VERSION "1.11.2"

NS_ :

BS_:

BU_: TCU BRK ESP MCU RDD GP TMS GW KPD1 RDE FNR ECU KPD2 ATSGO ACU IMU1 IMU2 IMU3 IMU4 IMU5 AGW PMI HDOQS EGOQS OBC EEC CBSW EJRH EJLH EPDLT EPDL2 EPDLR EPDLA TRBDZ ECU1 CLST LC510 EGDL JS SMB KPAC ACCU Audio TGU RDRR RDLH RDRH AVM CHMSL CTC SMK EVC MCU2 PHM MC3D AMBLMP RCTGU RDU PT3D XCU can1 can2
VAL_TABLE_ BOOL 3 "NOT_AVAILABLE" 2 "ERROR" 1 "TRUE" 0 "FALSE" ;
VAL_TABLE_ PWRDNCMD 3 "NOT_AVAILABLE" 2 "EMERGENCY_POWER_DOWN" 1 "NORMAL_POWER_DOWN" 0 "NOT_REQUEST" ;
VAL_TABLE_ OFFON 3 "NOT_AVAILABLE" 2 "ERROR" 1 "ON" 0 "OFF" ;
VAL_TABLE_ NONEOFFON 3 "NOT_AVAILABLE" 2 "ON" 1 "OFF" 0 "NONE" ;
VAL_TABLE_ MACHINESTATUS 3 "NOT_AVAILABLE" 2 "KEY_OFF_CHARGING" 1 "KEY_ON" 0 "KEY_OFF" ;
VAL_TABLE_ CHARGINGSTATUS 5 "EVSE_SIGNOT_AVAILABLEL_WARNING" 4 "AC_VOLTAGE_BELOW_NORMAL" 3 "AC_VOLTAGE_ABOVE_NORMAL" 2 "CHARGING_GUN_WARNING" 1 "CHARGING_PORT_WARNING" 0 "CHARGING" ;
VAL_TABLE_ WRNLAMP 3 "SLOW_BLINKING" 2 "BLINKING" 1 "ON" 0 "OFF" ;
VAL_TABLE_ WRNLAMPTXT 15 "SLOW_BLINKING_TEXT4" 14 "BLINKING_TEXT4" 13 "ON_TEXT4" 12 "NOT_DEFINED3" 11 "SLOW_BLINKING_TEXT2" 10 "BLINKING_TEXT2" 9 "ON_TEXT2" 8 "NOT_DEFINED2" 7 "SLOW_BLINKING_TEXT3" 6 "BLINKING_TEXT3" 5 "ON_TEXT3" 4 "NOT_DEFINED1" 3 "SLOW_BLINKING_TEXT1" 2 "BLINKING_TEXT1" 1 "ON_TEXT1" 0 "OFF" ;
VAL_TABLE_ ANTDETECT 2 "SHORTED" 1 "REMOVAL" 0 "NORMAL" ;
VAL_TABLE_ TRVMODECR 3 "NOT_AVAILABLE" 2 "AUTO_SPEED" 1 "HIGH_SPEED" 0 "LOW_SPEED" ;
VAL_TABLE_ WRKMODE 3 "RESERVED" 2 "TWO_WAY" 1 "BREAKER" 0 "NOT_DEFINED" ;
VAL_TABLE_ GPSST 3 "3D" 2 "2D" 1 "NO_FIX" 0 "UNKNOWN" ;
VAL_TABLE_ SMKFOBREG 3 "FAIL2" 2 "FAIL1" 1 "SUCCESS" 0 "NORMAL" ;
VAL_TABLE_ SMKFOBDET 1 "DETECT_REQUEST" 0 "DEFAULT" ;
VAL_TABLE_ SMKFOBIDREQ 1 "REQUEST" 0 "DEFAULT" ;
VAL_TABLE_ CMDONOFF 3 "NOT_AVAILABLE" 2 "OFF" 1 "ON" 0 "NO_ACTION" ;
VAL_TABLE_ EGSTARTCMD 3 "KEY_ON" 2 "ENGINE_OFF" 1 "ENGINE_ON" 0 "NONE" ;
VAL_TABLE_ COLDSTART 8 "TEST_OF_GRID_HEATER_VOLTAGE" 7 "INITIALIZATION_PHASE" 6 "POST_HEATING_PHASE" 5 "CRANK_WITH_EXTRA_HEATING_PHASE" 4 "CRANK_PHASE" 3 "STAND_BY_PHASE_WITHOUT_HEATING" 2 "STAND_BY_PHASE_WITH_HEATING" 1 "PRE_HEATING_PHASE" 0 "OFF_PHASE_HEAT_OFF_AND_LAMP_OFF" ;
VAL_TABLE_ FUELBLOCK 1 "FUEL_BLOCKED" 0 "FUEL_RELEASED" ;
VAL_TABLE_ LAMPST 3 "NOT_AVAILABLE" 2 "BLINKING" 1 "ON" 0 "OFF" ;
VAL_TABLE_ WRNHIGH 3 "NOT_AVAILABLE" 2 "RESERVED" 1 "ABOVE_OPERATION_RANGE" 0 "NORMAL" ;
VAL_TABLE_ LAMPBITST 4 "BLINKING" 1 "ON" 0 "OFF" ;
VAL_TABLE_ WRNLOW 3 "NOT_AVAILABLE" 2 "RESERVED" 1 "BELOW_OPERATION_RANGE" 0 "NORMAL" ;
VAL_TABLE_ WRN 3 "NOT_AVAILABLE" 2 "RESERVED" 1 "WARNING" 0 "NORMAL" ;
VAL_TABLE_ EDCOPRST 2 "DIAGNOSTIC_TEST" 1 "AFTERRUN_DRIVE" 0 "NORMAL_OPERATION" ;
VAL_TABLE_ PTOST 31 "NOT_AVAILABLE" 19 "PTO_SET_SPEED_MEMORY_2" 18 "PTO_SET_SPEED_MEMORY_1" 17 "PREPROGRAMMED_SET_SPEED_8" 16 "PREPROGRAMMED_SET_SPEED_7" 15 "PREPROGRAMMED_SET_SPEED_6" 14 "PREPROGRAMMED_SET_SPEED_5" 13 "PREPROGRAMMED_SET_SPEED_4" 12 "PREPROGRAMMED_SET_SPEED_3" 11 "PREPROGRAMMED_SET_SPEED_2" 10 "PREPROGRAMMED_SET_SPEED_1" 9 "ACCELERATOR_OVERRIDE" 8 "ACCELERATE" 7 "RESUME" 6 "DECELERATE_COAST" 5 "SET" 4 "REMOTE_STANDBY" 3 "STANDBY" 2 "REMOTE_HOLD" 1 "HOLD" 0 "OFF_DISABLED" ;
VAL_TABLE_ DPFACTREGENST 3 "NOT_AVAILABLE" 2 "REGENERATION_NEEDED" 1 "ACTIVE" 0 "NOT_ACTIVE" ;
VAL_TABLE_ DPFACTREGENIHBSW 3 "NOT_AVAILABLE" 1 "INHIBITED" 0 "NOT_INHIBITED" ;
VAL_TABLE_ ATDEFPPT 15 "NOT_AVAILABLE" 14 "ERROR" 13 "NOT_ABLE_TO_DETERMINE" 3 "DEF_IS_PROPER_MIXTURE" 2 "FLUID_IS_DIESEL" 1 "UREA_CONCENTRATION_TOO_LOW" 0 "UREA_CONCENTRATION_TOO_HIGH" ;
VAL_TABLE_ ATSELCATALREDOPRINDACT 7 "NOT_AVAILABLE" 4 "BLINKING" 1 "ON" 0 "OFF" ;
VAL_TABLE_ ATGASSSHTCONT 3 "HEATER_OFF" 2 "PREHEAT_1" 1 "PREHEAT_2" 0 "AUTOMATIC" ;
VAL_TABLE_ EGOVRCONTMD 3 "SPEED_TORQUE_LIMIT_CONTROL" 2 "TORQUE_CONTROL" 1 "SPEED_CONTROL" 0 "OVERRIDE_DISABLED" ;
VAL_TABLE_ PRI 3 "LOW" 2 "MEDIUM" 1 "HIGH" 0 "HIGHEST" ;
VAL_TABLE_ TRACTIONCONT 4 "AUTO" 3 "HIGH" 2 "MEDIUM" 1 "LOW" 0 "OFF" ;
VAL_TABLE_ POWMD 3 "NOT_AVAILABLE" 2 "PWR" 1 "STD" 0 "ECO" ;
VAL_TABLE_ MAXSPD 5 "SPEED_5" 4 "SPEED_4" 3 "SPEED_3" 2 "SPEED_2" 1 "SPEED_1" 0 "NEUTRAL" ;
VAL_TABLE_ RPMREQMD 3 "NONE" 1 "LIMPHOME" 0 "AUTOIDLE" ;
VAL_TABLE_ NFR 3 "TCU_REQUIRES_N_POSITION" 2 "R" 1 "F" 0 "N" ;
VAL_TABLE_ GRST 7 "LIMP_HOME" 6 "GEAR_6" 5 "GEAR_5" 4 "GEAR_4" 3 "GEAR_3" 2 "GEAR_2" 1 "GEAR_1" 0 "NEUTRAL" ;
VAL_TABLE_ OPMD 6 "TCU_IDLE" 5 "TCU_KEY_OFF" 4 "TCU_SHUTDOWN" 3 "TRANSMISSION_SHUTDOWN" 2 "LIMP_HOME" 1 "SUBSTITUTE_CLUTCH_CONTROL" 0 "NORMAL" ;
VAL_TABLE_ MCHKEYONST 3 "NOT_DEFINED" 2 "KEY_OFF_CHARGING" 1 "KEY_ON" 0 "KEY_OFF" ;
VAL_TABLE_ CHRGST 5 "EVSE_SIGNOT_AVAILABLEL_WARNING" 4 "AC_VOLTAGE_BELOW_NORMAL" 3 "AC_VOLTAGE_ABOVE_NORMAL" 2 "CHARGING_GUN_WARNING" 1 "CHARGING_PORT_WARNING" 0 "CHARGING" ;
VAL_TABLE_ TRVMDCRW 3 "NOT_AVAILABLE" 2 "AUTO_SPEED" 1 "HIGH_SPEED" 0 "LOW_SPEED" ;
VAL_TABLE_ TWOWAYOPT 2 "OPTION_PEDAL" 1 "JOYSTICK_THUMB_WHEEL" 0 "NOT_DEFINED" ;
VAL_TABLE_ ISOBHL 2 "BHL" 1 "ISO" 0 "OFF" ;
VAL_TABLE_ TRVMDWHL 3 "NOT_DEFINED" 2 "3" 1 "2" 0 "1" ;
VAL_TABLE_ HHMNTLGC 3 "4000M_EXCEED" 2 "4000M_OR_LESS" 1 "3000M_OR_LESS" 0 "OFF" ;
VAL_TABLE_ BRAKERACT 3 "NOT_AVAILABLE" 2 "FORCED_STOP" 1 "RUNNING" 0 "STOP" ;
VAL_TABLE_ TRVMDWLD 3 "NOT_DEFINED" 2 "AUTO_SPEED_2" 1 "AUTO_SPEED_1" 0 "MANUAL" ;
VAL_TABLE_ HSTMDWLD 3 "NOT_DEFINED" 2 "SLIP" 1 "AUTO" 0 "MAX" ;
VAL_TABLE_ OPRPOWMD 11 "P_SMART_HCE" 10 "AP_HCE" 9 "HP_HCE" 8 "P_HCE" 7 "E_HCE" 6 "L_HCE" 5 "I_HCE" 4 "P_PLUS_HDI" 3 "A_HDI" 2 "E_HDI" 1 "S_HDI" 0 "P_HDI" ;
VAL_TABLE_ OPRMD 1 "DIGGING" 0 "NORMAL" ;
VAL_TABLE_ COLDSTART_MCU 7 "NORMAL_BLINKING" 6 "SLOW_BLINKING" 5 "FAULT_WHILE_PRE_HEATING" 4 "PARKING_BRAKE_FOR_PRE_HEATING" 3 "NO_FOOT_ON_PDL_FOR_PRE_HEAT" 2 "GEAR_NEUTRAL_FOR_PRE_HEATING" 1 "TRSM_PRE_HEATING" 0 "OFF" ;
VAL_TABLE_ WHLDRVMD 3 "ALIGNCOMPLETE" 2 "REARALIGNREQ" 1 "FRONTALIGNREQ" 0 "OFF" ;
VAL_TABLE_ VHCSTSYMB 3 "YELLOW" 2 "GREEN" 1 "GREY" 0 "OFF" ;
VAL_TABLE_ DAC 5 "SUSPEND_AUTO" 4 "INTERLOCK" 3 "AUTO" 2 "MANUAL" 1 "STAND_BY" 0 "NOT_READY" ;
VAL_TABLE_ CHMSL 6 "OBJECT_SENSING_FAST_FLASHING" 5 "SWING_LEFT" 4 "SWING_RIGHT" 3 "WORKING_STATUS_FLASHING" 2 "STANDBY_WORKING_CONTINUOUS" 1 "BRAKE_ON" 0 "OFF" ;
VAL_TABLE_ MCHCOND 3 "STANDSTILL_CONDITION" 2 "ERROR" 1 "WORKING_CONDITION" 0 "IDLE_CONDITION" ;
VAL_TABLE_ PILOTCUTOFFST 3 "NOT_AVAILABLE" 2 "AUTO_LOCK" 1 "MANUAL_LOCK" 0 "UNLOCK" ;
VAL_TABLE_ BODYST 3 "NOT_DEFINED" 2 "FLOAT" 1 "HOLD" 0 "OFF" ;
VAL_TABLE_ ECOSYMBOL 3 "WHITE" 2 "RED" 1 "YELLOW" 0 "GREEN" ;
VAL_TABLE_ PROGRESS 3 "NOT_AVAILABLE" 2 "COMPLETE" 1 "IN_PROGRESS" 0 "NONE" ;
VAL_TABLE_ PROGRESS2 1 "COMPLETE" 0 "IN_PROGRESS" ;
VAL_TABLE_ MANAUTO 3 "NOT_AVAILABLE" 2 "ERROR" 1 "AUTO" 0 "MANUAL" ;
VAL_TABLE_ ADMINSET 4 "ENTERTAINMENT_RESTRICT" 2 "ATTACHMENT" 1 "IGNITION_LOCK" 0 "NONE" ;
VAL_TABLE_ UPTIME 3 "NOT_AVAILABLE" 2 "5MIN" 1 "1MIN" 0 "ALWAYS" ;
VAL_TABLE_ HYDELEC 2 "ELECTRONIC" 1 "ELECTRIC" 0 "HYDRAULIC" ;
VAL_TABLE_ JOYPDL 2 "OPTION_PEDAL" 1 "JOYSTICK" 0 "NOT_AVAILABLE" ;
VAL_TABLE_ THMBWHL 2 "FAST" 1 "NORMAL" 0 "SLOW" ;
VAL_TABLE_ MULTIFUNC 7 "NOT_DEFINED" 6 "FRONT_LIMITATION" 5 "AUTO_BREAKER" 4 "AUDIO_MUTE" 3 "RAM_LOCK__STATUS_CHANGE" 2 "CAMERA_VIEW_MODE_CHANGE" 1 "SMART_BOOM_CUT" 0 "WIPER_ON" ;
VAL_TABLE_ EMSCTRL 128 "NOT_AVAILABLE" 5 "NR4" 4 "STAGEV" 3 "TIER4F" 2 "TIER4I" 1 "TIER3" 0 "TIER2" ;
VAL_TABLE_ MCHGEN 224 "D" 133 "G" 132 "SD" 131 "S" 130 "K" 129 "H" 128 "DL" 108 "AGK" 96 "JD" 5 "W" 4 "B" 3 "C" 2 "V" 1 "U" 0 "DX" ;
VAL_TABLE_ MCHTYPE 14 "ADT" 13 "ROAD_BUILDER" 12 "COMPACT_TRACK_LOADER" 11 "DRILL_RIG" 10 "MATERIAL_HANDLER_WHEEL" 9 "MATERIAL_HANDLER" 8 "DOZER" 7 "LOADER" 6 "WHEEL" 5 "MOUNTAIN" 4 "ZERO_TAIL" 3 "REDUCED_TAIL" 2 "LOGLOADER" 1 "LONG_CRAWLER" 0 "CRAWLER" ;
VAL_TABLE_ EGMAKER 10 "WEICHAI" 9 "KUBOTA" 8 "DAEDONG" 7 "YANMAR" 5 "ISUZU" 4 "PERKINS" 3 "CUMMINS" 2 "SCANIA" 1 "DEVELON" 0 "NONE" ;
VAL_TABLE_ ECUMAKER 15 "ECU_MAKER_2" 14 "KUBOTA" 13 "BOSCH_DX05_DX08" 12 "PERKINS_2506J_UNIFIED" 11 "WEIFU" 10 "BOSCH_EDC7" 9 "WOODWARD" 8 "PERKINS_1204J" 7 "HITACHI" 6 "BOSCH_G2" 5 "ISUZU" 4 "PERKINS_2506J" 3 "CUMMINS" 2 "SCANIA" 1 "BOSCH_DL06_DL08" 0 "NONE" ;
VAL_TABLE_ PMPTYPE 4 "LS" 3 "VBO" 2 "OPEN_CENTER" 1 "POSICON" 0 "NEGACON" ;
VAL_TABLE_ MECHELEC 1 "ELECTRIC" 0 "MECHANIC" ;
VAL_TABLE_ MCVCTRLTYPE 2 "FEH" 1 "VBO" 0 "MECHANIC" ;
VAL_TABLE_ TCUTYPE 3 "HDT_LEVEL1" 2 "CVT" 1 "HST" 0 "HDT" ;
VAL_TABLE_ REGION 4 "US" 3 "EMERGING" 2 "ADVANCED" 1 "CHINA" 0 "KOREA" ;
VAL_TABLE_ BTN 3 "NOT_AVAILABLE" 2 "PROPOTIONOT_AVAILABLEL" 1 "TOGGLE" 0 "PUSH" ;
VAL_TABLE_ GYR 2 "RED" 1 "YELLOW" 0 "GREEN" ;
VAL_TABLE_ WGHST 5 "CONFIRM_TRUCK_TIP_OFF" 4 "ESTIMATE_TRUCK_TIP_OFF" 3 "COMPLETE" 2 "CONFIRM" 1 "ESTIMATE" 0 "READY" ;
VAL_TABLE_ WGHCNTST 3 "NOT_DEFINED" 2 "RETURN" 1 "CANCEL" 0 "OFF" ;
VAL_TABLE_ STAGE 15 "ERROR" 14 "SUCCESS" 13 "LAST_STAGE_CONFIRM" 12 "STAGE_11" 11 "STAGE_10" 10 "STAGE_9" 9 "STAGE_8" 8 "STAGE_7" 7 "STAGE_6" 6 "STAGE_5" 5 "STAGE_4" 4 "STAGE_3" 3 "STAGE_2" 2 "STAGE_1" 1 "STAGE_0" 0 "RESERVED" ;
VAL_TABLE_ STEP 15 "STEP14" 14 "STEP13" 13 "STEP12" 12 "STEP11" 11 "STEP10" 10 "STEP9" 9 "STEP8" 8 "STEP7" 7 "STEP6" 6 "STEP5" 5 "STEP4" 4 "STEP3" 3 "STEP2" 2 "STEP1" 1 "STEP0" 0 "READY" ;
VAL_TABLE_ GRADEOFFSETSW 15 "NOT_AVAILABLE" 14 "ERROR" 2 "DECREMENT_BUTTON_PRESSED" 1 "INCREMENT_BUTTON_PRESSED" 0 "NO_BUTTON_PRESSED" ;
VAL_TABLE_ BLADEAUTOMD 15 "NOT_AVAILABLE" 14 "ERROR" 4 "AUTO_NOT_ALLOWED" 3 "SERVICE_MODE" 2 "SUSPEND_AUTO" 0 "AUTO_ALLOWED" ;
VAL_TABLE_ TMSSTINFO01 1 "SECURITY" 0 "SECURITY_CLEAR" ;
VAL_TABLE_ VWMD 15 "NOT_AVAILABLE" 5 "BOOM" 4 "3D" 3 "TOPPLUSREAR" 2 "RIGHT" 1 "REAR" 0 "TOP" ;
VAL_TABLE_ PRIMD 1 "PRIORITY_MODE" 0 "NORMAL_MODE" ;
VAL_TABLE_ FACTORYTYPE 3 "FACTORY_4" 2 "FACTORY_3" 1 "FACTORY_2" 0 "FACTORY_1" ;
VAL_TABLE_ VHCTYPE1 1 "CRAWLER" 0 "WHEEL" ;
VAL_TABLE_ VHCTYPE2 3 "NOT_DEFINED" 2 "LL" 1 "LCR" 0 "LC" ;
VAL_TABLE_ ULTSRECOGNITIONDISTANCESET 1 "UPPER_BODY" 0 "ALL" ;
VAL_TABLE_ BOOMCAMOPT 1 "BOOM_CAMERA_ENABLED" 0 "BOOM_CAMERA_DISABLED" ;
VAL_TABLE_ ONOFFST 1 "OFF" 0 "ON" ;
VAL_TABLE_ OPT 1 "OPTION_EABLED" 0 "OPTION_DISABLED" ;
VAL_TABLE_ DISENABLE 1 "ENABLE" 0 "DISABLE" ;
VAL_TABLE_ TOLERANCECORCMD 3 "TOLERANCE_CORRECTION_FAIL" 2 "TOLERANCE_CORRECTION_COMPLETED" 1 "TOLERANCE_CORRECTING" 0 "BEFORE_TOLERANCE_CORRECTION" ;
VAL_TABLE_ TOLERANCECORMENUENTRYCMD 1 "ENTER_TOLERANCE_CORRECTION" 0 "NO_TOLERANCE_CORRECTION_MENU" ;
VAL_TABLE_ CAMPRMTCORCOMPLETEST 1 "CORRECTION_COMPLETED" 0 "NOT_CORRECTED" ;
VAL_TABLE_ PWRMDST 3 "POWER_MODE" 2 "POWER_PLUS_MODE" 1 "ECONOMY_MODE" 0 "STANDARD_MODE" ;
VAL_TABLE_ WRKMDST 3 "TRVMODECR" 2 "BREAKER" 1 "LIFT" 0 "DIG" ;
VAL_TABLE_ LOCKST 1 "LOCK" 0 "UNLOCK_" ;
VAL_TABLE_ TRACTIONMDST 4 "AUTO" 3 "C_1" 2 "B_2" 1 "A_3" 0 "MAX" ;
VAL_TABLE_ KEYPADPRI 1 "VIRTUAL_KEPAD" 0 "KEYPAD" ;
VAL_TABLE_ EVMDCMD 3 "NOT_AVAILABLE1" 2 "NOT_AVAILABLE" 1 "EV_MODE" 0 "NORMAL_MODE" ;
VAL_TABLE_ ATTTYPE 1 "TWO_WAY" 0 "BREAKER" ;
VAL_TABLE_ ALARMST 5 "ALARM__5" 4 "ALARM__4" 3 "ALARM__3" 2 "ALARM__2" 1 "ALARM__1" 0 "ALARM_OFF" ;
VAL_TABLE_ MGSOUNDGUDSTEP 9 "ALARM__9" 8 "ALARM__8" 7 "ALARM__7" 6 "ALARM__6" 5 "ALARM__5" 4 "ALARM__4" 3 "ALARM__3" 2 "ALARM__2" 1 "ALARM__1" 0 "ALARM_OFF" ;
VAL_TABLE_ OPTSETJOYPATTERNCHANGE 6 "CTL_H" 5 "CTL_ISO" 4 "SCM" 3 "KOBE" 2 "MHI" 1 "BHL_FOR_CTL_BACKHOE" 0 "ISO_FOR_CTL_EXC" ;
VAL_TABLE_ AUDIOAUXSEL 3 "NOT_AVAILABLE" 2 "ERROR" 1 "ON" 0 "OFF" ;
VAL_TABLE_ REQCALLINDEX 10 "10TH_INDEX" 9 "9TH_INDEX" 8 "8TH_INDEX" 7 "7TH_INDEX" 6 "6TH_INDEX" 5 "5TH_INDEX" 4 "4TH_INDEX" 3 "3RD_INDEX" 2 "2ND_INDEX" 1 "1ST_INDEX" 0 "NONE" ;
VAL_TABLE_ DT02GPTYPE 1 "S_T_8INCH_GP" 0 "S_T_7INCH_GP" ;
VAL_TABLE_ GSPNIDENTIFIER 1 "GSPN" 0 "SPN" ;
VAL_TABLE_ PDLCALB 2 "MAX_PUSHED_CAL_CMD" 1 "MAX_RELEASE_CAL_CMD" 0 "CALIBRATION_READY_CMD" ;
VAL_TABLE_ JOYSTICK 3 "NOT_DEFINED" 2 "FAST" 1 "NORMAL" 0 "SMOOTH" ;
VAL_TABLE_ NOINREQ 1 "COMPLETE" 0 "START" ;
VAL_TABLE_ DOORLCKST 3 "NOT_AVAILABLE" 2 "UNLOCK" 1 "LOCK" 0 "NONE" ;
VAL_TABLE_ NONEONOFF 3 "FAILED" 2 "OFF" 1 "ON" 0 "NONE" ;
VAL_TABLE_ FOBRGSTFDBK 3 "NOT_AVAILABLE" 2 "DETECTION_COMPLETED" 1 "NOT_DETECTION" 0 "NONE" ;
VAL_TABLE_ BLINKING 3 "ON_SLOW_BLINKING" 2 "ON_NORMAL_BLINKING" 1 "ON_NO_BLINKING" 0 "OFF" ;
VAL_TABLE_ KEYSTCHANGE 3 "CRANK_RUN" 2 "KEY_ON" 1 "ACC" 0 "KEY_OFF" ;
VAL_TABLE_ DETECT 1 "DETECT" 0 "NO_DETECT" ;
VAL_TABLE_ OPENCLOSE 1 "CLOSE" 0 "OPEN" ;
VAL_TABLE_ RMRUNNINGST 1 "REMOTE_RUNNING_STATUS" 0 "NORMAL_STATUS" ;
VAL_TABLE_ ACTIVATION 1 "ACTIVATION" 0 "NO_ACTIVATION" ;
VAL_TABLE_ ACTIVE 3 "NOT_AVAILABLE" 2 "RESERVED" 1 "ACTIVE" 0 "INACTIVE" ;
VAL_TABLE_ DRTINDICATION 3 "NOT_AVAILABLE" 2 "ERROR" 1 "REVERSE" 0 "FORWARD" ;
VAL_TABLE_ IFCONFIGUREDASPRPTA 0 "ALWAYS" ;
VAL_TABLE_ STRMDREQ 1 "OPERATING" 0 "NOT_OPERATING" ;
VAL_TABLE_ AUXSTRDEVICELCKOUT 3 "NOT_AVAILABLE" 2 "RESERVED" 1 "AUX_STEERING_PROHIBITED" 0 "AUX_STEERING_ALLOWED" ;
VAL_TABLE_ AUTOGUDRECVSELANDLCKOUT 3 "RESERVED" 2 "GPS_2_STEERING_SELECTED" 1 "GPS_STEERING_SELECTED" 0 "NO_GPS_RECEV_SEL_GPS_STR_PROH" ;
VAL_TABLE_ TRVLSPDSET 3 "PRESET_4" 2 "PRESET_3" 1 "PRESET_2" 0 "PRESET_1" ;
VAL_TABLE_ SPD 10 "SPEED_5" 9 "SPEED_4.5" 8 "SPEED_4" 7 "SPEED_3.5" 6 "SPEED_3" 5 "SPEED_2.5" 4 "SPEED_2" 3 "SPEED_1.5" 2 "SPEED_1" 1 "SPEED_0.5" 0 "SPEED_0" ;
VAL_TABLE_ CURPWRMD 3 "NOT_AVAILABLE" 2 "PWR" 1 "STD" 0 "ECO" ;
VAL_TABLE_ MNAUTOMDST 3 "RESERVED" 2 "AUTO" 1 "NOT_AVAILABLE" 0 "MANUAL" ;
VAL_TABLE_ MDST 3 "RESERVED" 2 "ENAEBLE" 1 "NOT_AVAILABLE" 0 "DISABLE" ;
VAL_TABLE_ OUTTAKEINTAKEMDST 3 "RESERVED" 2 "INTAKE_MODE" 1 "NOT_AVAILABLE" 0 "OUTTAKE_MODE" ;
VAL_TABLE_ VHCSTSYBACOFFIND 3 "BLINK_SLOW_BLINK" 2 "BLINK_NORMAL_BLINK" 1 "ON_NO_BLINKING" 0 "OFF" ;
VAL_TABLE_ OUTREQ 3 "NOT_AVAILABLE" 2 "ERROR" 1 "ON" 0 "OFF" ;
VAL_TABLE_ OUTFDBKCUR 255 "NOT_AVAILABLE" 254 "ERROR" ;
VAL_TABLE_ ERRORFLAG 255 "ERROR" 0 "NONE" ;
VAL_TABLE_ NOROPENSHORT 2 "SHORT" 1 "OPEN" 0 "NORMAL" ;
VAL_TABLE_ RESOLUTIONMD 3 "DONT_CARE" 2 "RESERVED" 1 "HIGH_RESOLUTION" 0 "STANDARD_RESOLUTION" ;
VAL_TABLE_ VVST 15 "NOT_AVAILABLE" 3 "FLOAT" 2 "RETRACT" 1 "EXTEND" 0 "BLOCK" ;
VAL_TABLE_ FAILSAFEMD 3 "DONT_CARE" 2 "RESERVED" 1 "EXTEND" 0 "BLOCK" ;
VAL_TABLE_ AVMLANGUAGEPACK 24 "VIETNAMESE" 23 "GREEK" 22 "THAI" 21 "HINDI" 20 "FARSI_PERSIAN" 19 "ARABIC_SAUDI_ARABIA" 18 "RUSSIAN" 17 "POLISH" 16 "INDONESIAN" 15 "TURKISH" 14 "JAPANESE" 13 "DANISH" 12 "NORWEGIAN_BOKMAL" 11 "SWEDISH" 10 "FINNISH" 9 "SPANISH_INTERNATIONAL" 8 "PORTUGUESE_PORTUGAL" 7 "ITALIAN_ITALY" 6 "DUTCH_NETHERLANDS" 5 "GERMAN_GERMANY" 4 "FRENCH_FRANCE" 3 "CHINESE_PRC" 2 "ENGLISH" 1 "KOREAN_DEFAULT" 0 "NOTUSED" ;
VAL_TABLE_ AVMVW 15 "NOT_AVAILABLE" 5 "BOOM_OPTION" 4 "3D" 3 "REAR_PLUS_CORNER" 2 "TOP_PLUS_RIGHT" 1 "REAR_WIDE" 0 "TOPVIEW" ;
VAL_TABLE_ AVMOUTTYPE 7 "INVALID" 6 "ERROR" 2 "AVM_OUTPUT_TYPE_LVDS" 1 "AVM_OUTPUT_TYPE_NTSC" 0 "NOT_USED" ;
VAL_TABLE_ AVMDISPLAYMSG 255 "INVALID" 254 "ERROR" 63 "WARNING_CHECK_BACK_RIGHT_LEFT" 62 "WARNING_CHECK_FRONT_RIGHT_LEFT" 2 "INCAMERACALIBARION_MODE" 1 "NO_MESSAGE" 0 "NOT_USED" ;
VAL_TABLE_ AVMTONSIZE 15 "INVALID" 14 "ERROR" 5 "30T_CRAWLER" 4 "21T_WHEEL" 3 "14T_WHEEL" 2 "5T_WHEEL" 1 "5T_CRAWLER" 0 "NOT_USED" ;
VAL_TABLE_ AVMULTRABZ 15 "INVALID" 14 "ERROR" 7 "LEFT_RIGHT_REAR_ACTIVATION" 6 "RIGHT_REAR_ACTIVATION" 5 "LEFT_RIGHT_ACTIVATION" 4 "LEFT_REAR_ACTIVATION" 3 "REAR_ACTIVATION" 2 "RIGHR_ACTIVATION" 1 "LEFT_ACTIVATION" 0 "ULTRASONIC_ALL_OFF" ;
VAL_TABLE_ AVMST 31 "INVALID" 30 "ERROR" 3 "AVM_FAIL" 2 "AVM_NORMAL_IGN_ON" 1 "AVM_NOT_READY_IGN_OFF" 0 "NOT_USED" ;
VAL_TABLE_ AVMWARNGUD 7 "INVALID" 6 "ERROR" 2 "AVM_WARNING_GUIDE_LINE_ON" 1 "AVM_WARNING_GUIDE_LINE_OFF" 0 "NOT_USED" ;
VAL_TABLE_ ULTSSIG 15 "INVALID" 14 "ERROR" 5 "NOISE_ERROR" 4 "FAULT" 3 "LEVEL_3" 2 "LEVEL_2" 1 "LEVEL_1" 0 "OFF" ;
VAL_TABLE_ WORKING 1 "WORKING" 0 "NOT_WORKING" ;
VAL_TABLE_ HTPADST 1 "ON_BOARD_CHARGER" 0 "OFF" ;
VAL_TABLE_ CHGST 7 "NOT_AVAILABLE" 6 "CHARGER_ERROR" 5 "RESERVED" 4 "PAUSE" 3 "COMPLETE" 2 "FAILURE" 1 "CHARGING" 0 "STANDBY" ;
VAL_TABLE_ BMSCHGSOURCETYPE 3 "NOT_AVAILABLE" 2 "QUICK_CHARGER" 1 "ON_BOARD_CHARGER" 0 "NONE" ;
VAL_TABLE_ SCRTYCMD 3 "NOT_AVAILABLE" 2 "ENGINE_LOCK" 1 "RPM_LIMIT" 0 "NORMAL" ;
VAL_TABLE_ GPSANTST 3 "NOT_AVAILABLE" 2 "SHORTEN" 1 "REMOVED" 0 "NORMAL" ;
VAL_TABLE_ KEYTYPE 4 "REMOTE" 3 "KEYLESS" 2 "DIGITAL_KEY" 1 "FOB" 0 "NONE" ;
VAL_TABLE_ TYPE 7 "NOT_AVAILABLE" 3 "5G" 2 "4G" 1 "3G" 0 "2G" ;
VAL_TABLE_ OFFWARN 2 "WARNING_LEVEL2" 1 "WARNING_LEVEL1" 0 "OFF" ;
VAL_TABLE_ FOBCERT 3 "LOCK" 2 "FAIL" 1 "SUCCESS" 0 "NONE" ;
VAL_TABLE_ FOBDTTREQ 3 "REQUEST" 2 "NOT_AVAILABLE1" 1 "NOT_AVAILABLE" 0 "DEFAULT" ;
VAL_TABLE_ FOBIDREQ 3 "NOT_REQUEST2" 2 "NOT_REQUEST1" 1 "REQ_TO_SEND_REGISTERED_FOB_ID" 0 "NOT_REQUEST" ;
VAL_TABLE_ DOORLCKSTCHANGE 3 "NOT_AVAILABLE" 2 "OPEN" 1 "CLOSE" 0 "NONE" ;
VAL_TABLE_ NONEONOFFFAIL 3 "FAIL" 2 "HVAC_OFF" 1 "HVAC_ON" 0 "NONE" ;
VAL_TABLE_ ONOFFFAIL 3 "FAIL" 2 "OFF" 1 "ON" 0 "NONE" ;
VAL_TABLE_ RLSFAIL 3 "FAIL" 2 "RELEASE_OFF" 1 "RELEASE" 0 "NONE" ;
VAL_TABLE_ HORN5S 3 "FAIL" 2 "NO_ACTION1" 1 "HORN_ON" 0 "NO_ACTION" ;
VAL_TABLE_ EGSTARTHOLDINGTM 7 "NONE" 6 "NOT_AVAILABLE" 5 "30MIN" 4 "25MIN" 3 "20MIN" 2 "15MIN" 1 "10MIN" 0 "5MIN_DEFAULT" ;
VAL_TABLE_ RMRUNST 1 "REMOTE_START" 0 "NORMAL_STATUS" ;
VAL_TABLE_ ACKNACK 2 "NACK" 1 "ACK" 0 "NOT_ACTIVE" ;
VAL_TABLE_ RESULTOFCRANK 7 "UNKNOWN_FAIL" 6 "NO_CUTOFF" 5 "NO_NEUTRAL" 4 "NO_PARK" 3 "OPEN_CABDOOR" 2 "OPEN_MTDOOR" 1 "SUCCESS" 0 "NONE_TRY" ;
VAL_TABLE_ POSNEGA 1 "NEGATIVE" 0 "POSITIVE" ;
VAL_TABLE_ INVLT 15 "NOT_AVAILABLE" 14 "ERROR" ;
VAL_TABLE_ BZZCTRLCMD 3 "BUZZER_ON_STATE3" 2 "BUZZER_ON_STATE2" 1 "BUZZER_ON_STATE1" 0 "BUZZER_OFF" ;
VAL_TABLE_ VHCSTTRACTIONLV 3 "NOT_DEFINED" 2 "C_1" 1 "B_2" 0 "A_3" ;
VAL_TABLE_ QCKCOOLST 2 "NOT_POSSIBLE_TO_PROCEED" 1 "PROCEEDING" 0 "BEFORE_PROCEEDING" ;
VAL_TABLE_ WGHCONFIRMWARNMSG 6 "POOR_LIFT" 5 "ARM_TOO_FAR" 4 "ARM_TOO_NEAR" 3 "BOOM_TOO_LOW" 2 "BOOM_TOO_HIGH" 1 "SWING_SPEED_TOO_FAST" 0 "OFF" ;
VAL_TABLE_ WHLTYPESTRMD 3 "4WHEEL_MODE_CRAB" 2 "4WHEEL_MODE_ROUND" 1 "2WHEEL_MODE" 0 "OFF" ;
VAL_TABLE_ CURMAXSPDMINOR 1 "STEP_1" 0 "STEP_0" ;
VAL_TABLE_ FNRNTRL 3 "BOTH_NOT_NEUTRAL" 2 "JOYSTICK_NOT_NEUTRAL" 1 "COMBI_SWITCH_NOT_NEUTRAL" 0 "OFF" ;
VAL_TABLE_ WRKTRV 3 "NOT_DEFINED" 2 "GREEN" 1 "GREY" 0 "OFF" ;
VAL_TABLE_ OFFONGY 3 "CONDITION_YELLOW" 2 "CONDITION_GREEN" 1 "ON" 0 "OFF" ;
VAL_TABLE_ TRLHHFLOWMD 2 "XHP_XE_RED" 1 "XPS_ORANGE" 0 "STANDARD_BLUE" ;
VAL_TABLE_ STATE7 7 "STATE_7" 6 "STATE_6" 5 "STATE_5" 4 "STATE_4" 3 "STATE_3" 2 "STATE_2" 1 "STATE_1" 0 "OFF" ;
VAL_TABLE_ STATE3 3 "STATE_3" 2 "STATE_2" 1 "STATE_1" 0 "OFF" ;
VAL_TABLE_ HPAPMD 3 "NOT_AVAILABLE" 2 "AP" 1 "HP" 0 "OFF" ;
VAL_TABLE_ RMCRAKINGST 5 "FAIL_BY_ANOTHER_REASON" 4 "FAIL_BY_PILOT_CUT_OFF_SWITCH" 3 "FAIL_BY_NEUTRAL_SWITCH" 2 "FAIL_BY_PARKING_SWITCH" 1 "SUCCESS" 0 "NONE" ;
VAL_TABLE_ TRVL 3 "NOT_AVAILABLE" 2 "RESERVED" 1 "TRAVELING" 0 "NOT_TRAVELING" ;
VAL_TABLE_ WARNPOPMGMCSSERR 6 "TILT_ROTATOR_ERROR" 5 "XCU_COMMUNICATION_ERROR" 4 "MACHINE_ERROR" 3 "SENSOR_ERROR_PILOT_CUTOFF" 2 "SENSOR_ERROR_TILT" 1 "SS_ERROR_BODY_BOOM_ARM_BCK_SWG" 0 "NONE" ;
VAL_TABLE_ WARNPOPLIMITANGEXCESS 1 "TILTING_IS_NOT_POSSIBLE" 0 "NONE" ;
VAL_TABLE_ NONECHECK 1 "CHECK" 0 "NONE" ;
VAL_TABLE_ OPTSETMCHNAMEINIT 1 "SET" 0 "INITIAL_STAGE" ;
VAL_TABLE_ MCHGENR 133 "G" 132 "SD" 131 "S" 130 "K" 129 "H" 128 "DL" ;
VAL_TABLE_ MAXGRLMT 4 "CVT" 3 "5TH_GEAR_LOCK_UP" 2 "4TH_GEAR" 1 "3RD_GEAR_LIMIT_5TH_TRANSMISSION" 0 "3RD_GEAR_LIMIT_4TH_TRANSMISSION" ;
VAL_TABLE_ REQCD 10 "REPROGRAMMED_VHC_TYPE_ID" 4 "LOG_LOADER" 3 "BLOCK_HANDLER" 0 "COMPARE_VHC_TYPE_ID" ;
VAL_TABLE_ RESULTCD 20 "TCI_ID_MESSAGE_REQUIRED" 11 "REQUEST_ID_NOT_AVAILABLE" 10 "REQUEST_ID_REPROGRAMMED" 1 "VHC_TYPE_ID_DIFFERENT" 0 "VHC_TYPE_ID_IDENTICAL" ;
VAL_TABLE_ ECOGUDCTRL 32 "RECOM_USE_OF_THE_ICCO_FEATURE" 16 "RECOM_LOWERING_THE_ENGINE_MODE" 8 "RECOM_USE_OF_LOCK_UP" 4 "PREVENTION_OF_IDLE_STATE" 2 "RECOM_USE_1_4_AUTO" 1 "RECOM_USE_OF_THE_LIS_FEATURE" ;
VAL_TABLE_ AUTOST 4 "ACTIVATION" 3 "DEACTIVATION" 2 "ARM_REQUESTED" 1 "DISARMED" 0 "INITIALIZED" ;
VAL_TABLE_ INTERLCKST 2 "MACHINE_SAFETY" 1 "TIMEOUT" 0 "NO_LOCKOUT" ;
VAL_TABLE_ FUNCFAULT 4 "MACHINE_FAULT" 2 "RESERVED" 1 "COMMUNICATION_TIMEOUT" 0 "NO_FAULT" ;
VAL_TABLE_ LOCK 3 "NOT_AVAILABLE" 2 "ENGINE_LOCK" 1 "RPM_LIMIT" 0 "NORMAL" ;
VAL_TABLE_ NORRMV 2 "SHORTED" 1 "REMOVAL" 0 "NORMAL" ;
VAL_TABLE_ OUTTAKEINTAKEMDSEL 3 "RESERVED" 2 "NOT_AVAILABLE" 1 "INTAKE_MODE" 0 "OUTTAKE_MODE" ;
VAL_TABLE_ OFFER 255 "ERROR" 0 "OFF" ;
VAL_TABLE_ OFFONACTIVE 3 "RESERVED" 2 "ACTIVE" 1 "ON" 0 "OFF" ;
VAL_TABLE_ READY 1 "READY" 0 "NOT_READY" ;
VAL_TABLE_ ARMREACHIND 3 "RESERVED" 2 "FAR" 1 "MID" 0 "NEAR" ;
VAL_TABLE_ REACH 1 "REACH" 0 "NOT_REACH" ;
VAL_TABLE_ DISARMNOR 3 "NOT_DEFINED" 2 "SERVICE" 1 "NORMAL" 0 "DISARMED" ;
VAL_TABLE_ INTERLOCKREQ 2 "MACHINE_SAFETY" 1 "TIME_OUT" 0 "NO_LOCKOUT_PRESENT_AUTO_ALLOWED" ;
VAL_TABLE_ ACCEPT 1 "ACCEPTED" 0 "NOT_ACCEPTED" ;
VAL_TABLE_ SELMDHEARTBEAT 4 "ACTIVATED" 3 "DEACTIVATION" 2 "ARM_REQUESTED" 1 "DISARMED" 0 "INITIALIZED" ;
VAL_TABLE_ AMBLMPCOLORMD 1 "POWER_MODE_COLOR" 0 "USER_SETTING_COLOR" ;
VAL_TABLE_ PWRMDSEL 3 "ECO" 2 "STANDARD" 1 "POWER" 0 "POWERPLUS" ;
VAL_TABLE_ WRKMDSEL 3 "2WAY" 2 "1WAY" 1 "LIFT" 0 "DIG" ;
VAL_TABLE_ DIALSTEP 12 "STEP_13" 11 "STEP_12" 10 "STEP_11" 9 "STEP_10" 8 "STEP_9" 7 "STEP_8" 6 "STEP_7" 5 "STEP_6" 4 "STEP_5" 3 "STEP_4" 2 "STEP_3" 1 "STEP_2" 0 "STEP_1" ;
VAL_TABLE_ OBJINZONE 7 "NOT_AVAILABLE" 3 "LEVEL_A" 2 "LEVEL_B" 1 "LEVEL_C" 0 "NO_OBJECT_IN_ZONE" ;
VAL_TABLE_ CONNECTED 3 "NOT_AVAILABLE" 2 "CLOUD_CONNECTED" 1 "NETWORK_CONNECTED" 0 "NONE" ;
VAL_TABLE_ PROVISIONED 2 "THING_PROVISIONED" 1 "NETWORK_PROVISIONED" 0 "NONE" ;
VAL_TABLE_ ACTIVENW 3 "ERROR" 2 "WIFI" 1 "CELL" 0 "NONE" ;
VAL_TABLE_ CELLTYPE 7 "NOT_AVAILABLE" 3 "5G" 2 "4G" 1 "3G" 0 "2G" ;
VAL_TABLE_ CELLANTTYPE 3 "NOT_AVAILABLE" 2 "EXTERNAL" 1 "INTERNAL" 0 "NONE" ;
VAL_TABLE_ GSMTYPE 16 "5G_SA" 15 "5G_NSA" 14 "LTE" 13 "UMB" 12 "3XRTT" 11 "1XEVDV" 10 "1XEVDO_REVB" 9 "1XEVDO_REVA" 8 "1XEVDO" 7 "1XRTT" 6 "HSDPA_HSUPA" 5 "HSUPA" 4 "HSDPA" 3 "UMTS" 1 "EDGE" 0 "GPRS" ;
VAL_TABLE_ ANTST 3 "NOT_AVAILABLE" 2 "ERROR2" 1 "ERROR1" 0 "NORMAL" ;
VAL_TABLE_ NONEACTIVE 2 "INACTIVE" 1 "ACTIVE" 0 "NONE" ;
VAL_TABLE_ VHCST 5 "ERROR" 4 "ENGINE_ON" 3 "ACC_ON" 2 "KEY_ON" 1 "KEY_OFF" 0 "BATTERY_DISCONNECT" ;
VAL_TABLE_ STARTUPRSN 6 "REBOOT_REQUEST" 5 "ACCELEROMETER" 4 "CELL" 3 "LOW_BATTERY" 2 "EMERGENCY" 1 "KEY" 0 "RTC" ;
VAL_TABLE_ TMNST 11 "EXIT" 10 "RESTART" 9 "TESTING" 8 "POWER_OFF" 7 "MODULE_EXIT" 6 "SHUT_DOWN" 5 "DEAD_TBAT" 4 "DEEP_SLEEP" 3 "SLEEP_TERMINAL_BATTERY" 2 "SLEEP_MACHINE_BATTERY" 1 "RUNNING" 0 "INIT" ;
VAL_TABLE_ VHCVLT 1 "12V" 0 "24V" ;
VAL_TABLE_ TASKST 3 "GENERAL_FAILURE" 2 "PACKET_LOSS_FAIL" 1 "OFFLINE" 0 "OK" ;
VAL_TABLE_ ERCODE 2 "UNABLE_TO_PARSE_MESSAGE" 1 "SENSOR_VALUE_OUT_OF_RANGE" 0 "NONE" ;
VAL_TABLE_ CMDOPCODE 177 "REQUEST_FILE_V3" 176 "TRANSFER_NETWORK_CONFIGURATION" 165 "SET_DEFAULT_VEHICLE_TYPE_V2" 164 "SMARTKEY_COMMAND" 163 "J1939_REQUEST_V2" 161 "SECURITY_VERIFICATION_COMMAND" 160 "REQUEST_CURRENT_ADT_LOG" 47 "SET_TIMEZONE_V2" 43 "REQUEST_FILE_VERSION_2" 42 "ABORTCOMMAND" 41 "TESTPORTCOMMANDV4" 40 "SBDRANGERESPONSE" 39 "BULK_CONFIGURATION_DOWNLOAD" 38 "BULK_FIRMWARE_DOWNLOAD" 37 "TEST_PORT_COMMAND_QUICK_RES" 36 "TEST_PORT_COMMAND" 35 "SET_DEFAULT_VEHICLE_TYPE" 33 "TURN_OFF_REMOTE_TRACKING" 32 "TURN_OFF_REMOTE_GAUGE" 31 "SET_TIMEZONE" 30 "TURN_ON_REMOTE_TRACKING" 29 "REQUEST_REPORT" 28 "DELETE_TIMEFENCE" 27 "DELETE_GEOFENCE" 26 "SECURITY_CONFIGURATION" 25 "ADD_TIMEFENCE" 24 "ADD_GEOFENCE" 23 "REQUEST_FILE" 22 "REMOTE_GAUGE_ON" 21 "SECURITY_ACTION" 20 "J1939_REQUEST" 19 "KWP_REQUEST" 18 "REBOOT" 17 "OPEN_CAN_TUNNEL" 16 "TRANSFER_FILE" ;
VAL_TABLE_ ACKRESULT 38 "NUM_REQUEST_TYPES" 37 "ABORT_BULK_DOWNLOAD" 36 "FAILED_BULK_DOWNLOAD" 35 "BULK_DOWNLOAD_IN_PROCESS" 34 "FAILED_CURL_RECV_FAILURE" 33 "MULTIPART_DOWNLOAD_ABORTED" 32 "MULTIPART_DOWN_STARTUP_FAILURE" 31 "MULTIPART_DOWNLOAD_FAIL" 30 "MULTIPART_DOWNLOAD_OK" 29 "MULTIPART_DOWNLOAD_START" 28 "FAILED_DOWNLOAD_RECOVERY" 27 "FAILED_RESULTS_FILE_MISSING" 26 "FAILED_TO_UNZIP" 25 "FAILED_DOWNLOAD_TIMEOUT" 24 "FAILED_DOWNLOAD_SIZE_MISMATCH" 23 "FAILED_CURL_TIMEOUT" 22 "INSUFFICIENT_DISK_SPACE" 21 "FAILED_FILE_NOT_FOUND" 20 "FAILED_TO_SEND_PACKET" 19 "FAILED_AUTHENTICATION" 18 "FAILED_NOT_SUPPORTED" 17 "FAILED_MISSING_DEFINITION" 16 "FAILED_SERVICE_NOT_AVAILABLE" 15 "FAILED_ALREADY_STOPPED" 14 "FAILED_ALREADY_ACTIVE" 13 "FAILED_BAD_PARAMETER" 12 "FAILED_TO_WRITE_FILE" 11 "FAILED_TO_DELETE_FILE" 10 "FAILED_TO_OPEN_FILE" 9 "MCP_REQUESTED_EXITED" 8 "PROCESS_INTERRUPTED_BY_A_REBOOT" 7 "FAILED_TO_UPLOAD_FILE" 6 "FAILED_TO_DOWNLOAD_FILE" 5 "TERMINATED_BY_USER" 4 "ALREADY_OPEN" 3 "ENGINE_OFF" 2 "UNKNOWN_COMMAND" 1 "UNKNOWN_FAILURE" 0 "SUCCESS" ;
VAL_TABLE_ SYS_OFFON 1 "ON" 0 "OFF" ;
VAL_TABLE_ ANTST2 3 "ERROR3" 2 "ERROR2" 1 "ERROR1" 0 "NORMAL" ;
VAL_TABLE_ RMCTRLREQ 3 "NOT DEFINED" 2 "SERVICE " 1 "NORMAL" 0 "DISARMED " ;
VAL_TABLE_ RMITLREQ 3 "NOT DEFINED" 2 "MACHINE SAFETY" 1 "TIME OUT" 0 "NO_LOCKOUT_PRESENT_AUTO_ALLOWED" ;
VAL_TABLE_ PWRPLUS 3 "ECO" 2 "STANDARD" 1 "POWER" 0 "POWER+" ;
VAL_TABLE_ MCHMAKER 1 "HCE" 0 "HDI" ;
VAL_TABLE_ GNSSST 4 "GNSS_COMMUNICATION_ERROR" 3 "ERROR_EXCEEDED" 2 "RELEASE_ON_GA" 1 "NOT_FIXED" 0 "NORMAL" ;
VAL_TABLE_ SWGST 3 "NOT_AVAILABLE" 2 "ERROR" 1 "SWING" 0 "STOP" ;
VAL_TABLE_ MNSELFLV 2 "SELF_LEVELING" 1 "MANUAL" 0 "OFF" ;
VAL_TABLE_ STATE2 2 "STATE2" 1 "STATE1" 0 "OFF" ;
VAL_TABLE_ STARTERFAIL 2 "STARTER2_FAIL" 1 "STARTER1_FAIL" 0 "OFF" ;
VAL_TABLE_ REFRESH 1 "REFRESH" 0 "OFF" ;
VAL_TABLE_ LMPCOLORMD 1 "POWER_MODE_COLOR" 0 "USER_SETTING_COLOR" ;
VAL_TABLE_ RMST 2 "NOT_DEFINED" 1 "REMOTE_MODE" 0 "MANUAL_MODE" ;
VAL_TABLE_ RMMETHODST 3 "ERROR" 2 "REMOTE_CONTROL_CONSOLE" 1 "REMOTE_CONTROL_APP" 0 "REMOTE_CONTROL_STATION" ;
VAL_TABLE_ OBJSEQ 9 "OBJECT10" 8 "OBJECT9" 7 "OBJECT8" 6 "OBJECT7" 5 "OBJECT6" 4 "OBJECT5" 3 "OBJECT4" 2 "OBJECT3" 1 "OBJECT2" 0 "OBJECT1" ;
VAL_TABLE_ OTAIM 8 "OTA_FAILURE" 7 "INSTALL_FAILURE_RETRIAL" 6 "INSTALL_COMPLETE" 5 "MACHINE_REBOOTING" 4 "CONTROLLER_REBOOTING" 3 "INSTALL" 2 "DOWNLOAD_FAILURE" 1 "DOWNLOAD_COMPLETE" 0 "DOWNLOAD" ;
VAL_TABLE_ ECUMAKER2 2 "BOSCH_DX22" 1 "WEICHAI_6M33" 0 "ECU_MAKER_1" ;
VAL_TABLE_ DRVENGAGED 3 "NOT AVAILABLE" 2 "ERROR" 1 "DRIVE_LINE_ENGAGED" 0 "DRIVE_LINE_DISENGAGED" ;
VAL_TABLE_ TRQCVT 1 "TRQ_CVT_LOCKUP_ENGAGED" 0 "TRQ_CVT_LOCKUP_DISENGAGED" ;
VAL_TABLE_ PROCESS 1 "PROCESS" 0 "NOT_IN_PROCESS" ;
VAL_TABLE_ CONFIGMODE 2 "ON_PERIODIC" 1 "ON_ANOMALY" 0 "OFF" ;
VAL_TABLE_ OILSTATUS 3 "NOT_AVAILABLE" 2 "ABNORMAL" 1 "WARNING" 0 "NORMAL" ;
VAL_TABLE_ RGST 2 "WARNING" 0 "NORMAL" ;
VAL_TABLE_ VALID 3 "False" 2 "CELL" 1 "GPS" 0 "RTC" ;
VAL_TABLE_ SATTYPE 1 "IRIDIUM" 0 "NONE" ;
VAL_TABLE_ NORERR 1 "ERROR" 0 "NORMAL" ;
VAL_TABLE_ EVNT 4 "STATUS_CHANGE" 3 "GET_REPORT" 2 "ENGINE_OFF" 1 "HALF_HOUR" 0 "ENGINE_ON" ;
VAL_TABLE_ JOYPTN 6 "CTL H" 5 "CTL ISO" 4 "SCM" 3 "KOBE" 2 "MHI" 1 "BHL" 0 "ISO" ;
VAL_TABLE_ STICKSTRTYPE 1 "THUMBWHEEL_STEERING" 0 "JOYSTICK_LEVER" ;
VAL_TABLE_ FNR 2 "R" 1 "N" 0 "F" ;
VAL_TABLE_ LOGEVNT 4 "REQUESTED" 3 "LOG_GENERATED" 2 "LOG_IN_PROGRESS" 1 "LOG_STARTED" 0 "LOG_DELETED" ;
VAL_TABLE_ CONFIGEVNT 2 "DELETED" 1 "MODIFIED" 0 "REQUESTED" ;
VAL_TABLE_ JOYOPTPDL 3 "JOYSTICK_OPTION_PEDAL" 2 "OPTION_PEDAL" 1 "JOYSTICK" 0 "NOT_AVAILABLE" ;
VAL_TABLE_ TRVLSWG 2 "SWING" 1 "TRAVEL" 0 "TRAVEL_SWING" ;
VAL_TABLE_ OPTRTTTYPE 4 "ROTOTILT" 3 "STEELWRIST" 1 "ENCON" 0 "NOT_AVAILABLE" ;
VAL_TABLE_ NORRVS 1 "REVERSE" 0 "NORMAL" ;
VAL_TABLE_ WIPER 2 "BASIC_WIPER_LOW_WIPER" 1 "BASIC_WIPER" 0 "PARALLEL_WIPER" ;
VAL_TABLE_ MGMC 4 "3D_MACHINE_GUIDANCE_SMART_CTRL" 3 "2D_MACHINE_GUIDANCE_SMART_CTRL" 2 "3D_MACHINE_GUIDANCE" 1 "2D_MACHINE_GUIDANCE" 0 "NONE" ;
VAL_TABLE_ FANTYPE 2 "DIRECT_FAN" 1 "FAN_CLUTCH" 0 "HYDRAULIC_FAN" ;
VAL_TABLE_ JOYFUNCBTN 43 "JOYSTICK_DRIVING_ON_OFF" 41 "SMART_BREAKER_ON_OFF" 16 "RESET_TRUCK" 15 "SAVE_TRUCK" 14 "LOAD_BUCKET" 13 "CANCEL_BUCKET" 12 "RE_MEASURE" 11 "WEIGHT_MEASUREMENT_ON_OFF" 5 "AUDIO_MUTE" 4 "WIPER" 3 "TEMP_RESET_OF_INTEL_FLOAT_BOOM" 2 "BREAKER_OR_POWER_UP" 1 "ONE_TOUCH_DECELERATION" 0 "NOT_USED" ;
VAL_TABLE_ AUTOBRKSS 131 "VERY_LOW" 130 "LOW" 129 "SLIGHTLY_LOW" 128 "MEDIUM" 127 "SLIGHTLY_HIGH" 126 "HIGH" 125 "VERY_HIGH" ;
VAL_TABLE_ RTTSPDRATIO 10 "STRONGLY_PREFER_SWING" 9 "PREFER_SWING" 8 "SLIGHTLY_PREFER_SWING" 7 "EQUAL" 6 "SLIGHLTY_PREFER_BOOM" 5 "PREFER_BOOM" 4 "STRONGLY_PREFER_BOOM" ;
VAL_TABLE_ JOYFUNCTHW 13 "DOZER" 11 "ROTATE" 10 "SHARE" 2 "TR_ROTATE" 1 "TR_TILT" 0 "NOT_USED" ;
VAL_TABLE_ ALTEVNT 3 "FIRST_ENGINE_ON" 2 "FIRST_KEY_ON" 1 "GET_REPORT" 0 "STATUS_CHANGE" ;
VAL_TABLE_ EGOILGRD 0 "SAE10W40" ;
VAL_TABLE_ HYDOILGRD 2 "VG68" 1 "VG46" 0 "VG32" ;
VAL_TABLE_ EGDERATING 3 "NOT_AVAILABLE" 2 "ERROR" 1 "DERATING_CONTROL_ON" 0 "DERATING_CONTROL_OFF" ;
VAL_TABLE_ TRACTIONCTRL 2 "SLIP_MODE" 1 "CONTROL_MODE" 0 "MAX" ;
VAL_TABLE_ TRACTIONLVSEL 2 "C" 1 "B" 0 "A" ;
VAL_TABLE_ RANGE 2 "RANGE3" 1 "RANGE2" 0 "RANGE1" ;
VAL_TABLE_ REQEGMD 2 "POWER" 1 "NORMAL" 0 "ECO" ;
VAL_TABLE_ JOYTYPESEL 1 "LOCKER_TYPE" 0 "ELECTRIC_TYPE" ;
VAL_TABLE_ MAXSPDLMT 1 "LIMIT" 0 "UNLIMIT" ;
VAL_TABLE_ AUTOSHIFT 1 "AUTO_HIGH_SPEED" 0 "AUTO_LOW_SPEED" ;
VAL_TABLE_ CHARGINGST 3 "FOD_STATUS" 2 "CHARGING_COMPLETE" 1 "CHARGING" 0 "OFF" ;
VAL_TABLE_ STATESYB 2 "STATE2_GREEN" 1 "STATE1_WHITE" 0 "OFF" ;
VAL_TABLE_ TMSHIFTMD 3 "AUTO_HEAVY" 2 "AUTO_NORMAL" 1 "AUTO_LIGHT" 0 "MANUAL" ;
VAL_TABLE_ TIPOFFASTST 6 "INTERUPT" 5 "COMPLETE" 4 "IN_PROGRESS" 3 "READY" 2 "WAIT" 1 "DISABLE" 0 "OFF" ;
VAL_TABLE_ TIPOFFMNST 3 "IN_PROGRESS" 2 "READY" 1 "DISABLE" 0 "OFF" ;
VAL_TABLE_ VHCCHGST 3 "CANNOT_CHARGE" 2 "CHARGING" 1 "READY_FOR_CHARGING" 0 "OFF" ;
VAL_TABLE_ CHGTYPE 2 "FAST_CHARGING" 1 "SLOW_CHARGING" 0 "OFF" ;
VAL_TABLE_ NORON 1 "ON" 0 "NORMAL_STATUS" ;
VAL_TABLE_ OBJID 10 "OBJECT_0" 9 "OBJECT_1" 8 "OBJECT_2" 7 "OBJECT_3" 6 "OBJECT_4" 5 "OBJECT_5" 4 "OBJECT_6" 3 "OBJECT_7" 2 "OBJECT_8" 1 "OBJECT_9" 0 "OBJECT_10" ;
VAL_TABLE_ OD 4 "LEVEL_D" 3 "LEVEL_C" 2 "LEVEL_B" 1 "LEVEL_A" 0 "NO_OD_IN_ZONE_1" ;
VAL_TABLE_ OVERTURNWARN 2 "OVERTURN_WARNING_2" 1 "OVERTURN_WARNING_1" 0 "OFF" ;
VAL_TABLE_ MC3DREADY 2 "MC_3D_CALIBRATION" 1 "READY" 0 "NOT_READY" ;
VAL_TABLE_ MC3DST 2 "AUTO_SUSPEND" 1 "AUTO" 0 "MANUAL" ;
VAL_TABLE_ OFFREADYON 2 "ON" 1 "READY" 0 "OFF" ;
VAL_TABLE_ PHMOPT 2 "PREMIUM" 1 "BASIC" 0 "NONE" ;

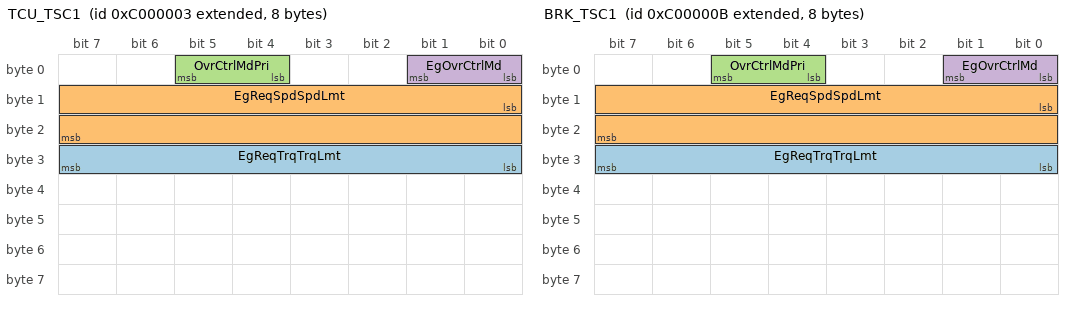
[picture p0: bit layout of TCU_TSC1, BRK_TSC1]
BO_ 2348810243 TCU_TSC1: 8 TCU
 SG_ EgReqTrqTrqLmt : 24|8@1- (1,-125) [-125|125] "percent" Vector__XXX
 SG_ EgReqSpdSpdLmt : 8|16@1+ (0.125,0) [0|8031.875] "Rpm" Vector__XXX
 SG_ OvrCtrlMdPri : 4|2@1+ (1,0) [0|3] "" Vector__XXX
 SG_ EgOvrCtrlMd : 0|2@1+ (1,0) [0|3] "" Vector__XXX

BO_ 2348810251 BRK_TSC1: 8 BRK
 SG_ EgReqTrqTrqLmt : 24|8@1- (1,-125) [-125|125] "percent" Vector__XXX
 SG_ EgReqSpdSpdLmt : 8|16@1+ (0.125,0) [0|8031.875] "Rpm" Vector__XXX
 SG_ OvrCtrlMdPri : 4|2@1+ (1,0) [0|3] "" Vector__XXX
 SG_ EgOvrCtrlMd : 0|2@1+ (1,0) [0|3] "" Vector__XXX

BO_ 2348810259 ESP_TSC1: 250 ESP
 SG_ EgReqTrqTrqLmt : 24|8@1- (1,-125) [-125|125] "percent" Vector__XXX
 SG_ EgReqSpdSpdLmt : 8|16@1+ (0.125,0) [0|8031.875] "Rpm" Vector__XXX
 SG_ OvrCtrlMdPri : 4|2@1+ (1,0) [0|3] "" Vector__XXX
 SG_ EgOvrCtrlMd : 0|2@1+ (1,0) [0|3] "" Vector__XXX

BO_ 2348810273 MCU_TSC1: 250 MCU
 SG_ EgReqTrqTrqLmt : 24|8@1- (1,-125) [-125|125] "percent" Vector__XXX
 SG_ EgReqSpdSpdLmt : 8|16@1+ (0.125,0) [0|8031.875] "Rpm" Vector__XXX
 SG_ OvrCtrlMdPri : 4|2@1+ (1,0) [0|3] "" Vector__XXX
 SG_ EgOvrCtrlMd : 0|2@1+ (1,0) [0|3] "" Vector__XXX

BO_ 2348814083 TCU_TSC1RDE: 250 TCU

BO_ 2348814091 BRK_TSC1RDE: 250 BRK

BO_ 2348814096 RDD_TSC1RDE: 250 RDD

BO_ 2348814099 ESP_TSC1RDE: 250 ESP

BO_ 2348814113 MCU_TSC1RDE: 250 MCU

BO_ 2350579745 MCU_HVESSC1: 8 MCU

BO_ 2351300641 MCU_MG1IC: 8 MCU

BO_ 2564816912 RDD_CM1: 8 RDD
 SG_ AtRgnFrcSw : 42|2@1+ (1,0) [0|3] "" Vector__XXX
 SG_ AtRgnInhbSw : 40|2@1+ (1,0) [0|3] "" Vector__XXX

BO_ 2564816929 MCU_CM1: 250 MCU
 SG_ AtRgnFrcSw : 42|2@1+ (1,0) [0|3] "" Vector__XXX
 SG_ AtRgnInhbSw : 40|2@1+ (1,0) [0|3] "" Vector__XXX

BO_ 2565800744 GP_GPSMTCU: 8 GP

BO_ 2364478241 MCU_MMIPR: 8 MCU

BO_ 2565805864 GP_GPSMCLT: 8 GP

BO_ 2565808424 GP_GPSMVCU: 1785 GP

BO_ 2565808458 TMS_REQMCU: 1785 TMS

BO_ 2565810241 GW_REQGP: 9 GW

BO_ 2565810250 TMS_REQGP: 1785 TMS

BO_ 2565810256 KPD1_REQGP: 1785 KPD1

BO_ 2565816616 GP_GPSMGW: 1785 GP

BO_ 2565818920 GP_GPSMTMS: 1785 GP

BO_ 2565820456 GP_GPSMKPD: 1785 GP

BO_ 2565821480 GP_GPSMAVM: 1785 GP

BO_ 2565821505 GW_REQEXMON: 10 GW

BO_ 2364496417 MCU_MMISC: 8 MCU

BO_ 2565865487 RDE_ERC1: 8 RDE

BO_ 2565865488 RDD_ERC1: 8 RDD

BO_ 2565865733 FNR_EBC1: 8 FNR
 SG_ EgAuxShdnSw : 28|2@1+ (1,0) [0|3] "" Vector__XXX

BO_ 2565865739 BRK_EBC1: 250 BRK
 SG_ EgAuxShdnSw : 28|2@1+ (1,0) [0|3] "" Vector__XXX

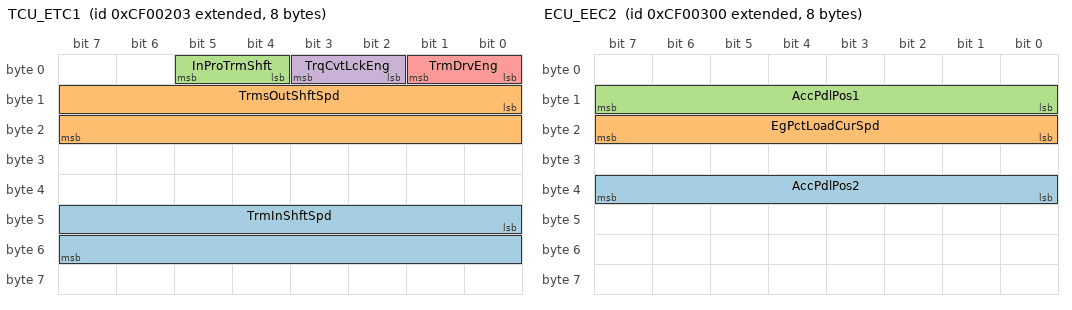
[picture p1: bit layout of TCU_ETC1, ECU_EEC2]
BO_ 2364539395 TCU_ETC1: 8 TCU
 SG_ TrmInShftSpd : 40|16@1+ (0.125,0) [0|8031.875] "Rpm" Vector__XXX
 SG_ TrmsOutShftSpd : 8|16@1+ (0.125,0) [0|8031.875] "Rpm" Vector__XXX
 SG_ InProTrmShft : 4|2@1+ (1,0) [0|3] "" Vector__XXX
 SG_ TrqCvtLckEng : 2|2@1+ (1,0) [0|3] "" Vector__XXX
 SG_ TrmDrvEng : 0|2@1+ (1,0) [0|3] "" Vector__XXX

BO_ 2364539648 ECU_EEC2: 8 ECU
 SG_ AccPdlPos2 : 32|8@1+ (0.4,0) [0|100] "percent" Vector__XXX
 SG_ EgPctLoadCurSpd : 16|8@1+ (1,0) [0|250] "percent" Vector__XXX
 SG_ AccPdlPos1 : 8|8@1+ (0.4,0) [0|100] "percent" Vector__XXX

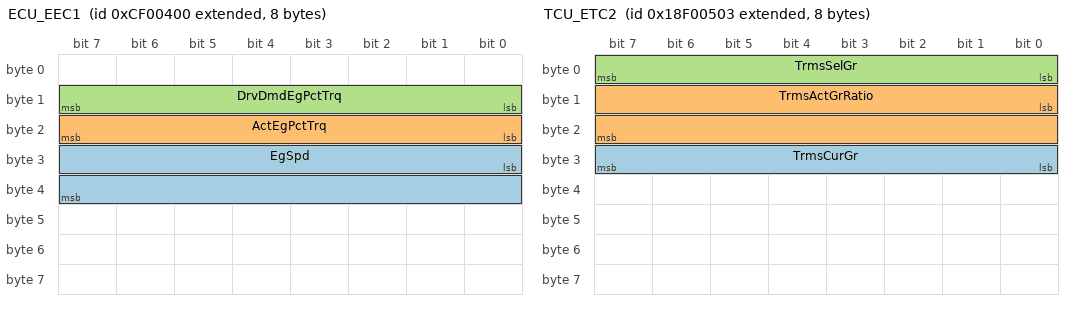
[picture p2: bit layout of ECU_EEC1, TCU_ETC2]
BO_ 2364539904 ECU_EEC1: 8 ECU
 SG_ EgSpd : 24|16@1+ (0.125,0) [0|8031.875] "Rpm" Vector__XXX
 SG_ ActEgPctTrq : 16|8@1- (1,-125) [-125|125] "percent" Vector__XXX
 SG_ DrvDmdEgPctTrq : 8|8@1- (1,-125) [-125|125] "percent" Vector__XXX

BO_ 2565866755 TCU_ETC2: 8 TCU
 SG_ TrmsCurGr : 24|8@1- (1,-125) [-125|125] "" Vector__XXX
 SG_ TrmsActGrRatio : 8|16@1+ (0.001,0) [0|64.255] "" Vector__XXX
 SG_ TrmsSelGr : 0|8@1- (1,-125) [-125|125] "" Vector__XXX

BO_ 2565867011 TCU_EAC1: 8 TCU
 SG_ DifLckStCtrEng : 16|2@1+ (1,0) [0|3] "" Vector__XXX

BO_ 2364542241 MCU_LOI: 250 MCU
 SG_ BladeAutoMdCmd : 8|4@1+ (1,0) [0|15] "" Vector__XXX
 SG_ DsrGrdOfsSw : 4|4@1+ (1,0) [0|15] "" Vector__XXX
 SG_ BladeCtrlMdSw : 0|4@1+ (1,0) [0|15] "" Vector__XXX

BO_ 2565869137 KPD2_AT1IG1: 250 KPD2
 SG_ AtIntGasSsHtCtrl : 45|2@1+ (1,0) [0|3] "states" Vector__XXX
 SG_ InRngAtIntGasSsTmp : 34|2@1+ (1,0) [0|3] "states" Vector__XXX

BO_ 2565869394 ATSGO_AT1OG1: 250 ATSGO
 SG_ AtOutGasSsHtCtrl : 45|2@1+ (1,0) [0|3] "states" Vector__XXX
 SG_ InRngAtOutGasSsTmp : 34|2@1+ (1,0) [0|3] "states" Vector__XXX

BO_ 2565875998 ACU_SSI2: 8 ACU

BO_ 2565876161 IMU1_SSI2: 8 IMU1

BO_ 2565876162 IMU2_SSI2: 8 IMU2

BO_ 2565876163 IMU3_SSI2: 8 IMU3

BO_ 2565876164 IMU4_SSI2: 8 IMU4

BO_ 2565876165 IMU5_SSI2: 8 IMU5

BO_ 2364575987 AGW_HVESSD1: 8 AGW

BO_ 2364576243 AGW_HVESSD2: 8 AGW

BO_ 2364576755 AGW_HVESSD4: 8 AGW

BO_ 2364577011 AGW_HVESSD5: 8 AGW

BO_ 2364577267 AGW_HVESSD6: 8 AGW

BO_ 2364637584 PMI_MG1IMF1: 8 PMI

BO_ 2364641057 MCU_IPGA: 250 MCU
 SG_ TmSinceLastIpsPgDtt : 48|8@1+ (1,0) [0|250] "" Vector__XXX
 SG_ IpsPgn : 24|24@1+ (1,0) [0|16777215] "" Vector__XXX
 SG_ IpsPgDA : 16|8@1+ (1,0) [0|255] "" Vector__XXX
 SG_ IpsPgSA : 8|8@1+ (1,0) [0|255] "" Vector__XXX
 SG_ IpsPgEventDttCounter : 0|8@1+ (1,0) [0|250] "" Vector__XXX

BO_ 2364641267 AGW_IPGA: 250 AGW
 SG_ TmSinceLastIpsPgDtt : 48|8@1+ (1,0) [0|250] "" Vector__XXX
 SG_ IpsPgn : 24|24@1+ (1,0) [0|16777215] "" Vector__XXX
 SG_ IpsPgDA : 16|8@1+ (1,0) [0|255] "" Vector__XXX
 SG_ IpsPgSA : 8|8@1+ (1,0) [0|255] "" Vector__XXX
 SG_ IpsPgEventDttCounter : 0|8@1+ (1,0) [0|250] "" Vector__XXX

BO_ 2365288848 PMI_MG1IMT: 8 PMI

BO_ 2365289104 PMI_MG1IT: 8 PMI

BO_ 2365289360 PMI_MG1IR2: 8 PMI

BO_ 2365289616 PMI_MG1IS1: 8 PMI

BO_ 2566675955 AGW_HVESSCFG: 8 AGW

BO_ 2633785075 AGW_HVESSHIST: 8 AGW

BO_ 2566709248 ECU_DPFC2: 8 ECU

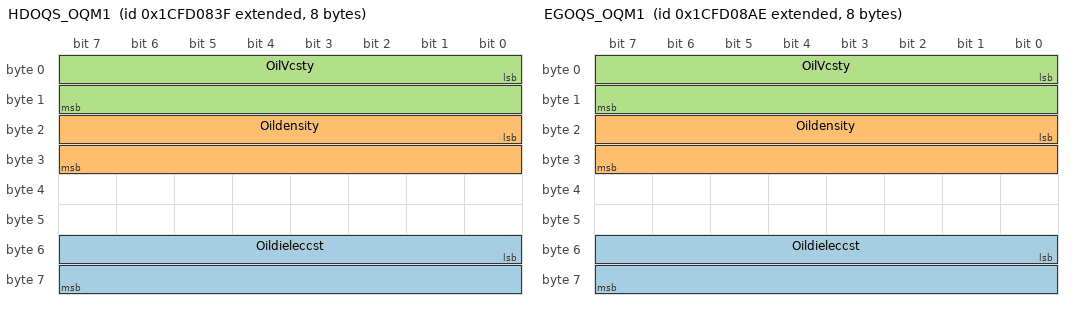
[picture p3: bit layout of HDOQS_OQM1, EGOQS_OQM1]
BO_ 2633828415 HDOQS_OQM1: 8 HDOQS
 SG_ Oildieleccst : 48|16@1+ (0.00012207,0) [0|7.84360785] "" Vector__XXX
 SG_ Oildensity : 16|16@1+ (3.052E-05,0) [0|1.9610626] "gpcm3" Vector__XXX
 SG_ OilVcsty : 0|16@1+ (0.015625,0) [0|1003.984375] "cP" Vector__XXX

BO_ 2633828526 EGOQS_OQM1: 8 EGOQS
 SG_ Oildieleccst : 48|16@1+ (0.00012207,0) [0|7.84360785] "" Vector__XXX
 SG_ Oildensity : 16|16@1+ (3.052E-05,0) [0|1.9610626] "gpcm3" Vector__XXX
 SG_ OilVcsty : 0|16@1+ (0.015625,0) [0|1003.984375] "cP" Vector__XXX

BO_ 2566719744 ECU_HRLFC: 8 ECU

BO_ 2365394514 ATSGO_AT1OGC2: 250 ATSGO

BO_ 2365394770 ATSGO_AT1OGC1: 250 ATSGO

BO_ 2365395025 KPD2_AT1IGC2: 250 KPD2

BO_ 2365395281 KPD2_AT1IGC1: 250 KPD2

BO_ 2566722989 OBC_BCH1: 8 OBC

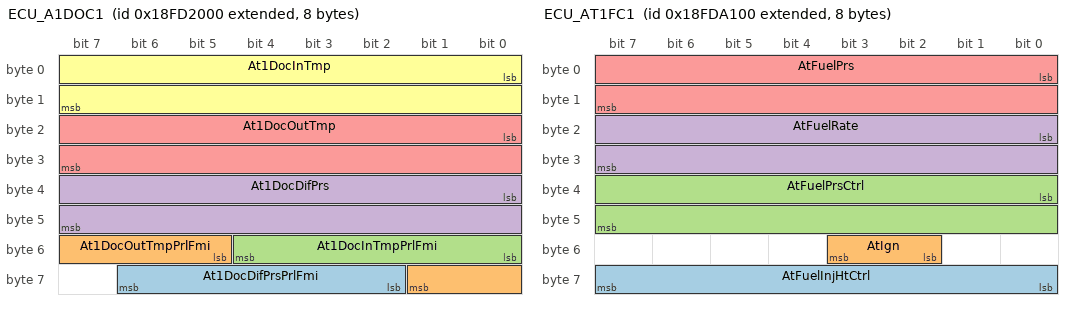
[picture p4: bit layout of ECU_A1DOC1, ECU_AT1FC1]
BO_ 2566725632 ECU_A1DOC1: 8 ECU
 SG_ At1DocDifPrsPrlFmi : 58|5@1+ (1,0) [0|31] "" Vector__XXX
 SG_ At1DocOutTmpPrlFmi : 53|5@1+ (1,0) [0|31] "" Vector__XXX
 SG_ At1DocInTmpPrlFmi : 48|5@1+ (1,0) [0|31] "" Vector__XXX
 SG_ At1DocDifPrs : 32|16@1+ (0.1,0) [0|6425.5] "kPa" Vector__XXX
 SG_ At1DocOutTmp : 16|16@1+ (0.03125,-273) [-273|1734.96875] "celsius" Vector__XXX
 SG_ At1DocInTmp : 0|16@1+ (0.03125,-273) [-273|1734.96875] "celsius" Vector__XXX

BO_ 2566748928 ECU_AT1S: 8 ECU
 SG_ DpfSootLoadPct : 0|8@1+ (1,0) [0|250] "percent" Vector__XXX

BO_ 2566749184 ECU_DPFC1: 8 ECU
 SG_ At1DpfCondNotMetforActvRgn : 60|2@1+ (1,0) [0|3] "" Vector__XXX
 SG_ DpfActvRgnIhbDuetoLowExhPrs : 58|2@1+ (1,0) [0|3] "" Vector__XXX
 SG_ HydrocarbonDoserPurgingEnb : 56|2@1+ (1,0) [0|3] "" Vector__XXX
 SG_ DpfActvRgnForcedSt : 53|3@1+ (1,0) [0|7] "" Vector__XXX
 SG_ ExhSysHhTmpLmpCmd : 50|3@1+ (1,0) [0|7] "" Vector__XXX
 SG_ DpfAutoActvRgnInitiationConfig : 48|2@1+ (1,0) [0|3] "" Vector__XXX
 SG_ DpfActvRgnIhbVhcSpdBelowAllowedS : 46|2@1+ (1,0) [0|3] "" Vector__XXX
 SG_ DpfActvRgnIhbEgNotWarmedUp : 44|2@1+ (1,0) [0|3] "" Vector__XXX
 SG_ DpfActvRgnIhbPmnSysLockout : 42|2@1+ (1,0) [0|3] "" Vector__XXX
 SG_ DpfActvRgnIhbTprSysLockout : 40|2@1+ (1,0) [0|3] "" Vector__XXX
 SG_ DpfActvRgnIhbSysTmout : 38|2@1+ (1,0) [0|3] "" Vector__XXX
 SG_ DpfActvRgnIhbSysFaultActv : 36|2@1+ (1,0) [0|3] "" Vector__XXX
 SG_ DpfActvRgnIhbLowExhTmp : 34|2@1+ (1,0) [0|3] "" Vector__XXX
 SG_ DpfActvRgnIhbPrkBrkNotSet : 32|2@1+ (1,0) [0|3] "" Vector__XXX
 SG_ DpfActvRgnIhbVhcSpdAboveAllowedS : 30|2@1+ (1,0) [0|3] "" Vector__XXX
 SG_ DpfActvRgnIhbOutofNtrl : 28|2@1+ (1,0) [0|3] "" Vector__XXX
 SG_ DpfActvRgnIhbAccPdlOffIdle : 26|2@1+ (1,0) [0|3] "" Vector__XXX
 SG_ DpfActvRgnIhbPtoActv : 24|2@1+ (1,0) [0|3] "" Vector__XXX
 SG_ DpfActvRgnIhbServiceBrkActv : 22|2@1+ (1,0) [0|3] "" Vector__XXX
 SG_ DpfActvRgnIhbClutchDisengaged : 20|2@1+ (1,0) [0|3] "" Vector__XXX
 SG_ DpfActvRgnIhbInhibitSwitch : 18|2@1+ (1,0) [0|3] "" Vector__XXX
 SG_ DpfActvRgnIhbSt : 16|2@1+ (1,0) [0|3] "" Vector__XXX
 SG_ AtDpfSt : 12|3@1+ (1,0) [0|7] "" Vector__XXX
 SG_ AtDpfActvRgnSt : 10|2@1+ (1,0) [0|3] "" Vector__XXX
 SG_ AtDpfPassiveRgnSt : 8|2@1+ (1,0) [0|3] "" Vector__XXX
 SG_ DpfActvRgnAvailabilitySt : 3|2@1+ (1,0) [0|3] "" Vector__XXX
 SG_ DpfLampCmd : 0|3@1+ (1,0) [0|7] "" Vector__XXX

BO_ 2566755587 TCU_TRF2: 8 TCU
 SG_ TrqCvtOilOutTmp : 8|16@1- (0.03125,-273) [-273|1735] "deg" Vector__XXX
 SG_ TrmOilFiltRstrSw : 0|2@1+ (1,0) [0|3] "" Vector__XXX

BO_ 2566757120 ECU_A1DEFI1: 8 ECU
 SG_ AtDefPpt : 40|4@1+ (1,0) [0|15] "states" Vector__XXX
 SG_ AtDefCct : 8|8@1+ (0.25,0) [0|62.5] "percent" Vector__XXX

BO_ 2566758656 ECU_AT1FC1: 8 ECU
 SG_ AtFuelInjHtCtrl : 56|8@1+ (0.4,0) [0|100] "percent" Vector__XXX
 SG_ AtIgn : 50|2@1+ (1,0) [0|3] "states" Vector__XXX
 SG_ AtFuelPrsCtrl : 32|16@1+ (0.0025,0) [0|160.6375] "percent" Vector__XXX
 SG_ AtFuelRate : 16|16@1+ (0.05,0) [0|3212.75] "Lph" Vector__XXX
 SG_ AtFuelPrs : 0|16@1+ (0.1,0) [0|6425.5] "kPa" Vector__XXX

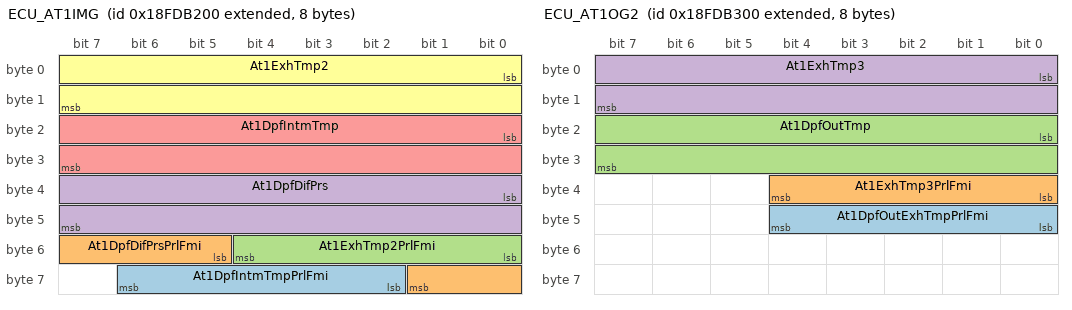
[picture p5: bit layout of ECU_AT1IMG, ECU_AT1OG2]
BO_ 2566763008 ECU_AT1IMG: 8 ECU
 SG_ At1DpfIntmTmpPrlFmi : 58|5@1+ (1,0) [0|31] "" Vector__XXX
 SG_ At1DpfDifPrsPrlFmi : 53|5@1+ (1,0) [0|31] "" Vector__XXX
 SG_ At1ExhTmp2PrlFmi : 48|5@1+ (1,0) [0|31] "" Vector__XXX
 SG_ At1DpfDifPrs : 32|16@1+ (0.1,0) [0|6425.5] "kPa" Vector__XXX
 SG_ At1DpfIntmTmp : 16|16@1+ (0.03125,-273) [-273|1734.96875] "celsius" Vector__XXX
 SG_ At1ExhTmp2 : 0|16@1+ (0.03125,-273) [-273|1734.96875] "celsius" Vector__XXX

BO_ 2566763264 ECU_AT1OG2: 8 ECU
 SG_ At1DpfOutExhTmpPrlFmi : 40|5@1+ (1,0) [0|31] "" Vector__XXX
 SG_ At1ExhTmp3PrlFmi : 32|5@1+ (1,0) [0|31] "" Vector__XXX
 SG_ At1DpfOutTmp : 16|16@1+ (0.03125,-273) [-273|1734.96875] "celsius" Vector__XXX
 SG_ At1ExhTmp3 : 0|16@1+ (0.03125,-273) [-273|1734.96875] "celsius" Vector__XXX

BO_ 2566763325 EEC_AT1OG2: 250 EEC
 SG_ At1DpfOutExhTmpPrlFmi : 40|5@1+ (1,0) [0|31] "" Vector__XXX
 SG_ At1ExhTmp3PrlFmi : 32|5@1+ (1,0) [0|31] "" Vector__XXX
 SG_ At1DpfOutTmp : 16|16@1+ (0.03125,-273) [-273|1734.96875] "celsius" Vector__XXX
 SG_ At1ExhTmp3 : 0|16@1+ (0.03125,-273) [-273|1734.96875] "celsius" Vector__XXX

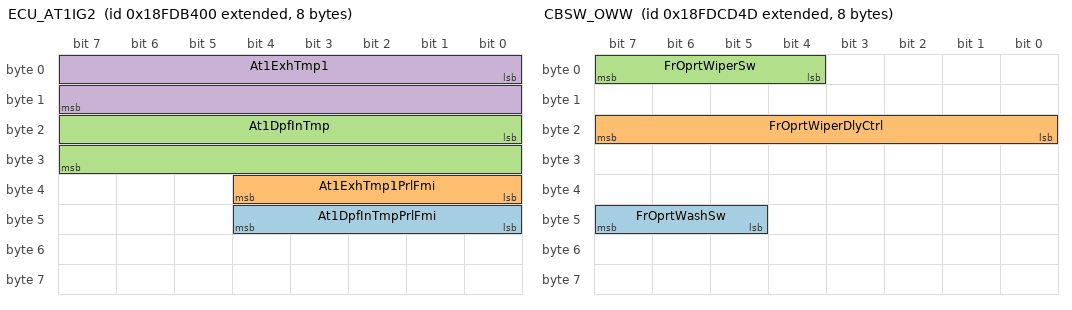
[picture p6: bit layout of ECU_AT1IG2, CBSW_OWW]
BO_ 2566763520 ECU_AT1IG2: 8 ECU
 SG_ At1DpfInTmpPrlFmi : 40|5@1+ (1,0) [0|31] "" Vector__XXX
 SG_ At1ExhTmp1PrlFmi : 32|5@1+ (1,0) [0|31] "" Vector__XXX
 SG_ At1DpfInTmp : 16|16@1+ (0.03125,-273) [-273|1734.96875] "celsius" Vector__XXX
 SG_ At1ExhTmp1 : 0|16@1+ (0.03125,-273) [-273|1734.96875] "celsius" Vector__XXX

BO_ 2566763581 EEC_AT1IG2: 250 EEC
 SG_ At1DpfInTmpPrlFmi : 40|5@1+ (1,0) [0|31] "" Vector__XXX
 SG_ At1ExhTmp1PrlFmi : 32|5@1+ (1,0) [0|31] "" Vector__XXX
 SG_ At1DpfInTmp : 16|16@1+ (0.03125,-273) [-273|1734.96875] "celsius" Vector__XXX
 SG_ At1ExhTmp1 : 0|16@1+ (0.03125,-273) [-273|1734.96875] "celsius" Vector__XXX

BO_ 2365441523 AGW_ECUID: 250 AGW

BO_ 2566769997 CBSW_OWW: 8 CBSW
 SG_ FrOprtWashSw : 45|3@1+ (1,0) [0|7] "" Vector__XXX
 SG_ FrOprtWiperDlyCtrl : 16|8@1+ (0.4,0) [0|100] "" Vector__XXX
 SG_ FrOprtWiperSw : 4|4@1+ (1,0) [0|15] "" Vector__XXX

BO_ 2566771968 ECU_EEC5: 8 ECU
 SG_ EgEgrVvCtrl : 32|16@1+ (0.0025,0) [0|160.6375] "percent" Vector__XXX

BO_ 2365445841 EJRH_BJM1: 8 EJRH

BO_ 2365446097 EJRH_EJM1: 8 EJRH

BO_ 2365446352 EJLH_BJM2: 8 EJLH

BO_ 2365446608 EJLH_EJM2: 8 EJLH

BO_ 2365446893 EPDLT_BJM3: 8 EPDLT

BO_ 2365446894 EPDL2_BJM3: 8 EPDL2

BO_ 2365446895 EPDLR_BJM3: 8 EPDLR

BO_ 2365446896 EPDLA_BJM3: 8 EPDLA

BO_ 2365468962 TRBDZ_AV01C: 250 TRBDZ
 SG_ PortFlowHighResolution : 24|16@1+ (0.0015625,0) [0|100.3984375] "" Vector__XXX
 SG_ FailSafeMd : 22|2@1+ (1,0) [0|3] "" Vector__XXX
 SG_ VvSt : 16|4@1+ (1,0) [0|15] "" Vector__XXX
 SG_ ResolutionMd : 8|2@1+ (1,0) [0|3] "" Vector__XXX
 SG_ AuxVv1PortFlowCmd : 0|8@1+ (0.4,0) [0|100] "" Vector__XXX

BO_ 2365469218 TRBDZ_AV02C: 250 TRBDZ
 SG_ PortFlowHighResolution : 24|16@1+ (0.0015625,0) [0|100.3984375] "" Vector__XXX
 SG_ FailSafeMd : 22|2@1+ (1,0) [0|3] "" Vector__XXX
 SG_ VvSt : 16|4@1+ (1,0) [0|15] "" Vector__XXX
 SG_ ResolutionMd : 8|2@1+ (1,0) [0|3] "" Vector__XXX
 SG_ AuxVv1PortFlowCmd : 0|8@1+ (0.4,0) [0|100] "" Vector__XXX

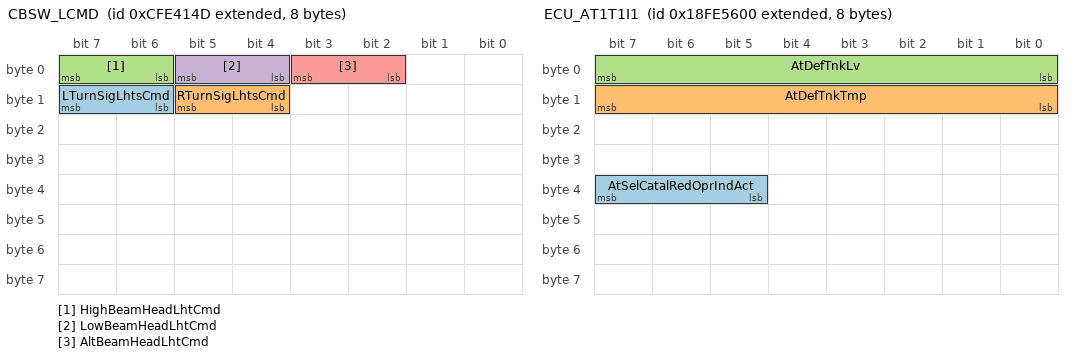
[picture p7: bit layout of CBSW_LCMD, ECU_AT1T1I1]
BO_ 2365473101 CBSW_LCMD: 8 CBSW
 SG_ LTurnSigLhtsCmd : 14|2@1+ (1,0) [0|3] "" Vector__XXX
 SG_ RTurnSigLhtsCmd : 12|2@1+ (1,0) [0|3] "" Vector__XXX
 SG_ HighBeamHeadLhtCmd : 6|2@1+ (1,0) [0|3] "" Vector__XXX
 SG_ LowBeamHeadLhtCmd : 4|2@1+ (1,0) [0|3] "" Vector__XXX
 SG_ AltBeamHeadLhtCmd : 2|2@1+ (1,0) [0|3] "" Vector__XXX

BO_ 2566801441 MCU_WBSD: 250 MCU

BO_ 2566801923 TCU_ETC7: 8 TCU

BO_ 2566802176 ECU_TCFG2: 8 ECU
 SG_ EgThrtActCtrlCmd : 0|16@1+ (0.0025,0) [0|160.6375] "percent" Vector__XXX

BO_ 2566803211 BRK_VDC1: 250 BRK

BO_ 2566804992 ECU_AT1T1I1: 8 ECU
 SG_ AtSelCatalRedOprIndAct : 37|3@1+ (1,0) [0|7] "states" Vector__XXX
 SG_ AtDefTnkTmp : 8|8@1- (1,-40) [-40|210] "celsius" Vector__XXX
 SG_ AtDefTnkLv : 0|8@1+ (0.4,0) [0|100] "percent" Vector__XXX

BO_ 2566804993 ECU1_AT1T1I1: 250 ECU1
 SG_ AtSelCatalRedOprIndAct : 37|3@1+ (1,0) [0|7] "states" Vector__XXX
 SG_ AtDefTnkTmp : 8|8@1- (1,-40) [-40|210] "celsius" Vector__XXX
 SG_ AtDefTnkLv : 0|8@1+ (0.4,0) [0|100] "percent" Vector__XXX

BO_ 2365484270 EPDL2_TCO1: 250 EPDL2

BO_ 2566811147 BRK_HRWS: 250 BRK

BO_ 2633927682 ECU_AAI2EDC: 250 ECU

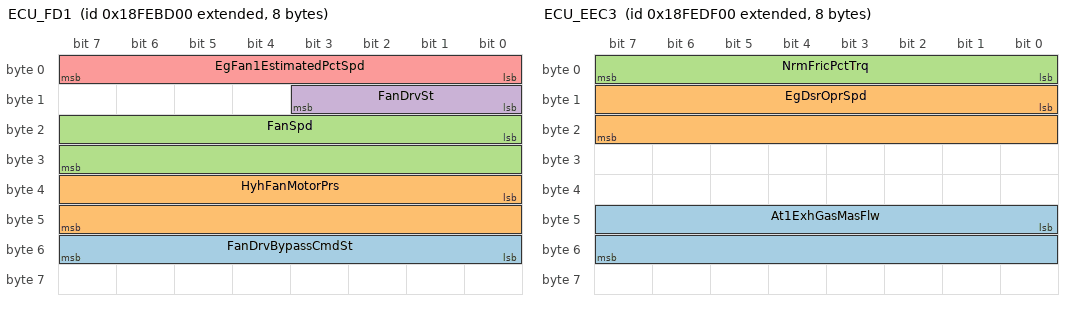
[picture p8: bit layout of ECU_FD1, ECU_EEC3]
BO_ 2566831360 ECU_FD1: 8 ECU
 SG_ FanDrvBypassCmdSt : 48|8@1+ (0.4,0) [0|100] "percent" Vector__XXX
 SG_ HyhFanMotorPrs : 32|16@1+ (0.5,0) [0|32127.5] "kPa" Vector__XXX
 SG_ FanSpd : 16|16@1+ (0.125,0) [0|8031.875] "rpm" Vector__XXX
 SG_ FanDrvSt : 8|4@1+ (1,0) [0|15] "" Vector__XXX
 SG_ EgFan1EstimatedPctSpd : 0|8@1+ (0.4,0) [0|100] "percent" Vector__XXX

BO_ 2566831616 ECU_EEC4: 8 ECU

BO_ 2566831883 BRK_EBC2: 250 BRK

BO_ 2566832622 EPDL2_VDHR: 250 EPDL2

BO_ 2566834688 ECU_DM1: 1785 ECU

BO_ 2566834749 EEC_DM1: 250 EEC

BO_ 2566834944 ECU_DM2: 1785 ECU

BO_ 2566835456 ECU_DM4: 1785 ECU

BO_ 2566835712 ECU_DM5: 1785 ECU

BO_ 2566835968 ECU_DM6: 1785 ECU

BO_ 2566838528 ECU_AUXIO1: 8 ECU

BO_ 2566839296 ECU_IDLOP: 8 ECU

BO_ 2566840064 ECU_EEC3: 8 ECU
 SG_ At1ExhGasMasFlw : 40|16@1+ (0.2,0) [0|12851] "kgph" Vector__XXX
 SG_ EgDsrOprSpd : 8|16@1+ (0.125,0) [0|8031.875] "Rpm" Vector__XXX
 SG_ NrmFricPctTrq : 0|8@1- (1,-125) [-125|125] "percent" Vector__XXX

BO_ 2566841344 ECU_SHUTDWN: 8 ECU

BO_ 2566841600 ECU_HOURS: 8 ECU
 SG_ EgTotRev : 32|32@1+ (1000,0) [0|4211081215000] "rev" Vector__XXX
 SG_ EgTotHrOpr : 0|32@1+ (0.05,0) [0|210554060.75] "hours" Vector__XXX

BO_ 2566841879 CLST_TD: 8 CLST

BO_ 2566842094 EPDL2_TD: 250 EPDL2

BO_ 2566842112 ECU_VH: 8 ECU

BO_ 2566842624 ECU_LFC1: 8 ECU
 SG_ EgTotFuelUsed : 32|32@1+ (0.5,0) [0|2105540607.5] "liters" Vector__XXX
 SG_ EgTripFuel : 0|32@1+ (0.5,0) [0|2105540607.5] "liters" Vector__XXX

BO_ 2566843136 ECU_CI: 8 ECU

BO_ 2566843392 ECU_VI: 8 ECU

BO_ 2566843648 ECU_CCSS: 8 ECU

BO_ 2566843651 TCU_CCSS: 8 TCU

BO_ 2566843653 FNR_CCSS: 8 FNR

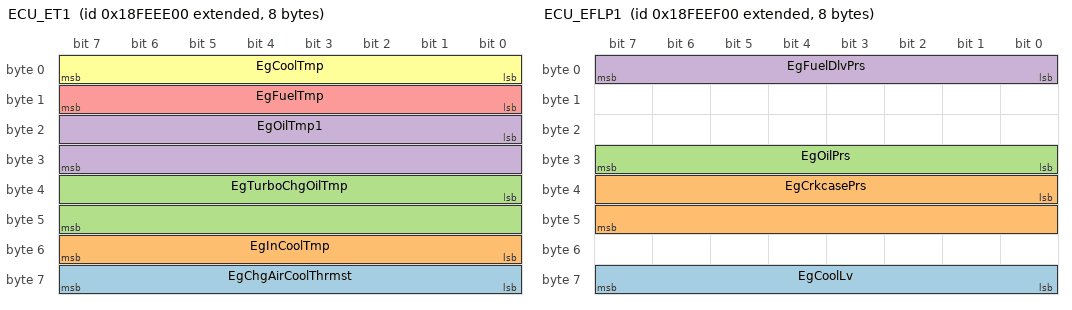
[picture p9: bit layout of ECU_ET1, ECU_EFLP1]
BO_ 2566843904 ECU_ET1: 8 ECU
 SG_ EgChgAirCoolThrmst : 56|8@1+ (0.4,0) [0|100] "percent" Vector__XXX
 SG_ EgInCoolTmp : 48|8@1+ (1,-40) [-40|210] "celsius" Vector__XXX
 SG_ EgTurboChgOilTmp : 32|16@1+ (0.03125,-273) [-273|1734.96875] "celsius" Vector__XXX
 SG_ EgOilTmp1 : 16|16@1+ (0.03125,-273) [-273|1734.96875] "celsius" Vector__XXX
 SG_ EgFuelTmp : 8|8@1- (1,-40) [-40|210] "celsius" Vector__XXX
 SG_ EgCoolTmp : 0|8@1- (1,-40) [-40|210] "celsius" Vector__XXX

BO_ 2566843967 HDOQS_OT: 8 HDOQS
 SG_ OilAvrgTmp : 16|16@1+ (0.03125,-273) [-273|1734.96875] "celsius" Vector__XXX

BO_ 2566844078 EGOQS_OT: 8 EGOQS
 SG_ OilAvrgTmp : 16|16@1+ (0.03125,-273) [-273|1734.96875] "celsius" Vector__XXX

BO_ 2566844160 ECU_EFLP1: 8 ECU
 SG_ EgCoolLv : 56|8@1+ (0.4,0) [0|100] "percent" Vector__XXX
 SG_ EgCrkcasePrs : 32|16@1- (0.0078125,-250) [-250|251.99] "kPa" Vector__XXX
 SG_ EgOilPrs : 24|8@1+ (4,0) [0|1000] "kPa" Vector__XXX
 SG_ EgFuelDlvPrs : 0|8@1+ (4,0) [0|1000] "kPa" Vector__XXX

BO_ 2566844672 ECU_CCVS: 8 ECU
 SG_ WhlVhcSpd : 8|16@1+ (0.00390625,0) [0|250.996] "kmph" Vector__XXX

BO_ 2566844675 TCU_CCVS: 8 TCU
 SG_ WhlVhcSpd : 8|16@1+ (0.00390625,0) [0|250.996] "kmph" Vector__XXX

BO_ 2566844705 MCU_CCVS: 8 MCU
 SG_ WhlVhcSpd : 8|16@1+ (0.00390625,0) [0|250.996] "kmph" Vector__XXX

BO_ 2566844928 ECU_LFE1: 8 ECU
 SG_ EgThrtVvPos : 48|8@1+ (0.4,0) [0|100] "percent" Vector__XXX
 SG_ EgFuelRate : 0|16@1+ (0.05,0) [0|3212.75] "Lph" Vector__XXX

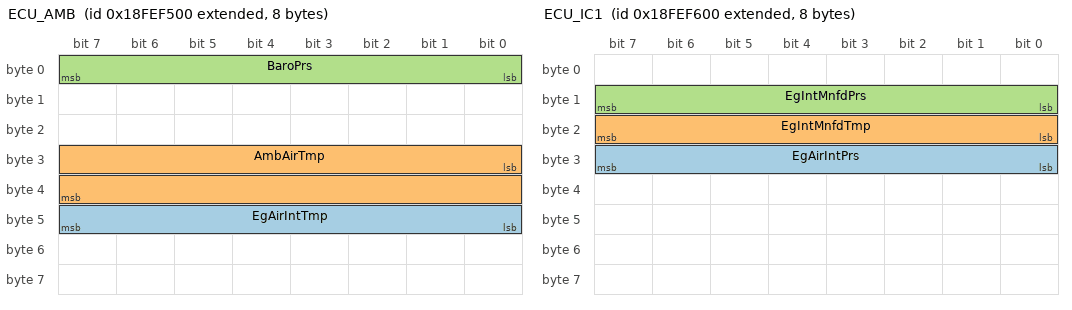
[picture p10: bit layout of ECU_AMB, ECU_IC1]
BO_ 2566845696 ECU_AMB: 8 ECU
 SG_ EgAirIntTmp : 40|8@1- (1,-40) [-40|210] "celsius" Vector__XXX
 SG_ AmbAirTmp : 24|16@1- (0.03125,-273) [-273|1734.96875] "celsius" Vector__XXX
 SG_ BaroPrs : 0|8@1+ (0.5,0) [0|125] "kPa" Vector__XXX

BO_ 2566845952 ECU_IC1: 8 ECU
 SG_ EgAirIntPrs : 24|8@1+ (2,0) [0|500] "kPa" Vector__XXX
 SG_ EgIntMnfdTmp : 16|8@1- (1,-40) [-40|210] "celsius" Vector__XXX
 SG_ EgIntMnfdPrs : 8|8@1+ (2,0) [0|500] "kPa" Vector__XXX

BO_ 2566846208 ECU_VEP1: 8 ECU
 SG_ KeyswBatPtc : 48|16@1+ (0.05,0) [0|3212.75] "V" Vector__XXX
 SG_ BatPtcPowIn : 32|16@1+ (0.05,0) [0|3212.75] "V" Vector__XXX

BO_ 2566846467 TCU_TF: 8 TCU

BO_ 2566846981 FNR_B1: 8 FNR

BO_ 2566847235 TCU_RF: 8 TCU
 SG_ TrmOilFiltRstrSw : 8|8@1- (1,-40) [-40|210] "deg" Vector__XXX

BO_ 2566847511 CLST_DD1: 8 CLST

BO_ 2566847521 MCU_DD1: 8 MCU

BO_ 2566848256 ECU_WFI: 8 ECU

BO_ 2566849085 EEC_TXEGSPM: 8 EEC

BO_ 2566851074 ECU_ACTVCODERx: 8 ECU

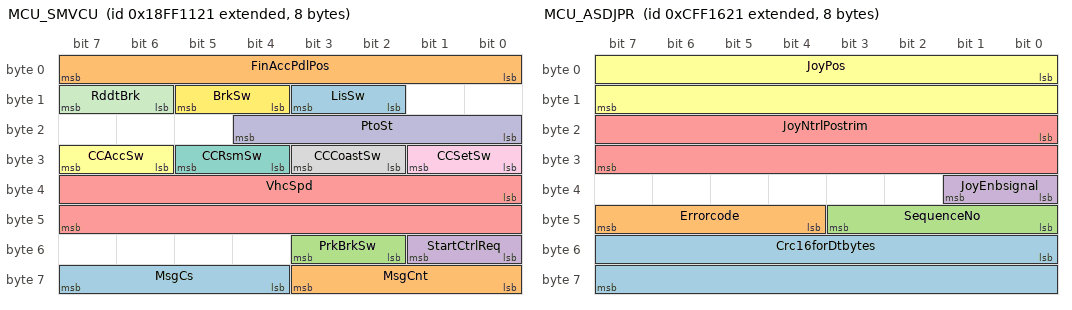
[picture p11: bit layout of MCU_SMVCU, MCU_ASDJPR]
BO_ 2566852897 MCU_SMVCU: 8 MCU
 SG_ MsgCs : 60|4@1+ (1,0) [0|15] "count" Vector__XXX
 SG_ MsgCnt : 56|4@1+ (1,0) [0|15] "count" Vector__XXX
 SG_ PrkBrkSw : 50|2@1+ (1,0) [0|3] "" Vector__XXX
 SG_ StartCtrlReq : 48|2@1+ (1,0) [0|3] "" Vector__XXX
 SG_ VhcSpd : 32|16@1+ (0.00390625,0) [0|250.996] "kmph" Vector__XXX
 SG_ CCAccSw : 30|2@1+ (1,0) [0|3] "" Vector__XXX
 SG_ CCRsmSw : 28|2@1+ (1,0) [0|3] "" Vector__XXX
 SG_ CCCoastSw : 26|2@1+ (1,0) [0|3] "" Vector__XXX
 SG_ CCSetSw : 24|2@1+ (1,0) [0|3] "" Vector__XXX
 SG_ PtoSt : 16|5@1+ (1,0) [0|31] "" Vector__XXX
 SG_ RddtBrk : 14|2@1+ (1,0) [0|3] "" Vector__XXX
 SG_ BrkSw : 12|2@1+ (1,0) [0|3] "" Vector__XXX
 SG_ LisSw : 10|2@1+ (1,0) [0|3] "" Vector__XXX
 SG_ FinAccPdlPos : 0|8@1+ (0.4,0) [0|100] "percent" Vector__XXX

BO_ 2365527585 MCU_ASDJPR: 8 MCU
 SG_ Crc16forDtbytes : 48|16@1+ (1,0) [0|65535] "" Vector__XXX
 SG_ Errorcode : 44|4@1+ (1,0) [0|15] "" Vector__XXX
 SG_ SequenceNo : 40|4@1+ (1,0) [0|15] "count" Vector__XXX
 SG_ JoyEnbsignal : 32|2@1+ (1,0) [0|3] "" Vector__XXX
 SG_ JoyNtrlPostrim : 16|16@1- (0.1,-20) [-20|20] "percent" Vector__XXX
 SG_ JoyPos : 0|16@1- (0.1,-100) [-100|100] "percent" Vector__XXX

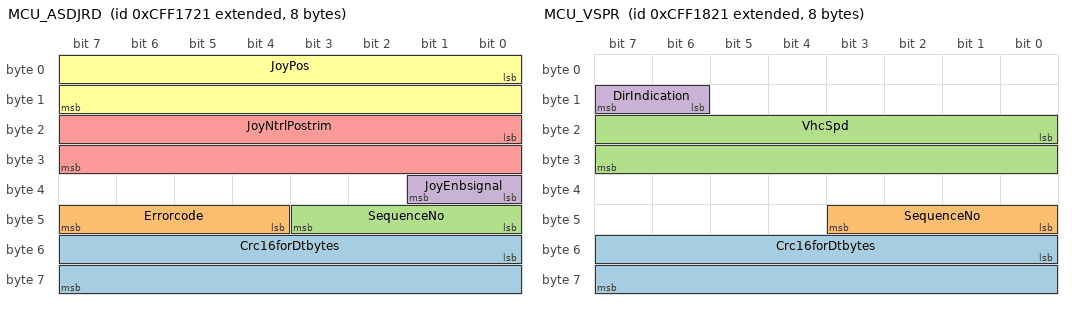
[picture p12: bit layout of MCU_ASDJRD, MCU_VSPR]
BO_ 2365527841 MCU_ASDJRD: 8 MCU
 SG_ Crc16forDtbytes : 48|16@1+ (1,0) [0|65535] "" Vector__XXX
 SG_ Errorcode : 44|4@1+ (1,0) [0|15] "" Vector__XXX
 SG_ SequenceNo : 40|4@1+ (1,0) [0|15] "count" Vector__XXX
 SG_ JoyEnbsignal : 32|2@1+ (1,0) [0|3] "" Vector__XXX
 SG_ JoyNtrlPostrim : 16|16@1- (0.1,-20) [-20|20] "percent" Vector__XXX
 SG_ JoyPos : 0|16@1- (0.1,-100) [-100|100] "percent" Vector__XXX

BO_ 2365528097 MCU_VSPR: 8 MCU
 SG_ Crc16forDtbytes : 48|16@1+ (1,0) [0|65535] "" Vector__XXX
 SG_ SequenceNo : 40|4@1+ (1,0) [0|15] "" Vector__XXX
 SG_ VhcSpd : 16|16@1+ (0.00390625,0) [0|250.996] "" Vector__XXX
 SG_ DirIndication : 14|2@1+ (1,0) [0|3] "" Vector__XXX

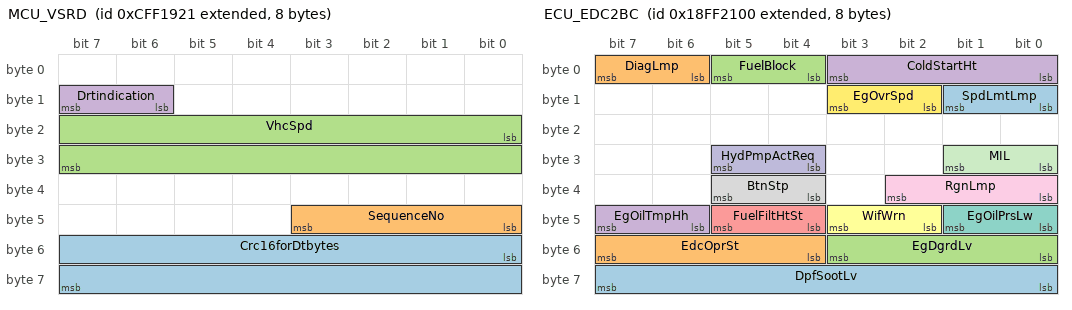
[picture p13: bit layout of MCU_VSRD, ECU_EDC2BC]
BO_ 2365528353 MCU_VSRD: 8 MCU
 SG_ Crc16forDtbytes : 48|16@1+ (1,0) [0|65535] "" Vector__XXX
 SG_ SequenceNo : 40|4@1+ (1,0) [0|15] "" Vector__XXX
 SG_ VhcSpd : 16|16@1+ (0.00390625,0) [0|250.996] "" Vector__XXX
 SG_ Drtindication : 14|2@1+ (1,0) [0|3] "" Vector__XXX

BO_ 2566856451 TCU_TCU2: 8 TCU

BO_ 2566856707 TCU_TCU3: 8 TCU

BO_ 2365530117 FNR_SLP1: 8 FNR

BO_ 2566856960 ECU_EDC2BC: 8 ECU
 SG_ DpfSootLv : 56|8@1+ (1,0) [0|255] "percent" Vector__XXX
 SG_ EdcOprSt : 52|4@1+ (1,0) [0|15] "" Vector__XXX
 SG_ EgDgrdLv : 48|4@1+ (1,0) [0|15] "" Vector__XXX
 SG_ EgOilTmpHh : 46|2@1+ (1,0) [0|3] "" Vector__XXX
 SG_ FuelFiltHtSt : 44|2@1+ (1,0) [0|3] "" Vector__XXX
 SG_ WifWrn : 42|2@1+ (1,0) [0|3] "" Vector__XXX
 SG_ EgOilPrsLw : 40|2@1+ (1,0) [0|3] "" Vector__XXX
 SG_ BtnStp : 36|2@1+ (1,0) [0|3] "" Vector__XXX
 SG_ RgnLmp : 32|3@1+ (1,0) [0|7] "" Vector__XXX
 SG_ HydPmpActReq : 28|2@1+ (1,0) [0|3] "" Vector__XXX
 SG_ MIL : 24|2@1+ (1,0) [0|3] "" Vector__XXX
 SG_ EgOvrSpd : 10|2@1+ (1,0) [0|3] "" Vector__XXX
 SG_ SpdLmtLmp : 8|2@1+ (1,0) [0|3] "" Vector__XXX
 SG_ DiagLmp : 6|2@1+ (1,0) [0|3] "" Vector__XXX
 SG_ FuelBlock : 4|2@1+ (1,0) [0|3] "" Vector__XXX
 SG_ ColdStartHt : 0|4@1+ (1,0) [0|15] "" Vector__XXX

BO_ 2365530373 FNR_SLP2: 8 FNR

BO_ 2566857219 TCU_TCU4: 8 TCU
 SG_ CnvtTurbTrq : 16|16@1- (1,-3200) [-32000|32255] "Nm" Vector__XXX
 SG_ CnvtPmpTrq : 0|16@1- (1,-3200) [-32000|32255] "Nm" Vector__XXX

BO_ 2566857731 TCU_ZFCC: 8 TCU

BO_ 2566857984 ECU_ENGCOND: 10 ECU
 SG_ PhsDifCrkCam : 32|48@1- (0.1,-720) [-720|5833.5] "degCrS" Vector__XXX
 SG_ EgOprCmd : 16|16@1+ (1,0) [0|65535] "" Vector__XXX
 SG_ AirMassPrs : 0|16@1+ (0.25,0) [0|16383.75] "kgph" Vector__XXX

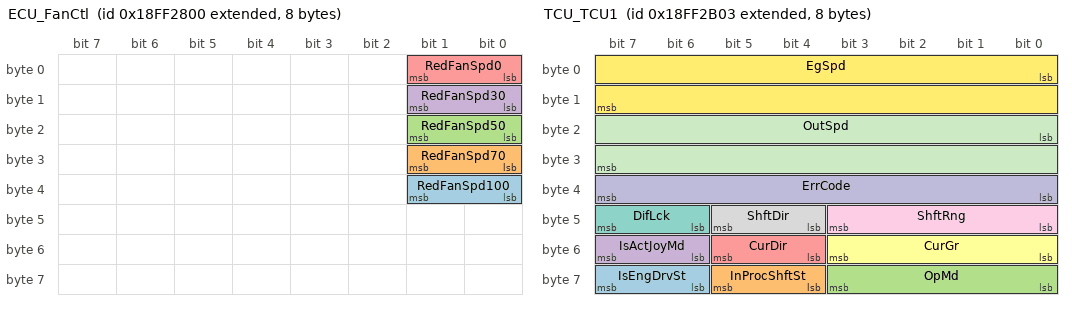
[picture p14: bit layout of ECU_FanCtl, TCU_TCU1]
BO_ 2566858752 ECU_FanCtl: 8 ECU
 SG_ RedFanSpd100 : 32|2@1+ (1,0) [0|255] "" Vector__XXX
 SG_ RedFanSpd70 : 24|2@1+ (1,0) [0|255] "" Vector__XXX
 SG_ RedFanSpd50 : 16|2@1+ (1,0) [0|255] "" Vector__XXX
 SG_ RedFanSpd30 : 8|2@1+ (1,0) [0|255] "" Vector__XXX
 SG_ RedFanSpd0 : 0|2@1+ (1,0) [0|255] "" Vector__XXX

BO_ 2566859297 MCU_VEHICLE2: 8 MCU

BO_ 2566859523 TCU_TCU1: 8 TCU
 SG_ IsEngDrvSt : 62|2@1+ (1,0) [0|3] "" Vector__XXX
 SG_ InProcShftSt : 60|2@1+ (1,0) [0|3] "" Vector__XXX
 SG_ OpMd : 56|4@1+ (1,0) [0|4] "" Vector__XXX
 SG_ IsActJoyMd : 54|2@1+ (1,0) [0|3] "" Vector__XXX
 SG_ CurDir : 52|2@1+ (1,0) [0|3] "" Vector__XXX
 SG_ CurGr : 48|4@1+ (1,0) [0|15] "" Vector__XXX
 SG_ DifLck : 46|2@1+ (1,0) [0|3] "" Vector__XXX
 SG_ ShftDir : 44|2@1+ (1,0) [0|3] "" Vector__XXX
 SG_ ShftRng : 40|4@1+ (1,0) [0|4] "" Vector__XXX
 SG_ ErrCode : 32|8@1+ (1,0) [0|255] "" Vector__XXX
 SG_ OutSpd : 16|16@1+ (1,0) [0|8031.875] "Rpm" Vector__XXX
 SG_ EgSpd : 0|16@1+ (1,0) [0|8031.875] "Rpm" Vector__XXX

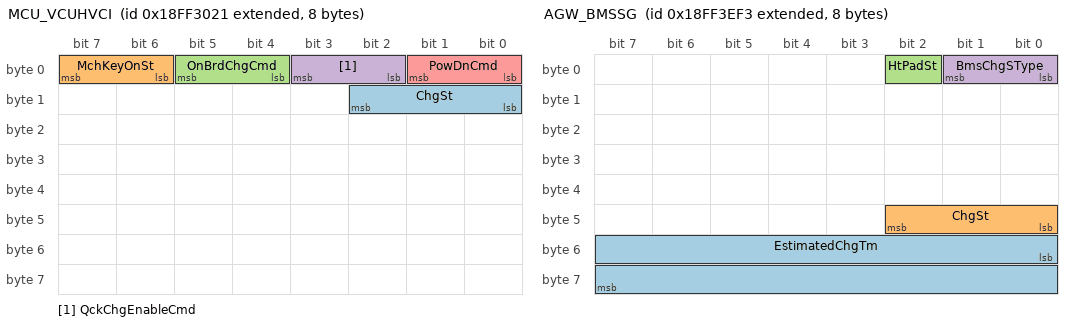
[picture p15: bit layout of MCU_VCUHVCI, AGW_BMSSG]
BO_ 2566860833 MCU_VCUHVCI: 8 MCU
 SG_ ChgSt : 8|3@1+ (1,0) [0|7] "" Vector__XXX
 SG_ MchKeyOnSt : 6|2@1+ (1,0) [0|3] "" Vector__XXX
 SG_ OnBrdChgCmd : 4|2@1+ (1,0) [0|3] "" Vector__XXX
 SG_ QckChgEnableCmd : 2|2@1+ (1,0) [0|3] "" Vector__XXX
 SG_ PowDnCmd : 0|2@1+ (1,0) [0|3] "" Vector__XXX

BO_ 2566861056 ECU_TFI4CMD: 8 ECU
 SG_ FiltTm : 8|8@1+ (1,0) [0|255] "" Vector__XXX
 SG_ Cmd : 0|8@1+ (1,0) [0|255] "" Vector__XXX

BO_ 2566861119 HDOQS_OSM: 8 HDOQS
 SG_ StMsgCode : 0|24@1+ (1,0) [0|16777215] "" Vector__XXX

BO_ 2566861230 EGOQS_OSM: 8 EGOQS
 SG_ StMsgCode : 0|24@1+ (1,0) [0|16777215] "" Vector__XXX

BO_ 2566863330 LC510_TFI4Data: 8 LC510

BO_ 2566863533 OBC_OBCMI: 14 OBC
 SG_ FanSt : 104|1@1+ (1,0) [0|1] "" Vector__XXX
 SG_ PdVlt : 96|8@1+ (0.2,0) [0|50] "" Vector__XXX
 SG_ CpVlt : 80|16@1- (0.05,-1606) [-1606|1606.75] "" Vector__XXX
 SG_ ObcAtmosphereTemp : 72|8@1- (1,-40) [-40|210] "" Vector__XXX
 SG_ ObcMaxTemp : 64|8@1- (1,-40) [-40|210] "" Vector__XXX
 SG_ PfcVlt : 48|16@1+ (1,0) [0|65535] "" Vector__XXX
 SG_ AcInCur : 40|8@1+ (0.25,0) [0|62.5] "" Vector__XXX
 SG_ AcInFrequency : 32|8@1+ (1,0) [0|250] "" Vector__XXX
 SG_ AcInVlt : 16|16@1+ (0.01,0) [0|642.55] "" Vector__XXX
 SG_ ChgElapsedTm : 0|16@1+ (1,0) [0|64255] "" Vector__XXX

BO_ 2566864354 LC510_RxTFI4OBD: 8 LC510

BO_ 2566864627 AGW_BMSSG: 8 AGW
 SG_ EstimatedChgTm : 48|16@1+ (1,0) [0|64255] "" Vector__XXX
 SG_ ChgSt : 40|3@1+ (1,0) [0|7] "" Vector__XXX
 SG_ HtPadSt : 2|1@1+ (1,0) [0|1] "" Vector__XXX
 SG_ BmsChgSType : 0|2@1+ (1,0) [0|3] "" Vector__XXX

BO_ 2566864680 GP_USUHDI: 63 GP
 SG_ FuelEfficiencybyUser : 488|16@1+ (0.05,0) [0|3212.75] "lph" Vector__XXX
 SG_ EcnMdFuelUsgbyUser : 456|32@1+ (0.5,0) [0|2105540607.5] "liters" Vector__XXX
 SG_ StdMdFuelUsgbyUser : 424|32@1+ (0.5,0) [0|2105540607.5] "liters" Vector__XXX
 SG_ PwrMdFuelUsgbyUser : 392|32@1+ (0.5,0) [0|2105540607.5] "liters" Vector__XXX
 SG_ PwrPlusMdFuelUsgbyUser : 360|32@1+ (0.5,0) [0|2105540607.5] "liters" Vector__XXX
 SG_ TotalFuelUsgbyUser : 328|32@1+ (0.5,0) [0|2105540607.5] "liters" Vector__XXX
 SG_ EcnMdOprtgHrbyUser : 296|32@1+ (1,0) [0|4211081215] "minutes" Vector__XXX
 SG_ StdMdOprtgHrbyUser : 264|32@1+ (1,0) [0|4211081215] "minutes" Vector__XXX
 SG_ PwrMdOprtgHrbyUser : 232|32@1+ (1,0) [0|4211081215] "minutes" Vector__XXX
 SG_ PwrPlusMdOprtgHrbyUser : 200|32@1+ (1,0) [0|4211081215] "minutes" Vector__XXX
 SG_ IdleOprtgHrbyUser : 168|32@1+ (1,0) [0|4211081215] "minutes" Vector__XXX
 SG_ TotalOprtgHrbyUser : 136|32@1+ (1,0) [0|4211081215] "minutes" Vector__XXX
 SG_ UserName : 8|128@1+ (1,0) [0|255] "ASCII" Vector__XXX
 SG_ UserSeparatorFlag : 3|5@1+ (1,0) [0|31] "" Vector__XXX
 SG_ UserSeparatorSlot : 0|3@1+ (1,0) [0|7] "" Vector__XXX

BO_ 2566864929 MCU_WSG1: 8 MCU
 SG_ InvOh : 62|2@1+ (1,0) [0|3] "" Vector__XXX
 SG_ MotOh : 60|2@1+ (1,0) [0|3] "" Vector__XXX
 SG_ BatOh : 58|2@1+ (1,0) [0|3] "" Vector__XXX
 SG_ Bms : 56|2@1+ (1,0) [0|3] "" Vector__XXX
 SG_ BatHt : 54|2@1+ (1,0) [0|3] "" Vector__XXX
 SG_ TrvlPdlFail : 52|2@1+ (1,0) [0|3] "" Vector__XXX
 SG_ RrWhlAlgn : 50|2@1+ (1,0) [0|3] "" Vector__XXX
 SG_ PrkBrkPrs : 48|2@1+ (1,0) [0|3] "" Vector__XXX
 SG_ TrsmOilFiltClog : 46|2@1+ (1,0) [0|3] "" Vector__XXX
 SG_ FanMotPrsLw : 44|2@1+ (1,0) [0|3] "" Vector__XXX
 SG_ OvSpd : 42|2@1+ (1,0) [0|3] "" Vector__XXX
 SG_ RBrkPdlNoCalb : 40|2@1+ (1,0) [0|3] "" Vector__XXX
 SG_ ElecStr : 38|2@1+ (1,0) [0|3] "" Vector__XXX
 SG_ EgOvr : 36|2@1+ (1,0) [0|3] "" Vector__XXX
 SG_ EmgStr : 34|2@1+ (1,0) [0|3] "" Vector__XXX
 SG_ SeatBelt : 32|2@1+ (1,0) [0|3] "" Vector__XXX
 SG_ TrsmOilOh : 30|2@1+ (1,0) [0|3] "" Vector__XXX
 SG_ Trsm : 28|2@1+ (1,0) [0|3] "" Vector__XXX
 SG_ VboEpprVvOut : 26|2@1+ (1,0) [0|3] "" Vector__XXX
 SG_ VboJoySs : 24|2@1+ (1,0) [0|3] "" Vector__XXX
 SG_ VboAngSs : 22|2@1+ (1,0) [0|3] "" Vector__XXX
 SG_ BatEq : 20|2@1+ (1,0) [0|3] "" Vector__XXX
 SG_ Uss : 18|2@1+ (1,0) [0|3] "" Vector__XXX
 SG_ IceptSs : 16|2@1+ (1,0) [0|3] "" Vector__XXX
 SG_ Str : 14|2@1+ (1,0) [0|3] "" Vector__XXX
 SG_ BrkOilPrsLw : 12|2@1+ (1,0) [0|3] "" Vector__XXX
 SG_ Ags : 10|2@1+ (1,0) [0|3] "" Vector__XXX
 SG_ Owd : 8|2@1+ (1,0) [0|3] "" Vector__XXX
 SG_ PilotFilt : 6|2@1+ (1,0) [0|3] "" Vector__XXX
 SG_ RetFilt : 4|2@1+ (1,0) [0|3] "" Vector__XXX
 SG_ HydOilOh : 2|2@1+ (1,0) [0|3] "" Vector__XXX
 SG_ BatChg : 0|2@1+ (1,0) [0|3] "" Vector__XXX

BO_ 2566865185 MCU_WSG2: 8 MCU
 SG_ AcleOilOh : 62|2@1+ (1,0) [0|3] "" Vector__XXX
 SG_ AxleOilOvrHtFr : 60|2@1+ (1,0) [0|3] "" Vector__XXX
 SG_ AxleOilOvrHtRr : 58|2@1+ (1,0) [0|3] "" Vector__XXX
 SG_ EgOilLv : 56|2@1+ (1,0) [0|3] "" Vector__XXX
 SG_ ShtShftShutDown : 54|2@1+ (1,0) [0|3] "" Vector__XXX
 SG_ Acmt : 52|2@1+ (1,0) [0|3] "" Vector__XXX
 SG_ TireTemp : 50|2@1+ (1,0) [0|3] "" Vector__XXX
 SG_ FuelEmptyAddFuelTnk : 48|2@1+ (1,0) [0|3] "" Vector__XXX
 SG_ ePowStp : 46|2@1+ (1,0) [0|3] "" Vector__XXX
 SG_ ePowChk : 44|2@1+ (1,0) [0|3] "" Vector__XXX
 SG_ CoolLv : 42|2@1+ (1,0) [0|3] "" Vector__XXX
 SG_ DefPrsLw : 40|2@1+ (1,0) [0|3] "" Vector__XXX
 SG_ WifMainFiltFault : 38|2@1+ (1,0) [0|3] "" Vector__XXX
 SG_ WifMainFiltWaterDetectFault : 36|2@1+ (1,0) [0|3] "" Vector__XXX
 SG_ WifPrePilotFault : 34|2@1+ (1,0) [0|3] "" Vector__XXX
 SG_ WifPrePilot : 32|2@1+ (1,0) [0|3] "" Vector__XXX
 SG_ FuelEmpty : 30|2@1+ (1,0) [0|3] "" Vector__XXX
 SG_ AutoSCrcondPrkns : 28|2@1+ (1,0) [0|3] "" Vector__XXX
 SG_ ExHhTempAmb : 24|2@1+ (1,0) [0|3] "" Vector__XXX
 SG_ ExHhTempGr : 22|2@1+ (1,0) [0|3] "" Vector__XXX
 SG_ DpfActRgnInhbtSt : 20|2@1+ (1,0) [0|3] "" Vector__XXX
 SG_ DpfRgnClg : 18|2@1+ (1,0) [0|3] "" Vector__XXX
 SG_ EgChkSrv : 16|2@1+ (1,0) [0|3] "" Vector__XXX
 SG_ EgChk2 : 14|2@1+ (1,0) [0|3] "" Vector__XXX
 SG_ EgChk1 : 12|2@1+ (1,0) [0|3] "" Vector__XXX
 SG_ EgStp : 10|2@1+ (1,0) [0|3] "" Vector__XXX
 SG_ EgWrn : 8|2@1+ (1,0) [0|3] "" Vector__XXX
 SG_ AirCln : 6|2@1+ (1,0) [0|3] "" Vector__XXX
 SG_ CoolLvSrgTnk : 4|2@1+ (1,0) [0|3] "" Vector__XXX
 SG_ CoolTmpOv : 2|2@1+ (1,0) [0|3] "" Vector__XXX
 SG_ EgOilPrs : 0|2@1+ (1,0) [0|3] "" Vector__XXX

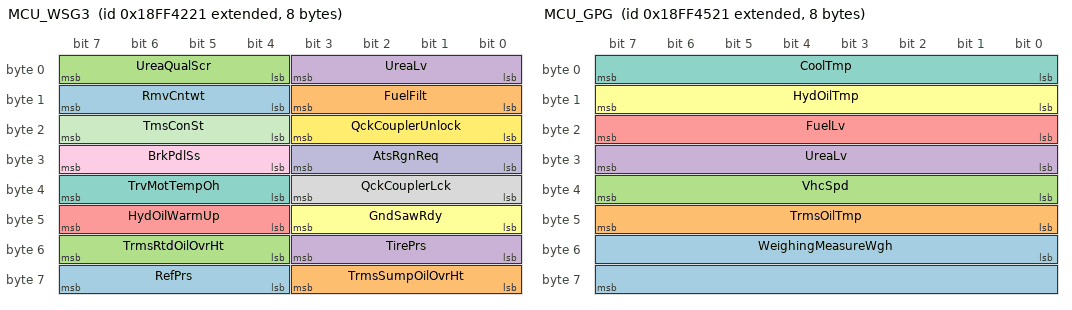
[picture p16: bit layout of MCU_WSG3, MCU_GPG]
BO_ 2566865441 MCU_WSG3: 8 MCU
 SG_ RefPrs : 60|4@1+ (1,0) [0|15] "" Vector__XXX
 SG_ TrmsSumpOilOvrHt : 56|4@1+ (1,0) [0|15] "" Vector__XXX
 SG_ TrmsRtdOilOvrHt : 52|4@1+ (1,0) [0|15] "" Vector__XXX
 SG_ TirePrs : 48|4@1+ (1,0) [0|15] "" Vector__XXX
 SG_ HydOilWarmUp : 44|4@1+ (1,0) [0|15] "" Vector__XXX
 SG_ GndSawRdy : 40|4@1+ (1,0) [0|15] "" Vector__XXX
 SG_ TrvMotTempOh : 36|4@1+ (1,0) [0|15] "" Vector__XXX
 SG_ QckCouplerLck : 32|4@1+ (1,0) [0|15] "" Vector__XXX
 SG_ BrkPdlSs : 28|4@1+ (1,0) [0|15] "" Vector__XXX
 SG_ AtsRgnReq : 24|4@1+ (1,0) [0|15] "" Vector__XXX
 SG_ TmsConSt : 20|4@1+ (1,0) [0|15] "" Vector__XXX
 SG_ QckCouplerUnlock : 16|4@1+ (1,0) [0|15] "" Vector__XXX
 SG_ RmvCntwt : 12|4@1+ (1,0) [0|15] "" Vector__XXX
 SG_ FuelFilt : 8|4@1+ (1,0) [0|15] "" Vector__XXX
 SG_ UreaQualScr : 4|4@1+ (1,0) [0|15] "" Vector__XXX
 SG_ UreaLv : 0|4@1+ (1,0) [0|15] "" Vector__XXX

BO_ 2566865697 MCU_SIG1: 8 MCU
 SG_ BzzCtrlCmd : 62|2@1+ (1,0) [0|3] "" Vector__XXX
 SG_ CurGr : 59|3@1+ (1,0) [0|7] "" Vector__XXX
 SG_ SelGr : 56|3@1+ (1,0) [0|7] "" Vector__XXX
 SG_ BoomFltBiDir : 55|1@1+ (1,0) [0|1] "" Vector__XXX
 SG_ Is3RdFNRElecStr : 54|1@1+ (1,0) [0|1] "" Vector__XXX
 SG_ IsFR : 53|1@1+ (1,0) [0|1] "" Vector__XXX
 SG_ IsElecStr : 52|1@1+ (1,0) [0|1] "" Vector__XXX
 SG_ IsOprRdy : 50|2@1+ (1,0) [0|3] "" Vector__XXX
 SG_ PreHt : 48|2@1+ (1,0) [0|3] "" Vector__XXX
 SG_ FaultCntAvm : 46|2@1+ (1,0) [0|3] "" Vector__XXX
 SG_ FaultCntMch : 44|2@1+ (1,0) [0|3] "" Vector__XXX
 SG_ CtrWrnLed : 43|1@1+ (1,0) [0|1] "" Vector__XXX
 SG_ ExBzz : 42|1@1+ (1,0) [0|1] "" Vector__XXX
 SG_ AutoShdnAval : 41|1@1+ (1,0) [0|1] "" Vector__XXX
 SG_ AutoShdnSt : 40|1@1+ (1,0) [0|1] "" Vector__XXX
 SG_ BrkrAct : 38|2@1+ (1,0) [0|3] "" Vector__XXX
 SG_ ThwLvErr : 37|1@1+ (1,0) [0|1] "" Vector__XXX
 SG_ AutoIdle : 36|1@1+ (1,0) [0|1] "" Vector__XXX
 SG_ RgnPrkns : 35|1@1+ (1,0) [0|1] "" Vector__XXX
 SG_ RpmCtrlRstrt : 34|1@1+ (1,0) [0|1] "" Vector__XXX
 SG_ IgnRstrtPilotCutOff : 33|1@1+ (1,0) [0|1] "" Vector__XXX
 SG_ IgnRstrtFRP : 32|1@1+ (1,0) [0|1] "" Vector__XXX
 SG_ OhPrv : 30|2@1+ (1,0) [0|3] "" Vector__XXX
 SG_ HhMntLgc : 28|2@1+ (1,0) [0|3] "" Vector__XXX
 SG_ AutoShdn : 27|1@1+ (1,0) [0|1] "" Vector__XXX
 SG_ FuelHt : 26|1@1+ (1,0) [0|1] "" Vector__XXX
 SG_ AutoWarmUpGr : 25|1@1+ (1,0) [0|1] "" Vector__XXX
 SG_ AutoWarmUpAmb : 24|1@1+ (1,0) [0|1] "" Vector__XXX
 SG_ HhBeam : 23|1@1+ (1,0) [0|1] "" Vector__XXX
 SG_ RamLck : 22|1@1+ (1,0) [0|1] "" Vector__XXX
 SG_ PrkBrk : 21|1@1+ (1,0) [0|1] "" Vector__XXX
 SG_ Trv : 20|1@1+ (1,0) [0|1] "" Vector__XXX
 SG_ FNR : 18|2@1+ (1,0) [0|3] "" Vector__XXX
 SG_ TrvMdWhl : 16|2@1+ (1,0) [0|3] "" Vector__XXX
 SG_ IsoBhl : 14|2@1+ (1,0) [0|3] "" Vector__XXX
 SG_ TwOpt : 12|2@1+ (1,0) [0|3] "" Vector__XXX
 SG_ WrkMd : 10|2@1+ (1,0) [0|3] "" Vector__XXX
 SG_ TrvMdCrw : 8|2@1+ (1,0) [0|3] "" Vector__XXX
 SG_ MrrHt : 7|1@1+ (1,0) [0|1] "" Vector__XXX
 SG_ AuxMdSt : 6|1@1+ (1,0) [0|1] "" Vector__XXX
 SG_ RvsFanSt : 5|1@1+ (1,0) [0|1] "" Vector__XXX
 SG_ SwPriSt : 4|1@1+ (1,0) [0|1] "" Vector__XXX
 SG_ BoomSwAct : 3|1@1+ (1,0) [0|1] "" Vector__XXX
 SG_ BoomFltSngDir : 2|1@1+ (1,0) [0|1] "" Vector__XXX
 SG_ PowMax : 1|1@1+ (1,0) [0|1] "" Vector__XXX
 SG_ WrkLmp : 0|1@1+ (1,0) [0|1] "" Vector__XXX

BO_ 2566866179 TCU_ZFETC9: 8 TCU

BO_ 2566866209 MCU_GPG: 8 MCU
 SG_ WeighingMeasureWgh : 48|16@1+ (1,0) [0|65535] "Kg" Vector__XXX
 SG_ TrmsOilTmp : 40|8@1+ (1,0) [0|250] "" Vector__XXX
 SG_ VhcSpd : 32|8@1+ (1,0) [0|250] "" Vector__XXX
 SG_ UreaLv : 24|8@1+ (1,0) [0|250] "" Vector__XXX
 SG_ FuelLv : 16|8@1+ (1,0) [0|250] "" Vector__XXX
 SG_ HydOilTmp : 8|8@1+ (1,0) [0|250] "" Vector__XXX
 SG_ CoolTmp : 0|8@1+ (1,0) [0|250] "" Vector__XXX

BO_ 2566866465 MCU_UPD: 8 MCU
 SG_ ArmAngInfo : 56|8@1+ (0.5,0) [0|125] "" Vector__XXX
 SG_ McTprRlsSig : 30|1@1+ (1,0) [0|1] "" Vector__XXX
 SG_ SetSwgBenchSig : 29|1@1+ (1,0) [0|1] "" Vector__XXX
 SG_ BckRefPtSig : 28|1@1+ (1,0) [0|1] "" Vector__XXX
 SG_ GrdAstMdSet : 27|1@1+ (1,0) [0|1] "" Vector__XXX
 SG_ DsnDepthCtrlMinusSig : 26|1@1+ (1,0) [0|1] "" Vector__XXX
 SG_ DsnDepthCtrlPlusSig : 25|1@1+ (1,0) [0|1] "" Vector__XXX
 SG_ DoubleGrdntCtrlMinusSig : 24|1@1+ (1,0) [0|1] "" Vector__XXX
 SG_ DoubleGrdntCtrlPlusSig : 23|1@1+ (1,0) [0|1] "" Vector__XXX
 SG_ DsnLoadMinusSig : 22|1@1+ (1,0) [0|1] "" Vector__XXX
 SG_ DsnLoadPlusSig : 21|1@1+ (1,0) [0|1] "" Vector__XXX
 SG_ UserDrawSetMinusSig : 20|1@1+ (1,0) [0|1] "" Vector__XXX
 SG_ UserDrawSetPlusSig : 19|1@1+ (1,0) [0|1] "" Vector__XXX
 SG_ GrdntCtrlMinusSig : 18|1@1+ (1,0) [0|1] "" Vector__XXX
 SG_ GrdntCtrlPlusSig : 17|1@1+ (1,0) [0|1] "" Vector__XXX
 SG_ BckAstSig : 16|1@1+ (1,0) [0|1] "" Vector__XXX
 SG_ SwgAstRSig : 15|1@1+ (1,0) [0|1] "" Vector__XXX
 SG_ SwgAstLSig : 14|1@1+ (1,0) [0|1] "" Vector__XXX
 SG_ GrdAstPrecisionSelSig : 13|1@1+ (1,0) [0|1] "" Vector__XXX
 SG_ GrdAstSig : 12|1@1+ (1,0) [0|1] "" Vector__XXX
 SG_ TruckCancelSig : 11|1@1+ (1,0) [0|1] "" Vector__XXX
 SG_ TruckStoreSig : 10|1@1+ (1,0) [0|1] "" Vector__XXX
 SG_ BckRecallSig : 9|1@1+ (1,0) [0|1] "" Vector__XXX
 SG_ BckCancelSig : 8|1@1+ (1,0) [0|1] "" Vector__XXX
 SG_ ReweighSig : 7|1@1+ (1,0) [0|1] "" Vector__XXX
 SG_ WeighingSig : 6|1@1+ (1,0) [0|1] "" Vector__XXX
 SG_ ReferencePtRlsSig : 5|1@1+ (1,0) [0|1] "" Vector__XXX
 SG_ LaserandTouchpointSig : 4|1@1+ (1,0) [0|1] "" Vector__XXX
 SG_ BmSig : 3|1@1+ (1,0) [0|1] "" Vector__XXX
 SG_ CamSig : 2|1@1+ (1,0) [0|1] "" Vector__XXX
 SG_ AdoMuteSig : 1|1@1+ (1,0) [0|1] "" Vector__XXX
 SG_ MultifuncJoyBtnSig : 0|1@1+ (1,0) [0|1] "" Vector__XXX

CM_ BO_ 2348810243 "Torque/Speed Control 1";
CM_ SG_ 2348810243 EgReqTrqTrqLmt "EngineRequestedTorque/TorqueLimit";
CM_ SG_ 2348810243 EgReqSpdSpdLmt "EngineRequestedSpeed/SpeedLimit";
CM_ SG_ 2348810243 OvrCtrlMdPri "OverrideControlModePriority";
CM_ SG_ 2348810243 EgOvrCtrlMd "EngineOverrideControlMode";
CM_ BO_ 2348810251 "Torque/Speed Control 1";
CM_ SG_ 2348810251 EgReqTrqTrqLmt "EngineRequestedTorque/TorqueLimit";
CM_ SG_ 2348810251 EgReqSpdSpdLmt "EngineRequestedSpeed/SpeedLimit";
CM_ SG_ 2348810251 OvrCtrlMdPri "OverrideControlModePriority";
CM_ SG_ 2348810251 EgOvrCtrlMd "EngineOverrideControlMode";
CM_ BO_ 2348810259 "Torque/Speed Control 1";
CM_ SG_ 2348810259 EgReqTrqTrqLmt "EngineRequestedTorque/TorqueLimit";
CM_ SG_ 2348810259 EgReqSpdSpdLmt "EngineRequestedSpeed/SpeedLimit";
CM_ SG_ 2348810259 OvrCtrlMdPri "OverrideControlModePriority";
CM_ SG_ 2348810259 EgOvrCtrlMd "EngineOverrideControlMode";
CM_ BO_ 2348810273 "Torque/Speed Control 1";
CM_ SG_ 2348810273 EgReqTrqTrqLmt "EngineRequestedTorque/TorqueLimit";
CM_ SG_ 2348810273 EgReqSpdSpdLmt "EngineRequestedSpeed/SpeedLimit";
CM_ SG_ 2348810273 OvrCtrlMdPri "OverrideControlModePriority";
CM_ SG_ 2348810273 EgOvrCtrlMd "EngineOverrideControlMode";
CM_ BO_ 2348814083 "Torque/Speed Control 1";
CM_ BO_ 2348814091 "Torque/Speed Control 1";
CM_ BO_ 2348814096 "Torque− Speed Control receive message from Adaptive cruise control unit to retarder";
CM_ BO_ 2348814099 "Torque− Speed Control receive message from Adaptive cruise control unit to retarder";
CM_ BO_ 2348814113 "Torque/Speed Control 1";
CM_ BO_ 2350579745 "High Voltage Energy Storage System Control 1";
CM_ BO_ 2351300641 "Motor/Generator 1 Inverter Control";
CM_ BO_ 2564816912 "Cab Message 1";
CM_ SG_ 2564816912 AtRgnFrcSw "AftertreatmentRegenerationForceSwitch";
CM_ SG_ 2564816912 AtRgnInhbSw "AftertreatmentRegenerationInhibitSwitch";
CM_ BO_ 2564816929 "Cab Message 1";
CM_ SG_ 2564816929 AtRgnFrcSw "AftertreatmentRegenerationForceSwitch";
CM_ SG_ 2564816929 AtRgnInhbSw "AftertreatmentRegenerationInhibitSwitch";
CM_ BO_ 2565800744 "GP Setting Message to TCU";
CM_ BO_ 2364478241 "Man Machine Interface – Primary";
CM_ BO_ 2565805864 "GP Setting Message to Cluster";
CM_ BO_ 2565808424 "GP Setting Message to VCU";
CM_ BO_ 2565808458 "VCU Setting Message  From TMS";
CM_ BO_ 2565810241 "Gateway Setting Message to GP";
CM_ BO_ 2565810250 "GP Setting Message  From TMS";
CM_ BO_ 2565810256 "Keypad Setting Message to GP";
CM_ BO_ 2565816616 "GP Setting Message to Gateway";
CM_ BO_ 2565818920 "GP Setting Message to TMS";
CM_ BO_ 2565820456 "GP Setting Message to Keypad";
CM_ BO_ 2565821480 "GP Setting Message to AVM";
CM_ BO_ 2565821505 "Gateway Setting Message to AVM";
CM_ BO_ 2364496417 "Man Machine Interface – Secondary";
CM_ BO_ 2565865487 "Electronic Retarder Controller 1";
CM_ BO_ 2565865488 "Electronic Retarder Controller 1";
CM_ BO_ 2565865733 "EBC1";
CM_ SG_ 2565865733 EgAuxShdnSw "EngineAuxiliaryShutdownSwitch";
CM_ BO_ 2565865739 "Electronic Brake Controller 1";
CM_ SG_ 2565865739 EgAuxShdnSw "EngineAuxiliaryShutdownSwitch";
CM_ BO_ 2364539395 "Electronic Transmission Controller 1";
CM_ SG_ 2364539395 TrmInShftSpd "TransInputShaftSpeed";
CM_ SG_ 2364539395 TrmsOutShftSpd "Transmission1OutputShaftSpeed";
CM_ SG_ 2364539395 InProTrmShft "TransShiftInProcess";
CM_ SG_ 2364539395 TrqCvtLckEng "TorqueConverterLockupEngaged";
CM_ SG_ 2364539395 TrmDrvEng "TransDrivelineEngaged";
CM_ BO_ 2364539648 "Electronic Engine Controller 2";
CM_ SG_ 2364539648 AccPdlPos2 "AcceleratorPedalPosition2";
CM_ SG_ 2364539648 EgPctLoadCurSpd "EnginePercentLoadAtCurrentSpeed";
CM_ SG_ 2364539648 AccPdlPos1 "AcceleratorPedalPosition1";
CM_ BO_ 2364539904 "Electronic Engine Controller 1";
CM_ SG_ 2364539904 EgSpd "EngineSpeed";
CM_ SG_ 2364539904 ActEgPctTrq "ActualEngine-PercentTorque";
CM_ SG_ 2364539904 DrvDmdEgPctTrq "Driver'sDemandEngine-PercentTorque";
CM_ BO_ 2565866755 "ETC2";
CM_ SG_ 2565866755 TrmsCurGr "TransCurrentGear";
CM_ SG_ 2565866755 TrmsActGrRatio "TransActualGearRatio";
CM_ SG_ 2565866755 TrmsSelGr "TransSelectedGear";
CM_ BO_ 2565867011 "EAC1";
CM_ SG_ 2565867011 DifLckStCtrEng "DiffLockStateCentral";
CM_ BO_ 2364542241 "Land levelling system operational information";
CM_ SG_ 2364542241 BladeAutoMdCmd "BladeAutoModeCommand";
CM_ SG_ 2364542241 DsrGrdOfsSw "DesiredGradeOffsetSwitch";
CM_ SG_ 2364542241 BladeCtrlMdSw "BladeControlModeSwitch";
CM_ BO_ 2565869137 "Aftertreatment 1 Intake Gas 1";
CM_ SG_ 2565869137 AtIntGasSsHtCtrl "Aftertreatment1IntakeGasSensorHeaterControl";
CM_ SG_ 2565869137 InRngAtIntGasSsTmp "Aftertreatment1IntakeGasSensoratTemperature";
CM_ BO_ 2565869394 "Aftertreatment 1 Outlet Gas 1";
CM_ SG_ 2565869394 AtOutGasSsHtCtrl "Aftertreatment1OutletGasSensorHeaterControl";
CM_ SG_ 2565869394 InRngAtOutGasSsTmp "Aftertreatment1OutletGasSensoratTemperature";
CM_ BO_ 2565875998 "Slope Sensor Information 2";
CM_ BO_ 2565876161 "Slope Sensor Information 2";
CM_ BO_ 2565876162 "Slope Sensor Information 2";
CM_ BO_ 2565876163 "Slope Sensor Information 2";
CM_ BO_ 2565876164 "Slope Sensor Information 2";
CM_ BO_ 2565876165 "Slope Sensor Information 2";
CM_ BO_ 2364575987 "High Voltage Energy Storage System Data 1";
CM_ BO_ 2364576243 "High Voltage Energy Storage System Data 2";
CM_ BO_ 2364576755 "High Voltage Energy Storage System Data 4";
CM_ BO_ 2364577011 "High Voltage Energy Storage System Data 5";
CM_ BO_ 2364577267 "High Voltage Energy Storage System Data 6";
CM_ BO_ 2364637584 "Motor/Generator 1 Inverter Mode Feedback 1";
CM_ BO_ 2364641057 "PG Impostor Alert Message";
CM_ SG_ 2364641057 TmSinceLastIpsPgDtt "Time Since Last Impostor PG Detected";
CM_ SG_ 2364641057 IpsPgn "Impostor PGN";
CM_ SG_ 2364641057 IpsPgDA "Impostor PG Destination Address";
CM_ SG_ 2364641057 IpsPgSA "Impostor PG Source Address";
CM_ SG_ 2364641057 IpsPgEventDttCounter "Impostor PG Event Detection Counter";
CM_ BO_ 2364641267 "PG Impostor Alert Message";
CM_ SG_ 2364641267 TmSinceLastIpsPgDtt "Time Since Last Impostor PG Detected";
CM_ SG_ 2364641267 IpsPgn "Impostor PGN";
CM_ SG_ 2364641267 IpsPgDA "Impostor PG Destination Address";
CM_ SG_ 2364641267 IpsPgSA "Impostor PG Source Address";
CM_ SG_ 2364641267 IpsPgEventDttCounter "Impostor PG Event Detection Counter";
CM_ BO_ 2365288848 "Motor/Generator 1 Inverter Motor Temperature";
CM_ BO_ 2365289104 "Motor/Generator 1 Inverter Temperature";
CM_ BO_ 2365289360 "Motor/Generator 1 Inverter Reference 2";
CM_ BO_ 2365289616 "Motor/Generator 1 Inverter Status 1";
CM_ BO_ 2566675955 "High Voltage Energy Storage System Configuration";
CM_ BO_ 2633785075 "High Voltage Energy Storage System History";
CM_ BO_ 2566709248 "Diesel Particulate Filter Control 2";
CM_ BO_ 2633828415 "Oil Quality Message 1";
CM_ SG_ 2633828415 Oildieleccst "Oil dielectric constant";
CM_ SG_ 2633828415 Oildensity "Oil density";
CM_ SG_ 2633828415 OilVcsty "Oil viscosity";
CM_ BO_ 2633828526 "Oil Quality Message 1";
CM_ SG_ 2633828526 Oildieleccst "Oil dielectric constant";
CM_ SG_ 2633828526 Oildensity "Oil density";
CM_ SG_ 2633828526 OilVcsty "Oil viscosity";
CM_ BO_ 2566719744 "High Resolution Fuel Consumption (Liquid)";
CM_ BO_ 2365394514 "Aftertreatment 1 Outlet Gas NOx Sensor Correction Data 2";
CM_ BO_ 2365394770 "Aftertreatment 1 Outlet Gas NOx Sensor Correction Data 1";
CM_ BO_ 2365395025 "Aftertreatment 1 Intake Gas NOx Sensor Correction Data 2";
CM_ BO_ 2365395281 "Aftertreatment 1 Intake Gas NOx Sensor Correction Data 1";
CM_ BO_ 2566722989 "Battery Charger 1";
CM_ BO_ 2566725632 "Aftertreatment 1 Diesel Oxidation Catalyst";
CM_ SG_ 2566725632 At1DocDifPrsPrlFmi "Aftertreatment 1 Diesel Oxidation Catalyst Differential Pressure Preliminary FMI";
CM_ SG_ 2566725632 At1DocOutTmpPrlFmi "Aftertreatment 1 Diesel Oxidation Catalyst Outlet Temperature Preliminary FMI";
CM_ SG_ 2566725632 At1DocInTmpPrlFmi "Aftertreatment 1 Diesel Oxidation Catalyst Intake Temperature Preliminary FMI";
CM_ SG_ 2566725632 At1DocDifPrs "Aftertreatment 1 Diesel Oxidation Catalyst Differential Pressure";
CM_ SG_ 2566725632 At1DocOutTmp "Aftertreatment 1 Diesel Oxidation Catalyst Outlet Temperature";
CM_ SG_ 2566725632 At1DocInTmp "Aftertreatment 1 Diesel Oxidation Catalyst Intake Temperature";
CM_ BO_ 2566748928 "Aftertreatment 1 Outlet Gas 2";
CM_ SG_ 2566748928 DpfSootLoadPct "DieselParticulateFilter1SootLoadPercent";
CM_ BO_ 2566749184 "Diesel Particulate Filter Control 1";
CM_ SG_ 2566749184 At1DpfCondNotMetforActvRgn "Aftertreatment 1 Diesel Particulate Filter Conditions Not Met for Active Regeneration";
CM_ SG_ 2566749184 DpfActvRgnIhbDuetoLowExhPrs "Diesel Particulate Filter Active Regeneration Inhibited Due to Low Exhaust Pressure";
CM_ SG_ 2566749184 HydrocarbonDoserPurgingEnb "Hydrocarbon Doser Purging Enable";
CM_ SG_ 2566749184 DpfActvRgnForcedSt "Diesel Particulate Filter Active Regeneration Forced Status";
CM_ SG_ 2566749184 ExhSysHhTmpLmpCmd "Exhaust System High Temperature Lamp Command";
CM_ SG_ 2566749184 DpfAutoActvRgnInitiationConfig "Diesel Particulate Filter Automatic Active Regeneration Initiation Configuration";
CM_ SG_ 2566749184 DpfActvRgnIhbVhcSpdBelowAllowedS "Diesel Particulate Filter Active Regeneration Inhibited Due to Vehicle Speed Below Allowed Speed";
CM_ SG_ 2566749184 DpfActvRgnIhbEgNotWarmedUp "Diesel Particulate Filter Active Regeneration Inhibited Due to Engine Not Warmed Up";
CM_ SG_ 2566749184 DpfActvRgnIhbPmnSysLockout "Diesel Particulate Filter Active Regeneration Inhibited Due to Permanent System Lockout";
CM_ SG_ 2566749184 DpfActvRgnIhbTprSysLockout "Diesel Particulate Filter Active Regeneration Inhibited Due to Temporary System Lockout";
CM_ SG_ 2566749184 DpfActvRgnIhbSysTmout "Diesel Particulate Filter Active Regeneration Inhibited Due to System Timeout";
CM_ SG_ 2566749184 DpfActvRgnIhbSysFaultActv "Diesel Particulate Filter Active Regeneration Inhibited Due to System Fault Active";
CM_ SG_ 2566749184 DpfActvRgnIhbLowExhTmp "Diesel Particulate Filter Active Regeneration Inhibited Due to Low Exhaust Temperature";
CM_ SG_ 2566749184 DpfActvRgnIhbPrkBrkNotSet "Diesel Particulate Filter Active Regeneration Inhibited Due to Parking Brake Not Set";
CM_ SG_ 2566749184 DpfActvRgnIhbVhcSpdAboveAllowedS "Diesel Particulate Filter Active Regeneration Inhibited Due to Vehicle Speed Above Allowed Speed";
CM_ SG_ 2566749184 DpfActvRgnIhbOutofNtrl "Diesel Particulate Filter Active Regeneration Inhibited Due to Out of Neutral";
CM_ SG_ 2566749184 DpfActvRgnIhbAccPdlOffIdle "Diesel Particulate Filter Active Regeneration Inhibited Due to Accelerator Pedal Off Idle";
CM_ SG_ 2566749184 DpfActvRgnIhbPtoActv "Diesel Particulate Filter Active Regeneration Inhibited Due to PTO Active";
CM_ SG_ 2566749184 DpfActvRgnIhbServiceBrkActv "Diesel Particulate Filter Active Regeneration Inhibited Due to Service Brake Active";
CM_ SG_ 2566749184 DpfActvRgnIhbClutchDisengaged "Diesel Particulate Filter Active Regeneration Inhibited Due to Clutch Disengaged";
CM_ SG_ 2566749184 DpfActvRgnIhbInhibitSwitch "Diesel Particulate Filter Active Regeneration Inhibited Due to Inhibit Switch";
CM_ SG_ 2566749184 DpfActvRgnIhbSt "Diesel Particulate Filter Active Regeneration Inhibited Status";
CM_ SG_ 2566749184 AtDpfSt "Aftertreatment Diesel Particulate Filter Status";
CM_ SG_ 2566749184 AtDpfActvRgnSt "Aftertreatment Diesel Particulate Filter Active Regeneration Status";
CM_ SG_ 2566749184 AtDpfPassiveRgnSt "Aftertreatment Diesel Particulate Filter Passive Regeneration Status";
CM_ SG_ 2566749184 DpfActvRgnAvailabilitySt "Diesel Particulate Filter Active Regeneration Availability Status";
CM_ SG_ 2566749184 DpfLampCmd "Diesel Particulate Filter Lamp Command";
CM_ BO_ 2566755587 "TRF2";
CM_ SG_ 2566755587 TrqCvtOilOutTmp "TRF2TrqueConverterOilOutletTemp";
CM_ SG_ 2566755587 TrmOilFiltRstrSw "TRF2TrmOilFilterRestrictSwitch";
CM_ BO_ 2566757120 "Aftertreatment 1 Diesel Exhaust Fluid Information 1";
CM_ SG_ 2566757120 AtDefPpt "Aftertreatment1DieselExhaustFluidProperty";
CM_ SG_ 2566757120 AtDefCct "Aftertreatment1DieselExhaustFluidConcentration";
CM_ BO_ 2566758656 "Aftertreatment1 Fuelcontrol Frame1";
CM_ SG_ 2566758656 AtFuelInjHtCtrl "Aftertreatment1FuelInjector1HeaterControl";
CM_ SG_ 2566758656 AtIgn "Aftertreatment1Ignition";
CM_ SG_ 2566758656 AtFuelPrsCtrl "Aftertreatment1FuelPressure1Control";
CM_ SG_ 2566758656 AtFuelRate "Aftertreatment1FuelRate";
CM_ SG_ 2566758656 AtFuelPrs "Aftertreatment1FuelPressure1";
CM_ BO_ 2566763008 "Aftertreatment 1 Intermediate Gas";
CM_ SG_ 2566763008 At1DpfIntmTmpPrlFmi "Aftertreatment 1 Diesel Particulate Filter Intermediate Temperature Preliminary FMI";
CM_ SG_ 2566763008 At1DpfDifPrsPrlFmi "Aftertreatment 1 Diesel Particulate Filter Differential Pressure Preliminary FMI";
CM_ SG_ 2566763008 At1ExhTmp2PrlFmi "Aftertreatment 1 Exhaust Temperature 2 Preliminary FMI";
CM_ SG_ 2566763008 At1DpfDifPrs "Aftertreatment 1 Diesel Particulate Filter Differential Pressure";
CM_ SG_ 2566763008 At1DpfIntmTmp "Aftertreatment 1 Diesel Particulate Filter Intermediate Temperature";
CM_ SG_ 2566763008 At1ExhTmp2 "Aftertreatment 1 Exhaust Temperature 2";
CM_ BO_ 2566763264 "Aftertreatment 1 Outlet Gas 2";
CM_ SG_ 2566763264 At1DpfOutExhTmpPrlFmi "Aftertreatment 1 Diesel Particulate Filter Outlet Exhaust Temperature Preliminary FMI";
CM_ SG_ 2566763264 At1ExhTmp3PrlFmi "Aftertreatment 1 Exhaust Temperature 3 Preliminary FMI";
CM_ SG_ 2566763264 At1DpfOutTmp "Aftertreatment 1 Diesel Particulate Filter Outlet Temperature";
CM_ SG_ 2566763264 At1ExhTmp3 "Aftertreatment 1 Exhaust Temperature 3";
CM_ BO_ 2566763325 "Aftertreatment 1 Outlet Gas 2";
CM_ SG_ 2566763325 At1DpfOutExhTmpPrlFmi "Aftertreatment 1 Diesel Particulate Filter Outlet Exhaust Temperature Preliminary FMI";
CM_ SG_ 2566763325 At1ExhTmp3PrlFmi "Aftertreatment 1 Exhaust Temperature 3 Preliminary FMI";
CM_ SG_ 2566763325 At1DpfOutTmp "Aftertreatment 1 Diesel Particulate Filter Outlet Temperature";
CM_ SG_ 2566763325 At1ExhTmp3 "Aftertreatment 1 Exhaust Temperature 3";
CM_ BO_ 2566763520 "Aftertreatment 1 Intake Gas 2";
CM_ SG_ 2566763520 At1DpfInTmpPrlFmi "Aftertreatment 1 Diesel Particulate Filter Intake Temperature Preliminary FMI";
CM_ SG_ 2566763520 At1ExhTmp1PrlFmi "Aftertreatment 1 Exhaust Temperature 1 Preliminary FMI";
CM_ SG_ 2566763520 At1DpfInTmp "Aftertreatment 1 Diesel Particulate Filter Intake Temperature";
CM_ SG_ 2566763520 At1ExhTmp1 "Aftertreatment 1 Exhaust Temperature 1";
CM_ BO_ 2566763581 "Aftertreatment 1 Intake Gas 2";
CM_ SG_ 2566763581 At1DpfInTmpPrlFmi "Aftertreatment 1 Diesel Particulate Filter Intake Temperature Preliminary FMI";
CM_ SG_ 2566763581 At1ExhTmp1PrlFmi "Aftertreatment 1 Exhaust Temperature 1 Preliminary FMI";
CM_ SG_ 2566763581 At1DpfInTmp "Aftertreatment 1 Diesel Particulate Filter Intake Temperature";
CM_ SG_ 2566763581 At1ExhTmp1 "Aftertreatment 1 Exhaust Temperature 1";
CM_ BO_ 2365441523 "PG engcon AGW ECU Identification Information";
CM_ BO_ 2566769997 "Operator Wiper and Washer Controls Message";
CM_ SG_ 2566769997 FrOprtWashSw "Front Operator Washer Switch";
CM_ SG_ 2566769997 FrOprtWiperDlyCtrl "Front Operator Wiper Delay Control";
CM_ SG_ 2566769997 FrOprtWiperSw "Front Operator Wiper Switch";
CM_ BO_ 2566771968 "Electronic Engine Controller 5";
CM_ SG_ 2566771968 EgEgrVvCtrl "EngineExhaustGasRecirculation1(EGR1)ValveControl";
CM_ BO_ 2365445841 "Basic Joystick Message 1";
CM_ BO_ 2365446097 "Extended Joystick Message 1";
CM_ BO_ 2365446352 "Basic Joystick Message 2";
CM_ BO_ 2365446608 "Extended Joystick Message 2";
CM_ BO_ 2365446893 "Basic Joystick Message 3";
CM_ BO_ 2365446894 "Basic Joystick Message 3";
CM_ BO_ 2365446895 "Basic Joystick Message 3";
CM_ BO_ 2365446896 "Basic Joystick Message 3";
CM_ BO_ 2365468962 "Auxiliary Valve Number 1 Command";
CM_ SG_ 2365468962 PortFlowHighResolution "PortFlow(HighResolution)";
CM_ SG_ 2365468962 FailSafeMd "FailSafeMode";
CM_ SG_ 2365468962 VvSt "ValveState";
CM_ SG_ 2365468962 ResolutionMd "ResolutionMode";
CM_ SG_ 2365468962 AuxVv1PortFlowCmd "AuxValve1PortFlowCommand";
CM_ BO_ 2365469218 "Auxiliary Valve Number 2 Command";
CM_ SG_ 2365469218 PortFlowHighResolution "PortFlow(HighResolution)";
CM_ SG_ 2365469218 FailSafeMd "FailSafeMode";
CM_ SG_ 2365469218 VvSt "ValveState";
CM_ SG_ 2365469218 ResolutionMd "ResolutionMode";
CM_ SG_ 2365469218 AuxVv1PortFlowCmd "AuxValve1PortFlowCommand";
CM_ BO_ 2365473101 "Lighting Command";
CM_ SG_ 2365473101 LTurnSigLhtsCmd "Left Turn Signal Lights Command";
CM_ SG_ 2365473101 RTurnSigLhtsCmd "Right Turn Signal Lights Command";
CM_ SG_ 2365473101 HighBeamHeadLhtCmd "High Beam Head Light Command";
CM_ SG_ 2365473101 LowBeamHeadLhtCmd "Low Beam Head Light Command";
CM_ SG_ 2365473101 AltBeamHeadLhtCmd "Alternate Beam Head Light Command";
CM_ BO_ 2566801441 "Wheel-based Speed and Distance";
CM_ BO_ 2566801923 "Electronic Transmission Controller 7";
CM_ BO_ 2566802176 "Transmission Configuration 2";
CM_ SG_ 2566802176 EgThrtActCtrlCmd "EngineThrottleActuator1ControlCommand";
CM_ BO_ 2566803211 "Vehicle Dynamic Stability Control 1";
CM_ BO_ 2566804992 "Aftertreatment 1 Diesel Exhaust Fluid Tank 1 Information 1";
CM_ SG_ 2566804992 AtSelCatalRedOprIndAct "AftertreatmentSelectiveCatalyticReductionOperatorInducementActive";
CM_ SG_ 2566804992 AtDefTnkTmp "Aftertreatment1DieselExhaustFluidTankTemperature";
CM_ SG_ 2566804992 AtDefTnkLv "Aftertreatment1DieselExhaustFluidTankLevel";
CM_ BO_ 2566804993 "Aftertreatment 1 Diesel Exhaust Fluid Tank 1 Information 1";
CM_ SG_ 2566804993 AtSelCatalRedOprIndAct "AftertreatmentSelectiveCatalyticReductionOperatorInducementActive";
CM_ SG_ 2566804993 AtDefTnkTmp "Aftertreatment1DieselExhaustFluidTankTemperature";
CM_ SG_ 2566804993 AtDefTnkLv "Aftertreatment1DieselExhaustFluidTankLevel";
CM_ BO_ 2365484270 "Tachograph";
CM_ BO_ 2566811147 "High Resolution Wheel Speed";
CM_ BO_ 2633927682 "Auxiliary Analog Information";
CM_ BO_ 2566831360 "Fan Drive #1";
CM_ SG_ 2566831360 FanDrvBypassCmdSt "Fan Drive Bypass Command Status";
CM_ SG_ 2566831360 HyhFanMotorPrs "Hydraulic Fan Motor Pressure";
CM_ SG_ 2566831360 FanSpd "Fan Speed";
CM_ SG_ 2566831360 FanDrvSt "Fan Drive State";
CM_ SG_ 2566831360 EgFan1EstimatedPctSpd "Engine Fan 1 Estimated Percent Speed";
CM_ BO_ 2566831616 "Electronic Engine Controller 4";
CM_ BO_ 2566831883 "Wheel Speed Information";
CM_ BO_ 2566832622 "High Resolution Vehicle Distance";
CM_ BO_ 2566834688 "Active Diagnostic Trouble Codes";
CM_ BO_ 2566834749 "Active Diagnostic Trouble Codes";
CM_ BO_ 2566834944 "Previously Active Diagnostic Trouble Codes";
CM_ BO_ 2566835456 "Freeze Frame Parameters";
CM_ BO_ 2566835712 "Diagnostic Readiness 1";
CM_ BO_ 2566835968 "Pending DTCs ";
CM_ BO_ 2566838528 "Auxiliary Input/Output Status 1";
CM_ BO_ 2566839296 "Idle Operation";
CM_ BO_ 2566840064 "Electronic Engine Controller 3";
CM_ SG_ 2566840064 At1ExhGasMasFlw "Aftertreatment1ExhaustGasMassFlow";
CM_ SG_ 2566840064 EgDsrOprSpd "Engine'sDesiredOperatingSpeed";
CM_ SG_ 2566840064 NrmFricPctTrq "NominalFriction-PercentTorque";
CM_ BO_ 2566841344 "Shutdown";
CM_ BO_ 2566841600 "Engine Hours, Revolutions";
CM_ SG_ 2566841600 EgTotRev "EngineTotalRevolutions";
CM_ SG_ 2566841600 EgTotHrOpr "EngineTotalHoursofOperation";
CM_ BO_ 2566841879 "Time/Date";
CM_ BO_ 2566842094 "Time/Date";
CM_ BO_ 2566842112 "Vehicle Electrical Power 1";
CM_ BO_ 2566842624 "Fuel Consumption (Liquid) 1";
CM_ SG_ 2566842624 EgTotFuelUsed "EngineTotalFuelUsed";
CM_ SG_ 2566842624 EgTripFuel "EngineTripFuel";
CM_ BO_ 2566843136 "Component Identification";
CM_ BO_ 2566843392 "Vehicle Identification";
CM_ BO_ 2566843648 "Cruise Control/Vehicle Speed Setup";
CM_ BO_ 2566843651 "Cruise Control/Vehicle Speed Setup";
CM_ BO_ 2566843653 "Cruise Control/Vehicle Speed Setup";
CM_ BO_ 2566843904 "Engine Temperature 1";
CM_ SG_ 2566843904 EgChgAirCoolThrmst "EngChargeAirCoolThrmsttOpening";
CM_ SG_ 2566843904 EgInCoolTmp "EngineInterCoolerTemperature";
CM_ SG_ 2566843904 EgTurboChgOilTmp "EngineTurbochargerOilTemperature";
CM_ SG_ 2566843904 EgOilTmp1 "EngineOilTemperature1";
CM_ SG_ 2566843904 EgFuelTmp "EngineFuelTemperature1";
CM_ SG_ 2566843904 EgCoolTmp "EngineCoolantTemperature";
CM_ BO_ 2566843967 "Oil Temperature";
CM_ SG_ 2566843967 OilAvrgTmp "Oil average temperature";
CM_ BO_ 2566844078 "Oil Temperature";
CM_ SG_ 2566844078 OilAvrgTmp "Oil average temperature";
CM_ BO_ 2566844160 "Engine Fluid Level/Pressure 1";
CM_ SG_ 2566844160 EgCoolLv "EngineCoolantLevel";
CM_ SG_ 2566844160 EgCrkcasePrs "EngineCrankcasePressure";
CM_ SG_ 2566844160 EgOilPrs "EngineOilPressure";
CM_ SG_ 2566844160 EgFuelDlvPrs "EngineFuelDeliveryPressure";
CM_ BO_ 2566844672 "Cruise Control/Vehicle Speed 1";
CM_ SG_ 2566844672 WhlVhcSpd "WheelBasedVehicleSpeed";
CM_ BO_ 2566844675 "Cruise Control/Vehicle Speed 1";
CM_ SG_ 2566844675 WhlVhcSpd "WheelBasedVehicleSpeed";
CM_ BO_ 2566844705 "Cruise Control/Vehicle Speed 1";
CM_ SG_ 2566844705 WhlVhcSpd "WheelBasedVehicleSpeed";
CM_ BO_ 2566844928 "Fuel Economy";
CM_ SG_ 2566844928 EgThrtVvPos "EngineThrottleValve1Position";
CM_ SG_ 2566844928 EgFuelRate "EngineFuelRate";
CM_ BO_ 2566845696 "Ambient Conditions";
CM_ SG_ 2566845696 EgAirIntTmp "EngineAirIntakeTemperature";
CM_ SG_ 2566845696 AmbAirTmp "AmbientAirTemperature";
CM_ SG_ 2566845696 BaroPrs "BarometricPressure";
CM_ BO_ 2566845952 "Intake/Exhaust Conditions 1";
CM_ SG_ 2566845952 EgAirIntPrs "EngineAirIntakePressure";
CM_ SG_ 2566845952 EgIntMnfdTmp "EngineIntakeManifold1Temperature";
CM_ SG_ 2566845952 EgIntMnfdPrs "EngineIntakeManifold#1Pressure";
CM_ BO_ 2566846208 "Vehicle Electrical Power 1";
CM_ SG_ 2566846208 KeyswBatPtc "KeyswitchBatteryPotential";
CM_ SG_ 2566846208 BatPtcPowIn "BatteryPotential/PowerInput1";
CM_ BO_ 2566846467 "Transmission Fluids 1";
CM_ BO_ 2566846981 "Brakes 1";
CM_ BO_ 2566847235 "Retarder fluids";
CM_ SG_ 2566847235 TrmOilFiltRstrSw "TRF2TrmOilFilterRestrictSwitch";
CM_ BO_ 2566847511 "Dash Display 1";
CM_ BO_ 2566847521 "Dash Display 1";
CM_ BO_ 2566848256 "Operator indicators";
CM_ BO_ 2566849085 "Send message Exhaust Gas Sensor for Particulate Matter";
CM_ BO_ 2566851074 "Receiving and evaluating the ACTVCODE frame";
CM_ BO_ 2566852897 "Safety Message VCU";
CM_ SG_ 2566852897 MsgCs "MessageChecksum";
CM_ SG_ 2566852897 MsgCnt "MessageCounter";
CM_ SG_ 2566852897 PrkBrkSw "ParkingBrakeSwitch";
CM_ SG_ 2566852897 StartCtrlReq "StarterControlRequest";
CM_ SG_ 2566852897 VhcSpd "VehicleSpeed";
CM_ SG_ 2566852897 CCAccSw "CruiseControlAccelerateSwitch";
CM_ SG_ 2566852897 CCRsmSw "CruiseControlResumeSwitch";
CM_ SG_ 2566852897 CCCoastSw "CruiseControlCoast(Decelerate)Switch";
CM_ SG_ 2566852897 CCSetSw "CruiseControlSetSwitch";
CM_ SG_ 2566852897 PtoSt "PTOstate";
CM_ SG_ 2566852897 RddtBrk "RedundantBreak";
CM_ SG_ 2566852897 BrkSw "BrakeSwitch";
CM_ SG_ 2566852897 LisSw "LISSwitch";
CM_ SG_ 2566852897 FinAccPdlPos "FinalAcceleratorPedalPostion";
CM_ BO_ 2365527585 "Auxiliary Steering Device (Joystick) - Primary";
CM_ SG_ 2365527585 Crc16forDtbytes "CRC16fordatabytes(1~6)";
CM_ SG_ 2365527585 Errorcode "Errorcode";
CM_ SG_ 2365527585 SequenceNo "Sequencenumber";
CM_ SG_ 2365527585 JoyEnbsignal "JoystickEnablesignal";
CM_ SG_ 2365527585 JoyNtrlPostrim "Joystickneutralpositiontrim";
CM_ SG_ 2365527585 JoyPos "JoystickPosition";
CM_ BO_ 2365527841 "Auxiliary Steering Device (Joystick) – Redundant";
CM_ SG_ 2365527841 Crc16forDtbytes "CRC16fordatabytes(1~6)";
CM_ SG_ 2365527841 Errorcode "Errorcode";
CM_ SG_ 2365527841 SequenceNo "Sequencenumber";
CM_ SG_ 2365527841 JoyEnbsignal "JoystickEnablesignal";
CM_ SG_ 2365527841 JoyNtrlPostrim "Joystickneutralpositiontrim";
CM_ SG_ 2365527841 JoyPos "JoystickPosition";
CM_ BO_ 2365528097 "Vehicle Speed – Primary";
CM_ SG_ 2365528097 Crc16forDtbytes "CRC16fordatabytes(1~6)";
CM_ SG_ 2365528097 SequenceNo "Sequencenumber";
CM_ SG_ 2365528097 VhcSpd "VehicleSpeed";
CM_ SG_ 2365528097 DirIndication "Directionindication";
CM_ BO_ 2365528353 "Vehicle Speed – Redundant";
CM_ SG_ 2365528353 Crc16forDtbytes "CRC16fordatabytes(1~6)";
CM_ SG_ 2365528353 SequenceNo "Sequencenumber";
CM_ SG_ 2365528353 VhcSpd "VehicleSpeed";
CM_ SG_ 2365528353 Drtindication "Directionindication";
CM_ BO_ 2566856451 "TCU_2";
CM_ BO_ 2566856707 "TCU_3";
CM_ BO_ 2365530117 "SpeedLimit_Prop1";
CM_ BO_ 2566856960 "EDC to Body Computer EDC2BC CAN message CAN";
CM_ SG_ 2566856960 DpfSootLv "DPFSootLevel";
CM_ SG_ 2566856960 EdcOprSt "EDCOperationalStatus";
CM_ SG_ 2566856960 EgDgrdLv "EngineDegradationLevel";
CM_ SG_ 2566856960 EgOilTmpHh "EngineOilTemperatureHigh";
CM_ SG_ 2566856960 FuelFiltHtSt "FuelFilterHeaterStatus";
CM_ SG_ 2566856960 WifWrn "WaterInFuelDetection";
CM_ SG_ 2566856960 EgOilPrsLw "EngineOilPressureLow";
CM_ SG_ 2566856960 BtnStp "StopButtonStatus";
CM_ SG_ 2566856960 RgnLmp "RegenerationLampStatus";
CM_ SG_ 2566856960 HydPmpActReq "Hydraulicpumpactivationrequest/Forcedregenerationstatus";
CM_ SG_ 2566856960 MIL "MILStatus";
CM_ SG_ 2566856960 EgOvrSpd "EngineOverspeed";
CM_ SG_ 2566856960 SpdLmtLmp "VehicleSpeedLimiterLampStatus";
CM_ SG_ 2566856960 DiagLmp "DiagnosticLampStatus";
CM_ SG_ 2566856960 FuelBlock "FuelBlockStatusByTheImmobilizer";
CM_ SG_ 2566856960 ColdStartHt "ColdStartHeaterStatus";
CM_ BO_ 2365530373 "SpeedLimit_Prop2";
CM_ BO_ 2566857219 "TCU_4";
CM_ SG_ 2566857219 CnvtTurbTrq "ConverterTurbineTorque";
CM_ SG_ 2566857219 CnvtPmpTrq "ConverterPumpTorque";
CM_ BO_ 2566857731 "ZFCC";
CM_ BO_ 2566857984 "Engine operating condition Frame CAN";
CM_ SG_ 2566857984 PhsDifCrkCam "Phasedifferencebetweencrankandcam";
CM_ SG_ 2566857984 EgOprCmd "Engineoperatingcondition";
CM_ SG_ 2566857984 AirMassPrs "Airmass";
CM_ BO_ 2566858752 "Receive Frame to control fan speed";
CM_ SG_ 2566858752 RedFanSpd100 "statusmessagetoreducefanspeedby100%";
CM_ SG_ 2566858752 RedFanSpd70 "statusmessagetoreducefanspeedby70%";
CM_ SG_ 2566858752 RedFanSpd50 "statusmessagetoreducefanspeedby50%";
CM_ SG_ 2566858752 RedFanSpd30 "statusmessagetoreducefanspeedby30%";
CM_ SG_ 2566858752 RedFanSpd0 "statusmessagetoreducefanspeedby0%";
CM_ BO_ 2566859297 "VEHICLE_2";
CM_ BO_ 2566859523 "TCU_1";
CM_ SG_ 2566859523 IsEngDrvSt "Driveline_status";
CM_ SG_ 2566859523 InProcShftSt "Shift_status";
CM_ SG_ 2566859523 OpMd "OP_mode";
CM_ SG_ 2566859523 IsActJoyMd "Joystick_Mode";
CM_ SG_ 2566859523 CurDir "Current_dir";
CM_ SG_ 2566859523 CurGr "Current_gear";
CM_ SG_ 2566859523 DifLck "DifferentialLock";
CM_ SG_ 2566859523 ShftDir "Shifter_direction";
CM_ SG_ 2566859523 ShftRng "Shifter_range";
CM_ SG_ 2566859523 ErrCode "Error_code";
CM_ SG_ 2566859523 OutSpd "Output_speed";
CM_ SG_ 2566859523 EgSpd "Engine_speed";
CM_ BO_ 2566860833 "VCU High Voltage Control Information";
CM_ SG_ 2566860833 ChgSt "ChargingStatus";
CM_ SG_ 2566860833 MchKeyOnSt "MachineStatus";
CM_ SG_ 2566860833 OnBrdChgCmd "OnBoardChargerCommand";
CM_ SG_ 2566860833 QckChgEnableCmd "QuickChargerCommand";
CM_ SG_ 2566860833 PowDnCmd "Power-DownCommand";
CM_ BO_ 2566861056 "TFI4 Command CAN frame";
CM_ SG_ 2566861056 FiltTm "Filtertime";
CM_ SG_ 2566861056 Cmd "Command";
CM_ BO_ 2566861119 "Oil Status Message";
CM_ SG_ 2566861119 StMsgCode "Status message code";
CM_ BO_ 2566861230 "Oil Status Message";
CM_ SG_ 2566861230 StMsgCode "Status message code";
CM_ BO_ 2566863330 "TFI4 Data CAN Frame";
CM_ BO_ 2566863533 "OBC Monitoring Information";
CM_ SG_ 2566863533 FanSt "FANStatus";
CM_ SG_ 2566863533 PdVlt "PDVoltage";
CM_ SG_ 2566863533 CpVlt "CPVoltage";
CM_ SG_ 2566863533 ObcAtmosphereTemp "OBCAtmosphereTemp.";
CM_ SG_ 2566863533 ObcMaxTemp "OBCMaximunTemp.";
CM_ SG_ 2566863533 PfcVlt "PFCVoltage";
CM_ SG_ 2566863533 AcInCur "ACInputCurrent";
CM_ SG_ 2566863533 AcInFrequency "ACInputFrequency";
CM_ SG_ 2566863533 AcInVlt "ACInputVoltage";
CM_ SG_ 2566863533 ChgElapsedTm "ChargingElapsedTime";
CM_ BO_ 2566864354 "TFI4 air mass flow sensor On Board Diagnostics receive frame";
CM_ BO_ 2566864627 "BMS Signal Group";
CM_ SG_ 2566864627 EstimatedChgTm "Estimatedchargingtime";
CM_ SG_ 2566864627 ChgSt "ChargingState";
CM_ SG_ 2566864627 HtPadSt "HeatingPadStatus";
CM_ SG_ 2566864627 BmsChgSType "BMSChargingSourceType";
CM_ BO_ 2566864680 "User Specific Used Hour Data Information";
CM_ SG_ 2566864680 FuelEfficiencybyUser "FuelEfficiencybyUser";
CM_ SG_ 2566864680 EcnMdFuelUsgbyUser "EconomyModeFuelUsagebyUser";
CM_ SG_ 2566864680 StdMdFuelUsgbyUser "StandardModeFuelUsagebyUser";
CM_ SG_ 2566864680 PwrMdFuelUsgbyUser "PowerModeFuelUsagebyUser";
CM_ SG_ 2566864680 PwrPlusMdFuelUsgbyUser "Power+ModeFuelUsagebyUser";
CM_ SG_ 2566864680 TotalFuelUsgbyUser "TotalFuelUsagebyUser";
CM_ SG_ 2566864680 EcnMdOprtgHrbyUser "EconomyModeOperatingHourbyUser";
CM_ SG_ 2566864680 StdMdOprtgHrbyUser "StandardModeOperatingHourbyUser";
CM_ SG_ 2566864680 PwrMdOprtgHrbyUser "PowerModeOperatingHourbyUser";
CM_ SG_ 2566864680 PwrPlusMdOprtgHrbyUser "Power+ModeOperatingHourbyUser";
CM_ SG_ 2566864680 IdleOprtgHrbyUser "IdleOperatingHourbyUser";
CM_ SG_ 2566864680 TotalOprtgHrbyUser "TotalOperatingHourbyUser";
CM_ SG_ 2566864680 UserName "UserName";
CM_ SG_ 2566864680 UserSeparatorFlag "UserSeparatorFlag";
CM_ SG_ 2566864680 UserSeparatorSlot "UserSeparatorSlot";
CM_ BO_ 2566864929 "Warning Symbol Group 1";
CM_ SG_ 2566864929 InvOh "WarningSymbol;InverterOverheatWarning";
CM_ SG_ 2566864929 MotOh "WarningSymbol;MotorOverheatWarning";
CM_ SG_ 2566864929 BatOh "WarningSymbol;BatteryOverheatWarning";
CM_ SG_ 2566864929 Bms "WarningSymbol;BMSWarning";
CM_ SG_ 2566864929 BatHt "WarningSymbol;BatteryHeater";
CM_ SG_ 2566864929 TrvlPdlFail "WarningSymbol;TravelPedalFailureWarning";
CM_ SG_ 2566864929 RrWhlAlgn "WarningSymbol;RearWheelAlignmentWarning";
CM_ SG_ 2566864929 PrkBrkPrs "WarningSymbol;ParkingBrakePressureWarning";
CM_ SG_ 2566864929 TrsmOilFiltClog "WarningSymbol;TransmissionOilFilterClogging";
CM_ SG_ 2566864929 FanMotPrsLw "WarningSymbol;LowFan-Motorpressure";
CM_ SG_ 2566864929 OvSpd "WarningSymbol;OverSpeed";
CM_ SG_ 2566864929 RBrkPdlNoCalb "WarningSymbol;Brakepedalnotcalibrated";
CM_ SG_ 2566864929 ElecStr "WarningSymbol;EletricSteeringWarning";
CM_ SG_ 2566864929 EgOvr "WarningSymbol;EngineOverrun";
CM_ SG_ 2566864929 EmgStr "WarningSymbol;EmergencySteering";
CM_ SG_ 2566864929 SeatBelt "WarningSymbol;SeatBelt";
CM_ SG_ 2566864929 TrsmOilOh "WarningSymbol;TransmissionOilOverheat";
CM_ SG_ 2566864929 Trsm "WarningSymbol;TransmissionWarning";
CM_ SG_ 2566864929 VboEpprVvOut "WarningSymbol;VBOError-EPPRV/VOutput";
CM_ SG_ 2566864929 VboJoySs "WarningSymbol;VBOError-JoystickSensor";
CM_ SG_ 2566864929 VboAngSs "WarningSymbol;VBOError-AngleSensor";
CM_ SG_ 2566864929 BatEq "WarningSymbol;BatteryEqualizer";
CM_ SG_ 2566864929 Uss "WarningSymbol;UltraSonicSensorWarning";
CM_ SG_ 2566864929 IceptSs "WarningSymbol;iCEPTSensorWarning";
CM_ SG_ 2566864929 Str "WarningSymbol;Steering";
CM_ SG_ 2566864929 BrkOilPrsLw "WarningSymbol;BrakeOilPressLow";
CM_ SG_ 2566864929 Ags "WarningSymbol;AGSWarning";
CM_ SG_ 2566864929 Owd "WarningSymbol;OWDWarning";
CM_ SG_ 2566864929 PilotFilt "WarningSymbol;PilotFilter";
CM_ SG_ 2566864929 RetFilt "WarningSymbol;ReturnFilter";
CM_ SG_ 2566864929 HydOilOh "WarningSymbol;Hyd.OilOverheat";
CM_ SG_ 2566864929 BatChg "WarningSymbol;BatteryCharge";
CM_ BO_ 2566865185 "Warning Symbol Group 2";
CM_ SG_ 2566865185 AcleOilOh "WarningSymbol;AxleOilOverheat";
CM_ SG_ 2566865185 AxleOilOvrHtFr "Warning Symbol; Axle Oil Overheat (for Front Axle)";
CM_ SG_ 2566865185 AxleOilOvrHtRr "Warning Symbol; Axle Oil Overheat (for Rear Axle)";
CM_ SG_ 2566865185 EgOilLv "Warning Symbol; Engine Oil Level";
CM_ SG_ 2566865185 ShtShftShutDown "Warning Symbol; Shuttle Shift Shut Down";
CM_ SG_ 2566865185 Acmt "Warning Symbol; Accumulator ";
CM_ SG_ 2566865185 TireTemp "WarningSymbol;TireTemperature";
CM_ SG_ 2566865185 FuelEmptyAddFuelTnk "WarningSymbol;FuelEmptyforAdditionalFuelTank";
CM_ SG_ 2566865185 ePowStp "WarningSymbol;ePowerSystemStop";
CM_ SG_ 2566865185 ePowChk "WarningSymbol;ePowerSystemCheck";
CM_ SG_ 2566865185 CoolLv "WarningSymbol;CoolantLevelWarning(RED)ReservedTank";
CM_ SG_ 2566865185 DefPrsLw "WarningSymbol;LowDEFpressure";
CM_ SG_ 2566865185 WifMainFiltFault "WarningSymbol;WaterInFuelWarning(MainFilterFaultUpon detection)";
CM_ SG_ 2566865185 WifMainFiltWaterDetectFault "WarningSymbol;WaterInFuelWarning(MainFilterWhen moisture is detected)";
CM_ SG_ 2566865185 WifPrePilotFault "WarningSymbol;WaterInFuelWarning(PreFilterFaultUpon detection)";
CM_ SG_ 2566865185 WifPrePilot "WarningSymbol;WaterInFuelWarning(PreFilterWhen moisture is detected)";
CM_ SG_ 2566865185 FuelEmpty "WarningSymbol;FuelEmpty";
CM_ SG_ 2566865185 AutoSCrcondPrkns "WarningSymbol;AutoSCRCONDITIONING(forPerkins)";
CM_ SG_ 2566865185 ExHhTempAmb "WarningSymbol;ExhaustSystemHighTemperature_Amber";
CM_ SG_ 2566865185 ExHhTempGr "WarningSymbol;ExhaustSystemHighTemperature_Green";
CM_ SG_ 2566865185 DpfActRgnInhbtSt "WarningSymbol;DPFActiveRegenerationInhibitedStatus";
CM_ SG_ 2566865185 DpfRgnClg "WarningSymbol;DPFRegenerationStatusLampCommand(DPFCloggingWarning)";
CM_ SG_ 2566865185 EgChkSrv "WarningSymbol;EngineCheckService";
CM_ SG_ 2566865185 EgChk2 "WarningSymbol;EngineCheck2";
CM_ SG_ 2566865185 EgChk1 "WarningSymbol;EngineCheck1";
CM_ SG_ 2566865185 EgStp "WarningSymbol;EngineStop";
CM_ SG_ 2566865185 EgWrn "WarningSymbol;EngineWarning";
CM_ SG_ 2566865185 AirCln "WarningSymbol;AirCleaner";
CM_ SG_ 2566865185 CoolLvSrgTnk "WarningSymbol;CoolantLevelWarning(RED)SurgeTank";
CM_ SG_ 2566865185 CoolTmpOv "WarningSymbol;CoolantTemp.Overheat";
CM_ SG_ 2566865185 EgOilPrs "WarningSymbol;EngineOilPressure";
CM_ BO_ 2566865441 "Warning Symbol Group 3";
CM_ SG_ 2566865441 RefPrs "Warning Symbol; Refrigerant Pressure";
CM_ SG_ 2566865441 TrmsSumpOilOvrHt "Warning Symbol; Transmission Sump Oil Overheat";
CM_ SG_ 2566865441 TrmsRtdOilOvrHt "Warning Symbol; Transmission Retarder Oil Overheat";
CM_ SG_ 2566865441 TirePrs "WarningSymbol;TirePressure";
CM_ SG_ 2566865441 HydOilWarmUp "Warningpop-up;HydraulicOilWarmUp";
CM_ SG_ 2566865441 GndSawRdy "WarningSymbol;GroundSawReady";
CM_ SG_ 2566865441 TrvMotTempOh "WarningSymbol;TravelMotorTemp.Overheat";
CM_ SG_ 2566865441 QckCouplerLck "WarningSymbol;QuickCouplerLock";
CM_ SG_ 2566865441 BrkPdlSs "WarningSymbol;BrakePedalSensor";
CM_ SG_ 2566865441 AtsRgnReq "WarningSymbol;ATSRegenerationRequest";
CM_ SG_ 2566865441 TmsConSt "WarningSymbol;TMSModuleConnectStatus";
CM_ SG_ 2566865441 QckCouplerUnlock "WarningSymbol;QuickCouplerUnlock";
CM_ SG_ 2566865441 RmvCntwt "WarningSymbol;RemovableCountweight";
CM_ SG_ 2566865441 FuelFilt "WarningSymbol;FuelFilter";
CM_ SG_ 2566865441 UreaQualScr "WarningSymbol;UreaQualityWarningLamp(SCRaftertreatment device)";
CM_ SG_ 2566865441 UreaLv "WarningSymbol;UreaLevelIndicator";
CM_ BO_ 2566865697 "State Information Group 1";
CM_ SG_ 2566865697 BzzCtrlCmd "BuzzerControlCommand";
CM_ SG_ 2566865697 CurGr "VehicleStateSymbol;CurrentGearStatus";
CM_ SG_ 2566865697 SelGr "VehicleStateSymbol;SelectedGearStatus";
CM_ SG_ 2566865697 BoomFltBiDir "VehicleStateSymbol;BoomFloat(Bi-Direction)";
CM_ SG_ 2566865697 Is3RdFNRElecStr "3rdFNR+Electric SteeringActivation";
CM_ SG_ 2566865697 IsFR "VehicleStateSymbol;F/RSelect";
CM_ SG_ 2566865697 IsElecStr "VehicleStateSymbol;ElectricSteeringSelect";
CM_ SG_ 2566865697 IsOprRdy "CEOpreratingReadyStaus";
CM_ SG_ 2566865697 PreHt "IndicatorSymbol;PreheatLamp";
CM_ SG_ 2566865697 FaultCntAvm "FaultCount(AVMFault)";
CM_ SG_ 2566865697 FaultCntMch "FaultCount(VehicleFault)";
CM_ SG_ 2566865697 CtrWrnLed "CentralWarningLEDCommand";
CM_ SG_ 2566865697 ExBzz "ExBuzzerCommand";
CM_ SG_ 2566865697 AutoShdnAval "AutoShutDownFunction Used or not";
CM_ SG_ 2566865697 AutoShdnSt "AutoShutDownState";
CM_ SG_ 2566865697 BrkrAct "BreakerActStatus";
CM_ SG_ 2566865697 ThwLvErr "Popup DisplayCommand;ThumbWheelLeverErrorPop-up";
CM_ SG_ 2566865697 AutoIdle "AutoidleStatusInformation";
CM_ SG_ 2566865697 RgnPrkns "Popup DisplayCommand;RegenerationPop-up(forPerkins)";
CM_ SG_ 2566865697 RpmCtrlRstrt "Popup DisplayCommand;RpmAdjustmentLimitPop-up";
CM_ SG_ 2566865697 IgnRstrtPilotCutOff "Popup DisplayCommand;Engine Start Limit Pop-up(PilotCutOffLeverStatus)";
CM_ SG_ 2566865697 IgnRstrtFRP "Popup DisplayCommand;Engine Start Limit Pop-up(F/RSwitchOrParkingSwitchStatus)";
CM_ SG_ 2566865697 OhPrv "Popup DisplayCommand;OverHeatPreventionPop-up";
CM_ SG_ 2566865697 HhMntLgc "IndicatorSymbol;High MountainLogicSymbol";
CM_ SG_ 2566865697 AutoShdn "IndicatorSymbol;AutoShutDown";
CM_ SG_ 2566865697 FuelHt "IndicatorSymbol;FuelHeater";
CM_ SG_ 2566865697 AutoWarmUpGr "IndicatorSymbol;AutoWarmup(Green)";
CM_ SG_ 2566865697 AutoWarmUpAmb "IndicatorSymbol;AutoWarmup(Amber)";
CM_ SG_ 2566865697 HhBeam "WheelTypeSymbol;HighBeam";
CM_ SG_ 2566865697 RamLck "WheelTypeSymbol;RAMLock";
CM_ SG_ 2566865697 PrkBrk "WheelTypeSymbol;ParkingBrake";
CM_ SG_ 2566865697 Trv "WheelTypeSymbol;Travel";
CM_ SG_ 2566865697 FNR "WheelTypeSymbol;F/N/R";
CM_ SG_ 2566865697 TrvMdWhl "TravelModeSymbolforWheel";
CM_ SG_ 2566865697 IsoBhl "VehicleStateSymbol;ISO/BHL";
CM_ SG_ 2566865697 TwOpt "TwoWayOptSettingStatus";
CM_ SG_ 2566865697 WrkMd "WorkModeSymbol";
CM_ SG_ 2566865697 TrvMdCrw "TravelModeSymbolforCrawler";
CM_ SG_ 2566865697 MrrHt "VehicleStateSymbol;MirrorHeater";
CM_ SG_ 2566865697 AuxMdSt "VehicleStateSymbol;AuxModeState";
CM_ SG_ 2566865697 RvsFanSt "VehicleStateSymbol;ReverseFanState";
CM_ SG_ 2566865697 SwPriSt "VehicleStateSymbol;SwingPriorityState";
CM_ SG_ 2566865697 BoomSwAct "VehicleStateSymbol;BoomSwingActiveStatus";
CM_ SG_ 2566865697 BoomFltSngDir "VehicleStateSymbol;BoomFloat(SingleDirection)";
CM_ SG_ 2566865697 PowMax "VehicleStateSymbol;PowerMax";
CM_ SG_ 2566865697 WrkLmp "VehicleStateSymbol;WorkLamp";
CM_ BO_ 2566866179 "ZFETC9";
CM_ BO_ 2566866209 "Gauge Data Group";
CM_ SG_ 2566866209 WeighingMeasureWgh "Gauge Data; Weighing Measure Weight";
CM_ SG_ 2566866209 TrmsOilTmp "Gauge Data; Transmission Oil Temperature";
CM_ SG_ 2566866209 VhcSpd "Gauge Data; Vehicle Speed";
CM_ SG_ 2566866209 UreaLv "Gauge Data; Urea Level";
CM_ SG_ 2566866209 FuelLv "Gauge Data; Fuel Level";
CM_ SG_ 2566866209 HydOilTmp "Gauge Data; Hyd Oil Temperature";
CM_ SG_ 2566866209 CoolTmp "Gauge Data; Coolant Temperature";
CM_ BO_ 2566866465 "Unclassified Periodic Data";
CM_ SG_ 2566866465 ArmAngInfo "Arm Angle Information";
CM_ SG_ 2566866465 McTprRlsSig "MC Temporary Release Signal";
CM_ SG_ 2566866465 SetSwgBenchSig "Setting Swing Bench Signal";
CM_ SG_ 2566866465 BckRefPtSig "Bucket Reference Point Signal";
CM_ SG_ 2566866465 GrdAstMdSet "Grade Assist Mode Set";
CM_ SG_ 2566866465 DsnDepthCtrlMinusSig "Design Depth Control Function(-) Signal";
CM_ SG_ 2566866465 DsnDepthCtrlPlusSig "Design Depth Control Function(+) Signal";
CM_ SG_ 2566866465 DoubleGrdntCtrlMinusSig "Double Gradient Control Function(-) Signal";
CM_ SG_ 2566866465 DoubleGrdntCtrlPlusSig "Double Gradient Control Function(+) Signal";
CM_ SG_ 2566866465 DsnLoadMinusSig "DesignData Load Function(-) Signal";
CM_ SG_ 2566866465 DsnLoadPlusSig "DesignData Load Function(+) Signal";
CM_ SG_ 2566866465 UserDrawSetMinusSig "User Drawing SettingFunction(-) Signal";
CM_ SG_ 2566866465 UserDrawSetPlusSig "User Drawing SettingFunction(+) Signal";
CM_ SG_ 2566866465 GrdntCtrlMinusSig "Gradient Control(-) Signal";
CM_ SG_ 2566866465 GrdntCtrlPlusSig "Gradient Control(+) Signal";
CM_ SG_ 2566866465 BckAstSig "Bucket Assist Signal";
CM_ SG_ 2566866465 SwgAstRSig "Swing Assist(Right) Signal";
CM_ SG_ 2566866465 SwgAstLSig "Swing Assist(Left)  Signal";
CM_ SG_ 2566866465 GrdAstPrecisionSelSig "Grade Assist Precision Select Signal";
CM_ SG_ 2566866465 GrdAstSig "Grade Assist Signal";
CM_ SG_ 2566866465 TruckCancelSig "Truck Cancel Signal";
CM_ SG_ 2566866465 TruckStoreSig "Truck Store Signal";
CM_ SG_ 2566866465 BckRecallSig "Bucket Recall Signal";
CM_ SG_ 2566866465 BckCancelSig "Bucket Cancel Signal";
CM_ SG_ 2566866465 ReweighSig "Reweigh Signal";
CM_ SG_ 2566866465 WeighingSig "Weighing Signal";
CM_ SG_ 2566866465 ReferencePtRlsSig "Reference Point Release Signal";
CM_ SG_ 2566866465 LaserandTouchpointSig "Laser and Touch point Signal";
CM_ SG_ 2566866465 BmSig "Benchmark Signal";
CM_ SG_ 2566866465 CamSig "Camera Signal";
CM_ SG_ 2566866465 AdoMuteSig "Audio Mute Signal";
CM_ SG_ 2566866465 MultifuncJoyBtnSig "Multifunction Joystick Button Signal";
BA_DEF_  "DBName" STRING ;
BA_DEF_ BO_  "Channel" STRING ;
BA_DEF_ BO_  "VssMsg" STRING ;
BA_DEF_ SG_  "VssSig" STRING ;
BA_DEF_ BO_  "GenMsgCycleTime" INT 0 65535;
BA_DEF_ SG_  "SystemSignalLongSymbol" STRING ;
BA_DEF_DEF_  "DBName" "";
BA_DEF_DEF_  "Channel" "";
BA_DEF_DEF_  "VssMsg" "";
BA_DEF_DEF_  "VssSig" "";
BA_DEF_DEF_  "GenMsgCycleTime" 0;
BA_DEF_DEF_  "SystemSignalLongSymbol" "";
BA_ "DBName" "ModelW";
BA_ "GenMsgCycleTime" BO_ 2348810243 10;
BA_ "VssMsg" BO_ 2348810243 "Mch.TCU.TSC1";
BA_ "Channel" BO_ 2348810243 "can1";
BA_ "GenMsgCycleTime" BO_ 2348810251 10;
BA_ "VssMsg" BO_ 2348810251 "Mch.BRK.TSC1";
BA_ "Channel" BO_ 2348810251 "can1";
BA_ "GenMsgCycleTime" BO_ 2348810259 10;
BA_ "VssMsg" BO_ 2348810259 "Mch.ESP.TSC1";
BA_ "Channel" BO_ 2348810259 "can1";
BA_ "GenMsgCycleTime" BO_ 2348810273 10;
BA_ "VssMsg" BO_ 2348810273 "Mch.MCU.TSC1";
BA_ "Channel" BO_ 2348810273 "can1";
BA_ "GenMsgCycleTime" BO_ 2348814083 50;
BA_ "VssMsg" BO_ 2348814083 "Mch.TCU.TSC1RDE";
BA_ "Channel" BO_ 2348814083 "can1";
BA_ "GenMsgCycleTime" BO_ 2348814091 50;
BA_ "VssMsg" BO_ 2348814091 "Mch.BRK.TSC1RDE";
BA_ "Channel" BO_ 2348814091 "can1";
BA_ "GenMsgCycleTime" BO_ 2348814096 50;
BA_ "VssMsg" BO_ 2348814096 "Mch.RDD.TSC1RDE";
BA_ "Channel" BO_ 2348814096 "can1";
BA_ "GenMsgCycleTime" BO_ 2348814099 50;
BA_ "VssMsg" BO_ 2348814099 "Mch.ESP.TSC1RDE";
BA_ "Channel" BO_ 2348814099 "can1";
BA_ "GenMsgCycleTime" BO_ 2348814113 50;
BA_ "VssMsg" BO_ 2348814113 "Mch.MCU.TSC1RDE";
BA_ "Channel" BO_ 2348814113 "can1";
BA_ "GenMsgCycleTime" BO_ 2350579745 20;
BA_ "VssMsg" BO_ 2350579745 "Mch.MCU.HVESSC1";
BA_ "Channel" BO_ 2350579745 "can1";
BA_ "GenMsgCycleTime" BO_ 2351300641 10;
BA_ "VssMsg" BO_ 2351300641 "Mch.MCU.MG1IC";
BA_ "Channel" BO_ 2351300641 "can1";
BA_ "GenMsgCycleTime" BO_ 2564816912 1000;
BA_ "VssMsg" BO_ 2564816912 "Mch.RDD.CM1";
BA_ "Channel" BO_ 2564816912 "can1";
BA_ "GenMsgCycleTime" BO_ 2564816929 1000;
BA_ "VssMsg" BO_ 2564816929 "Mch.MCU.CM1";
BA_ "Channel" BO_ 2564816929 "can1";
BA_ "GenMsgCycleTime" BO_ 2565800744 50;
BA_ "VssMsg" BO_ 2565800744 "Mch.GP.GPSMTCU";
BA_ "Channel" BO_ 2565800744 "can1";
BA_ "GenMsgCycleTime" BO_ 2364478241 500;
BA_ "VssMsg" BO_ 2364478241 "Mch.MCU.MMIPR";
BA_ "Channel" BO_ 2364478241 "can1";
BA_ "VssMsg" BO_ 2565805864 "Mch.GP.GPSMCLT";
BA_ "Channel" BO_ 2565805864 "can1";
BA_ "VssMsg" BO_ 2565808424 "Mch.GP.GPSMVCU";
BA_ "Channel" BO_ 2565808424 "can1";
BA_ "VssMsg" BO_ 2565808458 "Mch.TMS.REQMCU";
BA_ "Channel" BO_ 2565808458 "can1";
BA_ "GenMsgCycleTime" BO_ 2565810241 1000;
BA_ "VssMsg" BO_ 2565810241 "Mch.GW.REQGP";
BA_ "Channel" BO_ 2565810241 "can1";
BA_ "VssMsg" BO_ 2565810250 "Mch.TMS.REQGP";
BA_ "Channel" BO_ 2565810250 "can1";
BA_ "VssMsg" BO_ 2565810256 "Mch.KPD1.REQGP";
BA_ "Channel" BO_ 2565810256 "can1";
BA_ "VssMsg" BO_ 2565816616 "Mch.GP.GPSMGW";
BA_ "Channel" BO_ 2565816616 "can1";
BA_ "VssMsg" BO_ 2565818920 "Mch.GP.GPSMTMS";
BA_ "Channel" BO_ 2565818920 "can1";
BA_ "VssMsg" BO_ 2565820456 "Mch.GP.GPSMKPD";
BA_ "Channel" BO_ 2565820456 "can1";
BA_ "VssMsg" BO_ 2565821480 "Mch.GP.GPSMAVM";
BA_ "Channel" BO_ 2565821480 "can1";
BA_ "VssMsg" BO_ 2565821505 "Mch.GW.REQEXMON";
BA_ "Channel" BO_ 2565821505 "can1";
BA_ "GenMsgCycleTime" BO_ 2364496417 500;
BA_ "VssMsg" BO_ 2364496417 "Mch.MCU.MMISC";
BA_ "Channel" BO_ 2364496417 "can1";
BA_ "GenMsgCycleTime" BO_ 2565865487 100;
BA_ "VssMsg" BO_ 2565865487 "Mch.RDE.ERC1";
BA_ "Channel" BO_ 2565865487 "can1";
BA_ "GenMsgCycleTime" BO_ 2565865488 100;
BA_ "VssMsg" BO_ 2565865488 "Mch.RDD.ERC1";
BA_ "Channel" BO_ 2565865488 "can1";
BA_ "GenMsgCycleTime" BO_ 2565865733 50;
BA_ "VssMsg" BO_ 2565865733 "Mch.FNR.EBC1";
BA_ "Channel" BO_ 2565865733 "can1";
BA_ "GenMsgCycleTime" BO_ 2565865739 100;
BA_ "VssMsg" BO_ 2565865739 "Mch.BRK.EBC1";
BA_ "Channel" BO_ 2565865739 "can1";
BA_ "GenMsgCycleTime" BO_ 2364539395 10;
BA_ "VssMsg" BO_ 2364539395 "Mch.TCU.ETC1";
BA_ "Channel" BO_ 2364539395 "can1";
BA_ "GenMsgCycleTime" BO_ 2364539648 50;
BA_ "VssMsg" BO_ 2364539648 "Mch.ECU.EEC2";
BA_ "Channel" BO_ 2364539648 "can1";
BA_ "GenMsgCycleTime" BO_ 2364539904 10;
BA_ "VssMsg" BO_ 2364539904 "Mch.ECU.EEC1";
BA_ "Channel" BO_ 2364539904 "can1";
BA_ "GenMsgCycleTime" BO_ 2565866755 100;
BA_ "VssMsg" BO_ 2565866755 "Mch.TCU.ETC2";
BA_ "Channel" BO_ 2565866755 "can1";
BA_ "GenMsgCycleTime" BO_ 2565867011 500;
BA_ "VssMsg" BO_ 2565867011 "Mch.TCU.EAC1";
BA_ "Channel" BO_ 2565867011 "can1";
BA_ "GenMsgCycleTime" BO_ 2364542241 100;
BA_ "VssMsg" BO_ 2364542241 "Mch.MCU.LOI";
BA_ "Channel" BO_ 2364542241 "can1";
BA_ "GenMsgCycleTime" BO_ 2565869137 50;
BA_ "VssMsg" BO_ 2565869137 "Mch.KPD2.AT1IG1";
BA_ "Channel" BO_ 2565869137 "can1";
BA_ "GenMsgCycleTime" BO_ 2565869394 50;
BA_ "VssMsg" BO_ 2565869394 "Mch.ATSGO.AT1OG1";
BA_ "Channel" BO_ 2565869394 "can1";
BA_ "GenMsgCycleTime" BO_ 2565875998 10;
BA_ "VssMsg" BO_ 2565875998 "Mch.ACU.SSI2";
BA_ "Channel" BO_ 2565875998 "can2";
BA_ "GenMsgCycleTime" BO_ 2565876161 10;
BA_ "VssMsg" BO_ 2565876161 "Mch.IMU1.SSI2";
BA_ "Channel" BO_ 2565876161 "can1";
BA_ "GenMsgCycleTime" BO_ 2565876162 10;
BA_ "VssMsg" BO_ 2565876162 "Mch.IMU2.SSI2";
BA_ "Channel" BO_ 2565876162 "can1";
BA_ "GenMsgCycleTime" BO_ 2565876163 10;
BA_ "VssMsg" BO_ 2565876163 "Mch.IMU3.SSI2";
BA_ "Channel" BO_ 2565876163 "can1";
BA_ "GenMsgCycleTime" BO_ 2565876164 10;
BA_ "VssMsg" BO_ 2565876164 "Mch.IMU4.SSI2";
BA_ "Channel" BO_ 2565876164 "can1";
BA_ "GenMsgCycleTime" BO_ 2565876165 10;
BA_ "VssMsg" BO_ 2565876165 "Mch.IMU5.SSI2";
BA_ "Channel" BO_ 2565876165 "can1";
BA_ "GenMsgCycleTime" BO_ 2364575987 20;
BA_ "VssMsg" BO_ 2364575987 "Mch.AGW.HVESSD1";
BA_ "Channel" BO_ 2364575987 "can1";
BA_ "GenMsgCycleTime" BO_ 2364576243 20;
BA_ "VssMsg" BO_ 2364576243 "Mch.AGW.HVESSD2";
BA_ "Channel" BO_ 2364576243 "can1";
BA_ "GenMsgCycleTime" BO_ 2364576755 100;
BA_ "VssMsg" BO_ 2364576755 "Mch.AGW.HVESSD4";
BA_ "Channel" BO_ 2364576755 "can1";
BA_ "GenMsgCycleTime" BO_ 2364577011 20;
BA_ "VssMsg" BO_ 2364577011 "Mch.AGW.HVESSD5";
BA_ "Channel" BO_ 2364577011 "can1";
BA_ "GenMsgCycleTime" BO_ 2364577267 100;
BA_ "VssMsg" BO_ 2364577267 "Mch.AGW.HVESSD6";
BA_ "Channel" BO_ 2364577267 "can1";
BA_ "GenMsgCycleTime" BO_ 2364637584 100;
BA_ "VssMsg" BO_ 2364637584 "Mch.PMI.MG1IMF1";
BA_ "Channel" BO_ 2364637584 "can1";
BA_ "VssMsg" BO_ 2364641057 "Mch.MCU.IPGA";
BA_ "Channel" BO_ 2364641057 "can1";
BA_ "VssMsg" BO_ 2364641267 "Mch.AGW.IPGA";
BA_ "Channel" BO_ 2364641267 "can1";
BA_ "GenMsgCycleTime" BO_ 2365288848 1000;
BA_ "VssMsg" BO_ 2365288848 "Mch.PMI.MG1IMT";
BA_ "Channel" BO_ 2365288848 "can1";
BA_ "GenMsgCycleTime" BO_ 2365289104 1000;
BA_ "VssMsg" BO_ 2365289104 "Mch.PMI.MG1IT";
BA_ "Channel" BO_ 2365289104 "can1";
BA_ "GenMsgCycleTime" BO_ 2365289360 1000;
BA_ "VssMsg" BO_ 2365289360 "Mch.PMI.MG1IR2";
BA_ "Channel" BO_ 2365289360 "can1";
BA_ "GenMsgCycleTime" BO_ 2365289616 10;
BA_ "VssMsg" BO_ 2365289616 "Mch.PMI.MG1IS1";
BA_ "Channel" BO_ 2365289616 "can1";
BA_ "VssMsg" BO_ 2566675955 "Mch.AGW.HVESSCFG";
BA_ "Channel" BO_ 2566675955 "can1";
BA_ "VssMsg" BO_ 2633785075 "Mch.AGW.HVESSHIST";
BA_ "Channel" BO_ 2633785075 "can1";
BA_ "GenMsgCycleTime" BO_ 2566709248 10;
BA_ "VssMsg" BO_ 2566709248 "Mch.ECU.DPFC2";
BA_ "Channel" BO_ 2566709248 "can1";
BA_ "GenMsgCycleTime" BO_ 2633828415 30000;
BA_ "VssMsg" BO_ 2633828415 "Mch.HDOQS.OQM1";
BA_ "Channel" BO_ 2633828415 "can1";
BA_ "GenMsgCycleTime" BO_ 2633828526 30000;
BA_ "VssMsg" BO_ 2633828526 "Mch.EGOQS.OQM1";
BA_ "Channel" BO_ 2633828526 "can1";
BA_ "GenMsgCycleTime" BO_ 2566719744 1000;
BA_ "VssMsg" BO_ 2566719744 "Mch.ECU.HRLFC";
BA_ "Channel" BO_ 2566719744 "can1";
BA_ "VssMsg" BO_ 2365394514 "Mch.ATSGO.AT1OGC2";
BA_ "Channel" BO_ 2365394514 "can1";
BA_ "VssMsg" BO_ 2365394770 "Mch.ATSGO.AT1OGC1";
BA_ "Channel" BO_ 2365394770 "can1";
BA_ "VssMsg" BO_ 2365395025 "Mch.KPD2.AT1IGC2";
BA_ "Channel" BO_ 2365395025 "can1";
BA_ "VssMsg" BO_ 2365395281 "Mch.KPD2.AT1IGC1";
BA_ "Channel" BO_ 2365395281 "can1";
BA_ "GenMsgCycleTime" BO_ 2566722989 1000;
BA_ "VssMsg" BO_ 2566722989 "Mch.OBC.BCH1";
BA_ "Channel" BO_ 2566722989 "can1";
BA_ "GenMsgCycleTime" BO_ 2566725632 500;
BA_ "VssMsg" BO_ 2566725632 "Mch.ECU.A1DOC1";
BA_ "Channel" BO_ 2566725632 "can1";
BA_ "VssMsg" BO_ 2566748928 "Mch.ECU.AT1S";
BA_ "Channel" BO_ 2566748928 "can1";
BA_ "GenMsgCycleTime" BO_ 2566749184 1000;
BA_ "VssMsg" BO_ 2566749184 "Mch.ECU.DPFC1";
BA_ "Channel" BO_ 2566749184 "can1";
BA_ "GenMsgCycleTime" BO_ 2566755587 1000;
BA_ "VssMsg" BO_ 2566755587 "Mch.TCU.TRF2";
BA_ "Channel" BO_ 2566755587 "can1";
BA_ "GenMsgCycleTime" BO_ 2566757120 1000;
BA_ "VssMsg" BO_ 2566757120 "Mch.ECU.A1DEFI1";
BA_ "Channel" BO_ 2566757120 "can1";
BA_ "GenMsgCycleTime" BO_ 2566758656 500;
BA_ "VssMsg" BO_ 2566758656 "Mch.ECU.AT1FC1";
BA_ "Channel" BO_ 2566758656 "can1";
BA_ "GenMsgCycleTime" BO_ 2566763008 100;
BA_ "VssMsg" BO_ 2566763008 "Mch.ECU.AT1IMG";
BA_ "Channel" BO_ 2566763008 "can1";
BA_ "GenMsgCycleTime" BO_ 2566763264 500;
BA_ "VssMsg" BO_ 2566763264 "Mch.ECU.AT1OG2";
BA_ "Channel" BO_ 2566763264 "can1";
BA_ "GenMsgCycleTime" BO_ 2566763325 500;
BA_ "VssMsg" BO_ 2566763325 "Mch.EEC.AT1OG2";
BA_ "Channel" BO_ 2566763325 "can1";
BA_ "GenMsgCycleTime" BO_ 2566763520 500;
BA_ "VssMsg" BO_ 2566763520 "Mch.ECU.AT1IG2";
BA_ "Channel" BO_ 2566763520 "can1";
BA_ "GenMsgCycleTime" BO_ 2566763581 500;
BA_ "VssMsg" BO_ 2566763581 "Mch.EEC.AT1IG2";
BA_ "Channel" BO_ 2566763581 "can1";
BA_ "VssMsg" BO_ 2365441523 "Mch.AGW.ECUID";
BA_ "Channel" BO_ 2365441523 "can1";
BA_ "GenMsgCycleTime" BO_ 2566769997 200;
BA_ "VssMsg" BO_ 2566769997 "Mch.CBSW.OWW";
BA_ "Channel" BO_ 2566769997 "can2";
BA_ "VssMsg" BO_ 2566771968 "Mch.ECU.EEC5";
BA_ "Channel" BO_ 2566771968 "can1";
BA_ "VssMsg" BO_ 2365445841 "Mch.EJRH.BJM1";
BA_ "Channel" BO_ 2365445841 "can2";
BA_ "VssMsg" BO_ 2365446097 "Mch.EJRH.EJM1";
BA_ "Channel" BO_ 2365446097 "can2";
BA_ "VssMsg" BO_ 2365446352 "Mch.EJLH.BJM2";
BA_ "Channel" BO_ 2365446352 "can1";
BA_ "VssMsg" BO_ 2365446608 "Mch.EJLH.EJM2";
BA_ "Channel" BO_ 2365446608 "can1";
BA_ "VssMsg" BO_ 2365446893 "Mch.EPDLT.BJM3";
BA_ "Channel" BO_ 2365446893 "can2";
BA_ "VssMsg" BO_ 2365446894 "Mch.EPDL2.BJM3";
BA_ "Channel" BO_ 2365446894 "can2";
BA_ "VssMsg" BO_ 2365446895 "Mch.EPDLR.BJM3";
BA_ "Channel" BO_ 2365446895 "can1";
BA_ "VssMsg" BO_ 2365446896 "Mch.EPDLA.BJM3";
BA_ "Channel" BO_ 2365446896 "can1";
BA_ "GenMsgCycleTime" BO_ 2365468962 20;
BA_ "VssMsg" BO_ 2365468962 "Mch.TRBDZ.AV01C";
BA_ "Channel" BO_ 2365468962 "can1";
BA_ "GenMsgCycleTime" BO_ 2365469218 20;
BA_ "VssMsg" BO_ 2365469218 "Mch.TRBDZ.AV02C";
BA_ "Channel" BO_ 2365469218 "can1";
BA_ "VssMsg" BO_ 2365473101 "Mch.CBSW.LCMD";
BA_ "Channel" BO_ 2365473101 "can2";
BA_ "GenMsgCycleTime" BO_ 2566801441 100;
BA_ "VssMsg" BO_ 2566801441 "Mch.MCU.WBSD";
BA_ "Channel" BO_ 2566801441 "can1";
BA_ "GenMsgCycleTime" BO_ 2566801923 100;
BA_ "VssMsg" BO_ 2566801923 "Mch.TCU.ETC7";
BA_ "Channel" BO_ 2566801923 "can1";
BA_ "GenMsgCycleTime" BO_ 2566802176 1000;
BA_ "VssMsg" BO_ 2566802176 "Mch.ECU.TCFG2";
BA_ "Channel" BO_ 2566802176 "can1";
BA_ "GenMsgCycleTime" BO_ 2566803211 100;
BA_ "VssMsg" BO_ 2566803211 "Mch.BRK.VDC1";
BA_ "Channel" BO_ 2566803211 "can1";
BA_ "GenMsgCycleTime" BO_ 2566804992 1000;
BA_ "VssMsg" BO_ 2566804992 "Mch.ECU.AT1T1I1";
BA_ "Channel" BO_ 2566804992 "can1";
BA_ "GenMsgCycleTime" BO_ 2566804993 1000;
BA_ "VssMsg" BO_ 2566804993 "Mch.ECU1.AT1T1I1";
BA_ "Channel" BO_ 2566804993 "can1";
BA_ "GenMsgCycleTime" BO_ 2365484270 50;
BA_ "VssMsg" BO_ 2365484270 "Mch.EPDL2.TCO1";
BA_ "Channel" BO_ 2365484270 "can1";
BA_ "GenMsgCycleTime" BO_ 2566811147 20;
BA_ "VssMsg" BO_ 2566811147 "Mch.BRK.HRWS";
BA_ "Channel" BO_ 2566811147 "can1";
BA_ "GenMsgCycleTime" BO_ 2633927682 100;
BA_ "VssMsg" BO_ 2633927682 "Mch.ECU.AAI2EDC";
BA_ "Channel" BO_ 2633927682 "can1";
BA_ "GenMsgCycleTime" BO_ 2566831360 1000;
BA_ "VssMsg" BO_ 2566831360 "Mch.ECU.FD1";
BA_ "Channel" BO_ 2566831360 "can1";
BA_ "VssMsg" BO_ 2566831616 "Mch.ECU.EEC4";
BA_ "Channel" BO_ 2566831616 "can1";
BA_ "GenMsgCycleTime" BO_ 2566831883 100;
BA_ "VssMsg" BO_ 2566831883 "Mch.BRK.EBC2";
BA_ "Channel" BO_ 2566831883 "can1";
BA_ "GenMsgCycleTime" BO_ 2566832622 1000;
BA_ "VssMsg" BO_ 2566832622 "Mch.EPDL2.VDHR";
BA_ "Channel" BO_ 2566832622 "can1";
BA_ "VssMsg" BO_ 2566834688 "Mch.ECU.DM1";
BA_ "Channel" BO_ 2566834688 "can1";
BA_ "GenMsgCycleTime" BO_ 2566834749 10;
BA_ "VssMsg" BO_ 2566834749 "Mch.EEC.DM1";
BA_ "Channel" BO_ 2566834749 "can1";
BA_ "VssMsg" BO_ 2566834944 "Mch.ECU.DM2";
BA_ "Channel" BO_ 2566834944 "can1";
BA_ "VssMsg" BO_ 2566835456 "Mch.ECU.DM4";
BA_ "Channel" BO_ 2566835456 "can1";
BA_ "VssMsg" BO_ 2566835712 "Mch.ECU.DM5";
BA_ "Channel" BO_ 2566835712 "can1";
BA_ "VssMsg" BO_ 2566835968 "Mch.ECU.DM6";
BA_ "Channel" BO_ 2566835968 "can1";
BA_ "GenMsgCycleTime" BO_ 2566838528 100;
BA_ "VssMsg" BO_ 2566838528 "Mch.ECU.AUXIO1";
BA_ "Channel" BO_ 2566838528 "can1";
BA_ "VssMsg" BO_ 2566839296 "Mch.ECU.IDLOP";
BA_ "Channel" BO_ 2566839296 "can1";
BA_ "GenMsgCycleTime" BO_ 2566840064 50;
BA_ "VssMsg" BO_ 2566840064 "Mch.ECU.EEC3";
BA_ "Channel" BO_ 2566840064 "can1";
BA_ "GenMsgCycleTime" BO_ 2566841344 1000;
BA_ "VssMsg" BO_ 2566841344 "Mch.ECU.SHUTDWN";
BA_ "Channel" BO_ 2566841344 "can1";
BA_ "VssMsg" BO_ 2566841600 "Mch.ECU.HOURS";
BA_ "Channel" BO_ 2566841600 "can1";
BA_ "GenMsgCycleTime" BO_ 2566841879 1000;
BA_ "VssMsg" BO_ 2566841879 "Mch.CLST.TD";
BA_ "Channel" BO_ 2566841879 "can1";
BA_ "GenMsgCycleTime" BO_ 2566842094 1000;
BA_ "VssMsg" BO_ 2566842094 "Mch.EPDL2.TD";
BA_ "Channel" BO_ 2566842094 "can1";
BA_ "VssMsg" BO_ 2566842112 "Mch.ECU.VH";
BA_ "Channel" BO_ 2566842112 "can1";
BA_ "VssMsg" BO_ 2566842624 "Mch.ECU.LFC1";
BA_ "Channel" BO_ 2566842624 "can1";
BA_ "VssMsg" BO_ 2566843136 "Mch.ECU.CI";
BA_ "Channel" BO_ 2566843136 "can1";
BA_ "VssMsg" BO_ 2566843392 "Mch.ECU.VI";
BA_ "Channel" BO_ 2566843392 "can1";
BA_ "VssMsg" BO_ 2566843648 "Mch.ECU.CCSS";
BA_ "Channel" BO_ 2566843648 "can1";
BA_ "GenMsgCycleTime" BO_ 2566843651 100;
BA_ "VssMsg" BO_ 2566843651 "Mch.TCU.CCSS";
BA_ "Channel" BO_ 2566843651 "can1";
BA_ "GenMsgCycleTime" BO_ 2566843653 100;
BA_ "VssMsg" BO_ 2566843653 "Mch.FNR.CCSS";
BA_ "Channel" BO_ 2566843653 "can1";
BA_ "GenMsgCycleTime" BO_ 2566843904 1000;
BA_ "VssMsg" BO_ 2566843904 "Mch.ECU.ET1";
BA_ "Channel" BO_ 2566843904 "can1";
BA_ "GenMsgCycleTime" BO_ 2566843967 30000;
BA_ "VssMsg" BO_ 2566843967 "Mch.HDOQS.OT";
BA_ "Channel" BO_ 2566843967 "can1";
BA_ "GenMsgCycleTime" BO_ 2566844078 30000;
BA_ "VssMsg" BO_ 2566844078 "Mch.EGOQS.OT";
BA_ "Channel" BO_ 2566844078 "can1";
BA_ "GenMsgCycleTime" BO_ 2566844160 500;
BA_ "VssMsg" BO_ 2566844160 "Mch.ECU.EFLP1";
BA_ "Channel" BO_ 2566844160 "can1";
BA_ "GenMsgCycleTime" BO_ 2566844672 100;
BA_ "VssMsg" BO_ 2566844672 "Mch.ECU.CCVS";
BA_ "Channel" BO_ 2566844672 "can1";
BA_ "GenMsgCycleTime" BO_ 2566844675 100;
BA_ "VssMsg" BO_ 2566844675 "Mch.TCU.CCVS";
BA_ "Channel" BO_ 2566844675 "can1";
BA_ "GenMsgCycleTime" BO_ 2566844705 100;
BA_ "VssMsg" BO_ 2566844705 "Mch.MCU.CCVS";
BA_ "Channel" BO_ 2566844705 "can1";
BA_ "GenMsgCycleTime" BO_ 2566844928 100;
BA_ "VssMsg" BO_ 2566844928 "Mch.ECU.LFE1";
BA_ "Channel" BO_ 2566844928 "can1";
BA_ "GenMsgCycleTime" BO_ 2566845696 1000;
BA_ "VssMsg" BO_ 2566845696 "Mch.ECU.AMB";
BA_ "Channel" BO_ 2566845696 "can1";
BA_ "GenMsgCycleTime" BO_ 2566845952 500;
BA_ "VssMsg" BO_ 2566845952 "Mch.ECU.IC1";
BA_ "Channel" BO_ 2566845952 "can1";
BA_ "GenMsgCycleTime" BO_ 2566846208 1000;
BA_ "VssMsg" BO_ 2566846208 "Mch.ECU.VEP1";
BA_ "Channel" BO_ 2566846208 "can1";
BA_ "GenMsgCycleTime" BO_ 2566846467 1000;
BA_ "VssMsg" BO_ 2566846467 "Mch.TCU.TF";
BA_ "Channel" BO_ 2566846467 "can1";
BA_ "GenMsgCycleTime" BO_ 2566846981 1000;
BA_ "VssMsg" BO_ 2566846981 "Mch.FNR.B1";
BA_ "Channel" BO_ 2566846981 "can1";
BA_ "GenMsgCycleTime" BO_ 2566847235 1000;
BA_ "VssMsg" BO_ 2566847235 "Mch.TCU.RF";
BA_ "Channel" BO_ 2566847235 "can1";
BA_ "GenMsgCycleTime" BO_ 2566847511 1000;
BA_ "VssMsg" BO_ 2566847511 "Mch.CLST.DD1";
BA_ "Channel" BO_ 2566847511 "can1";
BA_ "GenMsgCycleTime" BO_ 2566847521 1000;
BA_ "VssMsg" BO_ 2566847521 "Mch.MCU.DD1";
BA_ "Channel" BO_ 2566847521 "can1";
BA_ "GenMsgCycleTime" BO_ 2566848256 10000;
BA_ "VssMsg" BO_ 2566848256 "Mch.ECU.WFI";
BA_ "Channel" BO_ 2566848256 "can1";
BA_ "GenMsgCycleTime" BO_ 2566849085 100;
BA_ "VssMsg" BO_ 2566849085 "Mch.EEC.TXEGSPM";
BA_ "Channel" BO_ 2566849085 "can1";
BA_ "GenMsgCycleTime" BO_ 2566851074 100;
BA_ "VssMsg" BO_ 2566851074 "Mch.ECU.ACTVCODERx";
BA_ "Channel" BO_ 2566851074 "can1";
BA_ "GenMsgCycleTime" BO_ 2566852897 10;
BA_ "VssMsg" BO_ 2566852897 "Mch.MCU.SMVCU";
BA_ "Channel" BO_ 2566852897 "can1";
BA_ "GenMsgCycleTime" BO_ 2365527585 50;
BA_ "VssMsg" BO_ 2365527585 "Mch.MCU.ASDJPR";
BA_ "Channel" BO_ 2365527585 "can2";
BA_ "GenMsgCycleTime" BO_ 2365527841 50;
BA_ "VssMsg" BO_ 2365527841 "Mch.MCU.ASDJRD";
BA_ "Channel" BO_ 2365527841 "can2";
BA_ "GenMsgCycleTime" BO_ 2365528097 100;
BA_ "VssMsg" BO_ 2365528097 "Mch.MCU.VSPR";
BA_ "Channel" BO_ 2365528097 "can2";
BA_ "GenMsgCycleTime" BO_ 2365528353 100;
BA_ "VssMsg" BO_ 2365528353 "Mch.MCU.VSRD";
BA_ "Channel" BO_ 2365528353 "can1";
BA_ "GenMsgCycleTime" BO_ 2566856451 100;
BA_ "VssMsg" BO_ 2566856451 "Mch.TCU.TCU2";
BA_ "Channel" BO_ 2566856451 "can1";
BA_ "GenMsgCycleTime" BO_ 2566856707 100;
BA_ "VssMsg" BO_ 2566856707 "Mch.TCU.TCU3";
BA_ "Channel" BO_ 2566856707 "can1";
BA_ "VssMsg" BO_ 2365530117 "Mch.FNR.SLP1";
BA_ "Channel" BO_ 2365530117 "can1";
BA_ "GenMsgCycleTime" BO_ 2566856960 100;
BA_ "VssMsg" BO_ 2566856960 "Mch.ECU.EDC2BC";
BA_ "Channel" BO_ 2566856960 "can1";
BA_ "VssMsg" BO_ 2365530373 "Mch.FNR.SLP2";
BA_ "Channel" BO_ 2365530373 "can1";
BA_ "GenMsgCycleTime" BO_ 2566857219 100;
BA_ "VssMsg" BO_ 2566857219 "Mch.TCU.TCU4";
BA_ "Channel" BO_ 2566857219 "can1";
BA_ "GenMsgCycleTime" BO_ 2566857731 100;
BA_ "VssMsg" BO_ 2566857731 "Mch.TCU.ZFCC";
BA_ "Channel" BO_ 2566857731 "can1";
BA_ "VssMsg" BO_ 2566857984 "Mch.ECU.ENGCOND";
BA_ "Channel" BO_ 2566857984 "can1";
BA_ "GenMsgCycleTime" BO_ 2566858752 50;
BA_ "VssMsg" BO_ 2566858752 "Mch.ECU.FanCtl";
BA_ "Channel" BO_ 2566858752 "can1";
BA_ "GenMsgCycleTime" BO_ 2566859297 100;
BA_ "VssMsg" BO_ 2566859297 "Mch.MCU.VEHICLE2";
BA_ "Channel" BO_ 2566859297 "can1";
BA_ "GenMsgCycleTime" BO_ 2566859523 100;
BA_ "VssMsg" BO_ 2566859523 "Mch.TCU.TCU1";
BA_ "Channel" BO_ 2566859523 "can1";
BA_ "GenMsgCycleTime" BO_ 2566860833 100;
BA_ "VssMsg" BO_ 2566860833 "Mch.MCU.VCUHVCI";
BA_ "Channel" BO_ 2566860833 "can1";
BA_ "VssMsg" BO_ 2566861056 "Mch.ECU.TFI4CMD";
BA_ "Channel" BO_ 2566861056 "can1";
BA_ "GenMsgCycleTime" BO_ 2566861119 30000;
BA_ "VssMsg" BO_ 2566861119 "Mch.HDOQS.OSM";
BA_ "Channel" BO_ 2566861119 "can1";
BA_ "GenMsgCycleTime" BO_ 2566861230 30000;
BA_ "VssMsg" BO_ 2566861230 "Mch.EGOQS.OSM";
BA_ "Channel" BO_ 2566861230 "can1";
BA_ "GenMsgCycleTime" BO_ 2566863330 10;
BA_ "VssMsg" BO_ 2566863330 "Mch.LC510.TFI4Data";
BA_ "Channel" BO_ 2566863330 "can1";
BA_ "VssMsg" BO_ 2566863533 "Mch.OBC.OBCMI";
BA_ "Channel" BO_ 2566863533 "can1";
BA_ "GenMsgCycleTime" BO_ 2566864354 50;
BA_ "VssMsg" BO_ 2566864354 "Mch.LC510.RxTFI4OBD";
BA_ "Channel" BO_ 2566864354 "can1";
BA_ "GenMsgCycleTime" BO_ 2566864627 100;
BA_ "VssMsg" BO_ 2566864627 "Mch.AGW.BMSSG";
BA_ "Channel" BO_ 2566864627 "can1";
BA_ "VssMsg" BO_ 2566864680 "Mch.GP.USUHDI";
BA_ "Channel" BO_ 2566864680 "can1";
BA_ "GenMsgCycleTime" BO_ 2566864929 200;
BA_ "VssMsg" BO_ 2566864929 "Mch.MCU.WSG1";
BA_ "Channel" BO_ 2566864929 "can1";
BA_ "GenMsgCycleTime" BO_ 2566865185 200;
BA_ "VssMsg" BO_ 2566865185 "Mch.MCU.WSG2";
BA_ "Channel" BO_ 2566865185 "can1";
BA_ "GenMsgCycleTime" BO_ 2566865441 200;
BA_ "VssMsg" BO_ 2566865441 "Mch.MCU.WSG3";
BA_ "Channel" BO_ 2566865441 "can1";
BA_ "GenMsgCycleTime" BO_ 2566865697 200;
BA_ "VssMsg" BO_ 2566865697 "Mch.MCU.SIG1";
BA_ "Channel" BO_ 2566865697 "can1";
BA_ "VssMsg" BO_ 2566866179 "Mch.TCU.ZFETC9";
BA_ "Channel" BO_ 2566866179 "can1";
BA_ "GenMsgCycleTime" BO_ 2566866209 200;
BA_ "VssMsg" BO_ 2566866209 "Mch.MCU.GPG";
BA_ "Channel" BO_ 2566866209 "can1";
BA_ "GenMsgCycleTime" BO_ 2566866465 200;
BA_ "VssMsg" BO_ 2566866465 "Mch.MCU.UPD";
BA_ "Channel" BO_ 2566866465 "can1";
BA_ "VssSig" SG_ 2348810243 EgReqTrqTrqLmt "Mch.TCU.TSC1.EgReqTrqTrqLmt";
BA_ "VssSig" SG_ 2348810243 EgReqSpdSpdLmt "Mch.TCU.TSC1.EgReqSpdSpdLmt";
BA_ "VssSig" SG_ 2348810243 OvrCtrlMdPri "Mch.TCU.TSC1.OvrCtrlMdPri";
BA_ "VssSig" SG_ 2348810243 EgOvrCtrlMd "Mch.TCU.TSC1.EgOvrCtrlMd";
BA_ "VssSig" SG_ 2348810251 EgReqTrqTrqLmt "Mch.BRK.TSC1.EgReqTrqTrqLmt";
BA_ "VssSig" SG_ 2348810251 EgReqSpdSpdLmt "Mch.BRK.TSC1.EgReqSpdSpdLmt";
BA_ "VssSig" SG_ 2348810251 OvrCtrlMdPri "Mch.BRK.TSC1.OvrCtrlMdPri";
BA_ "VssSig" SG_ 2348810251 EgOvrCtrlMd "Mch.BRK.TSC1.EgOvrCtrlMd";
BA_ "VssSig" SG_ 2348810259 EgReqTrqTrqLmt "Mch.ESP.TSC1.EgReqTrqTrqLmt";
BA_ "VssSig" SG_ 2348810259 EgReqSpdSpdLmt "Mch.ESP.TSC1.EgReqSpdSpdLmt";
BA_ "VssSig" SG_ 2348810259 OvrCtrlMdPri "Mch.ESP.TSC1.OvrCtrlMdPri";
BA_ "VssSig" SG_ 2348810259 EgOvrCtrlMd "Mch.ESP.TSC1.EgOvrCtrlMd";
BA_ "VssSig" SG_ 2348810273 EgReqTrqTrqLmt "Mch.MCU.TSC1.EgReqTrqTrqLmt";
BA_ "VssSig" SG_ 2348810273 EgReqSpdSpdLmt "Mch.MCU.TSC1.EgReqSpdSpdLmt";
BA_ "VssSig" SG_ 2348810273 OvrCtrlMdPri "Mch.MCU.TSC1.OvrCtrlMdPri";
BA_ "VssSig" SG_ 2348810273 EgOvrCtrlMd "Mch.MCU.TSC1.EgOvrCtrlMd";
BA_ "VssSig" SG_ 2564816912 AtRgnFrcSw "Mch.RDD.CM1.AtRgnFrcSw";
BA_ "VssSig" SG_ 2564816912 AtRgnInhbSw "Mch.RDD.CM1.AtRgnInhbSw";
BA_ "VssSig" SG_ 2564816929 AtRgnFrcSw "Mch.MCU.CM1.AtRgnFrcSw";
BA_ "VssSig" SG_ 2564816929 AtRgnInhbSw "Mch.MCU.CM1.AtRgnInhbSw";
BA_ "VssSig" SG_ 2565865733 EgAuxShdnSw "Mch.FNR.EBC1.EgAuxShdnSw";
BA_ "VssSig" SG_ 2565865739 EgAuxShdnSw "Mch.BRK.EBC1.EgAuxShdnSw";
BA_ "VssSig" SG_ 2364539395 TrmInShftSpd "Mch.TCU.ETC1.TrmInShftSpd";
BA_ "VssSig" SG_ 2364539395 TrmsOutShftSpd "Mch.TCU.ETC1.TrmsOutShftSpd";
BA_ "VssSig" SG_ 2364539395 InProTrmShft "Mch.TCU.ETC1.InProTrmShft";
BA_ "VssSig" SG_ 2364539395 TrqCvtLckEng "Mch.TCU.ETC1.TrqCvtLckEng";
BA_ "VssSig" SG_ 2364539395 TrmDrvEng "Mch.TCU.ETC1.TrmDrvEng";
BA_ "VssSig" SG_ 2364539648 AccPdlPos2 "Mch.ECU.EEC2.AccPdlPos2";
BA_ "VssSig" SG_ 2364539648 EgPctLoadCurSpd "Mch.ECU.EEC2.EgPctLoadCurSpd";
BA_ "VssSig" SG_ 2364539648 AccPdlPos1 "Mch.ECU.EEC2.AccPdlPos1";
BA_ "VssSig" SG_ 2364539904 EgSpd "Mch.ECU.EEC1.EgSpd";
BA_ "VssSig" SG_ 2364539904 ActEgPctTrq "Mch.ECU.EEC1.ActEgPctTrq";
BA_ "VssSig" SG_ 2364539904 DrvDmdEgPctTrq "Mch.ECU.EEC1.DrvDmdEgPctTrq";
BA_ "VssSig" SG_ 2565866755 TrmsCurGr "Mch.TCU.ETC2.TrmsCurGr";
BA_ "VssSig" SG_ 2565866755 TrmsActGrRatio "Mch.TCU.ETC2.TrmsActGrRatio";
BA_ "VssSig" SG_ 2565866755 TrmsSelGr "Mch.TCU.ETC2.TrmsSelGr";
BA_ "VssSig" SG_ 2565867011 DifLckStCtrEng "Mch.TCU.EAC1.DifLckStCtrEng";
BA_ "VssSig" SG_ 2364542241 BladeAutoMdCmd "Mch.MCU.LOI.BladeAutoMdCmd";
BA_ "VssSig" SG_ 2364542241 DsrGrdOfsSw "Mch.MCU.LOI.DsrGrdOfsSw";
BA_ "VssSig" SG_ 2364542241 BladeCtrlMdSw "Mch.MCU.LOI.BladeCtrlMdSw";
BA_ "VssSig" SG_ 2565869137 AtIntGasSsHtCtrl "Mch.KPD2.AT1IG1.AtIntGasSsHtCtrl";
BA_ "VssSig" SG_ 2565869137 InRngAtIntGasSsTmp "Mch.KPD2.AT1IG1.InRngAtIntGasSsTmp";
BA_ "VssSig" SG_ 2565869394 AtOutGasSsHtCtrl "Mch.ATSGO.AT1OG1.AtOutGasSsHtCtrl";
BA_ "VssSig" SG_ 2565869394 InRngAtOutGasSsTmp "Mch.ATSGO.AT1OG1.InRngAtOutGasSsTmp";
BA_ "VssSig" SG_ 2364641057 TmSinceLastIpsPgDtt "Mch.MCU.IPGA.TmSinceLastIpsPgDtt";
BA_ "VssSig" SG_ 2364641057 IpsPgn "Mch.MCU.IPGA.IpsPgn";
BA_ "VssSig" SG_ 2364641057 IpsPgDA "Mch.MCU.IPGA.IpsPgDA";
BA_ "VssSig" SG_ 2364641057 IpsPgSA "Mch.MCU.IPGA.IpsPgSA";
BA_ "VssSig" SG_ 2364641057 IpsPgEventDttCounter "Mch.MCU.IPGA.IpsPgEventDttCounter";
BA_ "VssSig" SG_ 2364641267 TmSinceLastIpsPgDtt "Mch.AGW.IPGA.TmSinceLastIpsPgDtt";
BA_ "VssSig" SG_ 2364641267 IpsPgn "Mch.AGW.IPGA.IpsPgn";
BA_ "VssSig" SG_ 2364641267 IpsPgDA "Mch.AGW.IPGA.IpsPgDA";
BA_ "VssSig" SG_ 2364641267 IpsPgSA "Mch.AGW.IPGA.IpsPgSA";
BA_ "VssSig" SG_ 2364641267 IpsPgEventDttCounter "Mch.AGW.IPGA.IpsPgEventDttCounter";
BA_ "VssSig" SG_ 2633828415 Oildieleccst "Mch.HDOQS.OQM1.Oildieleccst";
BA_ "VssSig" SG_ 2633828415 Oildensity "Mch.HDOQS.OQM1.Oildensity";
BA_ "VssSig" SG_ 2633828415 OilVcsty "Mch.HDOQS.OQM1.OilVcsty";
BA_ "VssSig" SG_ 2633828526 Oildieleccst "Mch.EGOQS.OQM1.Oildieleccst";
BA_ "VssSig" SG_ 2633828526 Oildensity "Mch.EGOQS.OQM1.Oildensity";
BA_ "VssSig" SG_ 2633828526 OilVcsty "Mch.EGOQS.OQM1.OilVcsty";
BA_ "VssSig" SG_ 2566725632 At1DocDifPrsPrlFmi "Mch.ECU.A1DOC1.At1DocDifPrsPrlFmi";
BA_ "VssSig" SG_ 2566725632 At1DocOutTmpPrlFmi "Mch.ECU.A1DOC1.At1DocOutTmpPrlFmi";
BA_ "VssSig" SG_ 2566725632 At1DocInTmpPrlFmi "Mch.ECU.A1DOC1.At1DocInTmpPrlFmi";
BA_ "VssSig" SG_ 2566725632 At1DocDifPrs "Mch.ECU.A1DOC1.At1DocDifPrs";
BA_ "VssSig" SG_ 2566725632 At1DocOutTmp "Mch.ECU.A1DOC1.At1DocOutTmp";
BA_ "VssSig" SG_ 2566725632 At1DocInTmp "Mch.ECU.A1DOC1.At1DocInTmp";
BA_ "VssSig" SG_ 2566748928 DpfSootLoadPct "Mch.ECU.AT1S.DpfSootLoadPct";
BA_ "VssSig" SG_ 2566749184 At1DpfCondNotMetforActvRgn "Mch.ECU.DPFC1.At1DpfCondNotMetforActvRgn";
BA_ "VssSig" SG_ 2566749184 DpfActvRgnIhbDuetoLowExhPrs "Mch.ECU.DPFC1.DpfActvRgnIhbDuetoLowExhPrs";
BA_ "VssSig" SG_ 2566749184 HydrocarbonDoserPurgingEnb "Mch.ECU.DPFC1.HydrocarbonDoserPurgingEnb";
BA_ "VssSig" SG_ 2566749184 DpfActvRgnForcedSt "Mch.ECU.DPFC1.DpfActvRgnForcedSt";
BA_ "VssSig" SG_ 2566749184 ExhSysHhTmpLmpCmd "Mch.ECU.DPFC1.ExhSysHhTmpLmpCmd";
BA_ "VssSig" SG_ 2566749184 DpfAutoActvRgnInitiationConfig "Mch.ECU.DPFC1.DpfAutoActvRgnInitiationConfig";
BA_ "VssSig" SG_ 2566749184 DpfActvRgnIhbVhcSpdBelowAllowedS "Mch.ECU.DPFC1.DpfActvRgnIhbVhcSpdBelowAllowedSpd";
BA_ "SystemSignalLongSymbol" SG_ 2566749184 DpfActvRgnIhbVhcSpdBelowAllowedS "DpfActvRgnIhbVhcSpdBelowAllowedSpd";
BA_ "VssSig" SG_ 2566749184 DpfActvRgnIhbEgNotWarmedUp "Mch.ECU.DPFC1.DpfActvRgnIhbEgNotWarmedUp";
BA_ "VssSig" SG_ 2566749184 DpfActvRgnIhbPmnSysLockout "Mch.ECU.DPFC1.DpfActvRgnIhbPmnSysLockout";
BA_ "VssSig" SG_ 2566749184 DpfActvRgnIhbTprSysLockout "Mch.ECU.DPFC1.DpfActvRgnIhbTprSysLockout";
BA_ "VssSig" SG_ 2566749184 DpfActvRgnIhbSysTmout "Mch.ECU.DPFC1.DpfActvRgnIhbSysTmout";
BA_ "VssSig" SG_ 2566749184 DpfActvRgnIhbSysFaultActv "Mch.ECU.DPFC1.DpfActvRgnIhbSysFaultActv";
BA_ "VssSig" SG_ 2566749184 DpfActvRgnIhbLowExhTmp "Mch.ECU.DPFC1.DpfActvRgnIhbLowExhTmp";
BA_ "VssSig" SG_ 2566749184 DpfActvRgnIhbPrkBrkNotSet "Mch.ECU.DPFC1.DpfActvRgnIhbPrkBrkNotSet";
BA_ "VssSig" SG_ 2566749184 DpfActvRgnIhbVhcSpdAboveAllowedS "Mch.ECU.DPFC1.DpfActvRgnIhbVhcSpdAboveAllowedSpd";
BA_ "SystemSignalLongSymbol" SG_ 2566749184 DpfActvRgnIhbVhcSpdAboveAllowedS "DpfActvRgnIhbVhcSpdAboveAllowedSpd";
BA_ "VssSig" SG_ 2566749184 DpfActvRgnIhbOutofNtrl "Mch.ECU.DPFC1.DpfActvRgnIhbOutofNtrl";
BA_ "VssSig" SG_ 2566749184 DpfActvRgnIhbAccPdlOffIdle "Mch.ECU.DPFC1.DpfActvRgnIhbAccPdlOffIdle";
BA_ "VssSig" SG_ 2566749184 DpfActvRgnIhbPtoActv "Mch.ECU.DPFC1.DpfActvRgnIhbPtoActv";
BA_ "VssSig" SG_ 2566749184 DpfActvRgnIhbServiceBrkActv "Mch.ECU.DPFC1.DpfActvRgnIhbServiceBrkActv";
BA_ "VssSig" SG_ 2566749184 DpfActvRgnIhbClutchDisengaged "Mch.ECU.DPFC1.DpfActvRgnIhbClutchDisengaged";
BA_ "VssSig" SG_ 2566749184 DpfActvRgnIhbInhibitSwitch "Mch.ECU.DPFC1.DpfActvRgnIhbInhibitSwitch";
BA_ "VssSig" SG_ 2566749184 DpfActvRgnIhbSt "Mch.ECU.DPFC1.DpfActvRgnIhbSt";
BA_ "VssSig" SG_ 2566749184 AtDpfSt "Mch.ECU.DPFC1.AtDpfSt";
BA_ "VssSig" SG_ 2566749184 AtDpfActvRgnSt "Mch.ECU.DPFC1.AtDpfActvRgnSt";
BA_ "VssSig" SG_ 2566749184 AtDpfPassiveRgnSt "Mch.ECU.DPFC1.AtDpfPassiveRgnSt";
BA_ "VssSig" SG_ 2566749184 DpfActvRgnAvailabilitySt "Mch.ECU.DPFC1.DpfActvRgnAvailabilitySt";
BA_ "VssSig" SG_ 2566749184 DpfLampCmd "Mch.ECU.DPFC1.DpfLampCmd";
BA_ "VssSig" SG_ 2566755587 TrqCvtOilOutTmp "Mch.TCU.TRF2.TrqCvtOilOutTmp";
BA_ "VssSig" SG_ 2566755587 TrmOilFiltRstrSw "Mch.TCU.TRF2.TrmOilFiltRstrSw";
BA_ "VssSig" SG_ 2566757120 AtDefPpt "Mch.ECU.A1DEFI1.AtDefPpt";
BA_ "VssSig" SG_ 2566757120 AtDefCct "Mch.ECU.A1DEFI1.AtDefCct";
BA_ "VssSig" SG_ 2566758656 AtFuelInjHtCtrl "Mch.ECU.AT1FC1.AtFuelInjHtCtrl";
BA_ "VssSig" SG_ 2566758656 AtIgn "Mch.ECU.AT1FC1.AtIgn";
BA_ "VssSig" SG_ 2566758656 AtFuelPrsCtrl "Mch.ECU.AT1FC1.AtFuelPrsCtrl";
BA_ "VssSig" SG_ 2566758656 AtFuelRate "Mch.ECU.AT1FC1.AtFuelRate";
BA_ "VssSig" SG_ 2566758656 AtFuelPrs "Mch.ECU.AT1FC1.AtFuelPrs";
BA_ "VssSig" SG_ 2566763008 At1DpfIntmTmpPrlFmi "Mch.ECU.AT1IMG.At1DpfIntmTmpPrlFmi";
BA_ "VssSig" SG_ 2566763008 At1DpfDifPrsPrlFmi "Mch.ECU.AT1IMG.At1DpfDifPrsPrlFmi";
BA_ "VssSig" SG_ 2566763008 At1ExhTmp2PrlFmi "Mch.ECU.AT1IMG.At1ExhTmp2PrlFmi";
BA_ "VssSig" SG_ 2566763008 At1DpfDifPrs "Mch.ECU.AT1IMG.At1DpfDifPrs";
BA_ "VssSig" SG_ 2566763008 At1DpfIntmTmp "Mch.ECU.AT1IMG.At1DpfIntmTmp";
BA_ "VssSig" SG_ 2566763008 At1ExhTmp2 "Mch.ECU.AT1IMG.At1ExhTmp2";
BA_ "VssSig" SG_ 2566763264 At1DpfOutExhTmpPrlFmi "Mch.ECU.AT1OG2.At1DpfOutExhTmpPrlFmi";
BA_ "VssSig" SG_ 2566763264 At1ExhTmp3PrlFmi "Mch.ECU.AT1OG2.At1ExhTmp3PrlFmi";
BA_ "VssSig" SG_ 2566763264 At1DpfOutTmp "Mch.ECU.AT1OG2.At1DpfOutTmp";
BA_ "VssSig" SG_ 2566763264 At1ExhTmp3 "Mch.ECU.AT1OG2.At1ExhTmp3";
BA_ "VssSig" SG_ 2566763325 At1DpfOutExhTmpPrlFmi "Mch.EEC.AT1OG2.At1DpfOutExhTmpPrlFmi";
BA_ "VssSig" SG_ 2566763325 At1ExhTmp3PrlFmi "Mch.EEC.AT1OG2.At1ExhTmp3PrlFmi";
BA_ "VssSig" SG_ 2566763325 At1DpfOutTmp "Mch.EEC.AT1OG2.At1DpfOutTmp";
BA_ "VssSig" SG_ 2566763325 At1ExhTmp3 "Mch.EEC.AT1OG2.At1ExhTmp3";
BA_ "VssSig" SG_ 2566763520 At1DpfInTmpPrlFmi "Mch.ECU.AT1IG2.At1DpfInTmpPrlFmi";
BA_ "VssSig" SG_ 2566763520 At1ExhTmp1PrlFmi "Mch.ECU.AT1IG2.At1ExhTmp1PrlFmi";
BA_ "VssSig" SG_ 2566763520 At1DpfInTmp "Mch.ECU.AT1IG2.At1DpfInTmp";
BA_ "VssSig" SG_ 2566763520 At1ExhTmp1 "Mch.ECU.AT1IG2.At1ExhTmp1";
BA_ "VssSig" SG_ 2566763581 At1DpfInTmpPrlFmi "Mch.EEC.AT1IG2.At1DpfInTmpPrlFmi";
BA_ "VssSig" SG_ 2566763581 At1ExhTmp1PrlFmi "Mch.EEC.AT1IG2.At1ExhTmp1PrlFmi";
BA_ "VssSig" SG_ 2566763581 At1DpfInTmp "Mch.EEC.AT1IG2.At1DpfInTmp";
BA_ "VssSig" SG_ 2566763581 At1ExhTmp1 "Mch.EEC.AT1IG2.At1ExhTmp1";
BA_ "VssSig" SG_ 2566769997 FrOprtWashSw "Mch.CBSW.OWW.FrOprtWashSw";
BA_ "VssSig" SG_ 2566769997 FrOprtWiperDlyCtrl "Mch.CBSW.OWW.FrOprtWiperDlyCtrl";
BA_ "VssSig" SG_ 2566769997 FrOprtWiperSw "Mch.CBSW.OWW.FrOprtWiperSw";
BA_ "VssSig" SG_ 2566771968 EgEgrVvCtrl "Mch.ECU.EEC5.EgEgrVvCtrl";
BA_ "VssSig" SG_ 2365468962 PortFlowHighResolution "Mch.TRBDZ.AV01C.PortFlowHighResolution";
BA_ "VssSig" SG_ 2365468962 FailSafeMd "Mch.TRBDZ.AV01C.FailSafeMd";
BA_ "VssSig" SG_ 2365468962 VvSt "Mch.TRBDZ.AV01C.VvSt";
BA_ "VssSig" SG_ 2365468962 ResolutionMd "Mch.TRBDZ.AV01C.ResolutionMd";
BA_ "VssSig" SG_ 2365468962 AuxVv1PortFlowCmd "Mch.TRBDZ.AV01C.AuxVv1PortFlowCmd";
BA_ "VssSig" SG_ 2365469218 PortFlowHighResolution "Mch.TRBDZ.AV02C.PortFlowHighResolution";
BA_ "VssSig" SG_ 2365469218 FailSafeMd "Mch.TRBDZ.AV02C.FailSafeMd";
BA_ "VssSig" SG_ 2365469218 VvSt "Mch.TRBDZ.AV02C.VvSt";
BA_ "VssSig" SG_ 2365469218 ResolutionMd "Mch.TRBDZ.AV02C.ResolutionMd";
BA_ "VssSig" SG_ 2365469218 AuxVv1PortFlowCmd "Mch.TRBDZ.AV02C.AuxVv1PortFlowCmd";
BA_ "VssSig" SG_ 2365473101 LTurnSigLhtsCmd "Mch.CBSW.LCMD.LTurnSigLhtsCmd";
BA_ "VssSig" SG_ 2365473101 RTurnSigLhtsCmd "Mch.CBSW.LCMD.RTurnSigLhtsCmd";
BA_ "VssSig" SG_ 2365473101 HighBeamHeadLhtCmd "Mch.CBSW.LCMD.HighBeamHeadLhtCmd";
BA_ "VssSig" SG_ 2365473101 LowBeamHeadLhtCmd "Mch.CBSW.LCMD.LowBeamHeadLhtCmd";
BA_ "VssSig" SG_ 2365473101 AltBeamHeadLhtCmd "Mch.CBSW.LCMD.AltBeamHeadLhtCmd";
BA_ "VssSig" SG_ 2566802176 EgThrtActCtrlCmd "Mch.ECU.TCFG2.EgThrtActCtrlCmd";
BA_ "VssSig" SG_ 2566804992 AtSelCatalRedOprIndAct "Mch.ECU.AT1T1I1.AtSelCatalRedOprIndAct";
BA_ "VssSig" SG_ 2566804992 AtDefTnkTmp "Mch.ECU.AT1T1I1.AtDefTnkTmp";
BA_ "VssSig" SG_ 2566804992 AtDefTnkLv "Mch.ECU.AT1T1I1.AtDefTnkLv";
BA_ "VssSig" SG_ 2566804993 AtSelCatalRedOprIndAct "Mch.ECU1.AT1T1I1.AtSelCatalRedOprIndAct";
BA_ "VssSig" SG_ 2566804993 AtDefTnkTmp "Mch.ECU1.AT1T1I1.AtDefTnkTmp";
BA_ "VssSig" SG_ 2566804993 AtDefTnkLv "Mch.ECU1.AT1T1I1.AtDefTnkLv";
BA_ "VssSig" SG_ 2566831360 FanDrvBypassCmdSt "Mch.ECU.FD1.FanDrvBypassCmdSt";
BA_ "VssSig" SG_ 2566831360 HyhFanMotorPrs "Mch.ECU.FD1.HyhFanMotorPrs";
BA_ "VssSig" SG_ 2566831360 FanSpd "Mch.ECU.FD1.FanSpd";
BA_ "VssSig" SG_ 2566831360 FanDrvSt "Mch.ECU.FD1.FanDrvSt";
BA_ "VssSig" SG_ 2566831360 EgFan1EstimatedPctSpd "Mch.ECU.FD1.EgFan1EstimatedPctSpd";
BA_ "VssSig" SG_ 2566840064 At1ExhGasMasFlw "Mch.ECU.EEC3.At1ExhGasMasFlw";
BA_ "VssSig" SG_ 2566840064 EgDsrOprSpd "Mch.ECU.EEC3.EgDsrOprSpd";
BA_ "VssSig" SG_ 2566840064 NrmFricPctTrq "Mch.ECU.EEC3.NrmFricPctTrq";
BA_ "VssSig" SG_ 2566841600 EgTotRev "Mch.ECU.HOURS.EgTotRev";
BA_ "VssSig" SG_ 2566841600 EgTotHrOpr "Mch.ECU.HOURS.EgTotHrOpr";
BA_ "VssSig" SG_ 2566842624 EgTotFuelUsed "Mch.ECU.LFC1.EgTotFuelUsed";
BA_ "VssSig" SG_ 2566842624 EgTripFuel "Mch.ECU.LFC1.EgTripFuel";
BA_ "VssSig" SG_ 2566843904 EgChgAirCoolThrmst "Mch.ECU.ET1.EgChgAirCoolThrmst";
BA_ "VssSig" SG_ 2566843904 EgInCoolTmp "Mch.ECU.ET1.EgInCoolTmp";
BA_ "VssSig" SG_ 2566843904 EgTurboChgOilTmp "Mch.ECU.ET1.EgTurboChgOilTmp";
BA_ "VssSig" SG_ 2566843904 EgOilTmp1 "Mch.ECU.ET1.EgOilTmp1";
BA_ "VssSig" SG_ 2566843904 EgFuelTmp "Mch.ECU.ET1.EgFuelTmp";
BA_ "VssSig" SG_ 2566843904 EgCoolTmp "Mch.ECU.ET1.EgCoolTmp";
BA_ "VssSig" SG_ 2566843967 OilAvrgTmp "Mch.HDOQS.OT.OilAvrgTmp";
BA_ "VssSig" SG_ 2566844078 OilAvrgTmp "Mch.EGOQS.OT.OilAvrgTmp";
BA_ "VssSig" SG_ 2566844160 EgCoolLv "Mch.ECU.EFLP1.EgCoolLv";
BA_ "VssSig" SG_ 2566844160 EgCrkcasePrs "Mch.ECU.EFLP1.EgCrkcasePrs";
BA_ "VssSig" SG_ 2566844160 EgOilPrs "Mch.ECU.EFLP1.EgOilPrs";
BA_ "VssSig" SG_ 2566844160 EgFuelDlvPrs "Mch.ECU.EFLP1.EgFuelDlvPrs";
BA_ "VssSig" SG_ 2566844672 WhlVhcSpd "Mch.ECU.CCVS.WhlVhcSpd";
BA_ "VssSig" SG_ 2566844675 WhlVhcSpd "Mch.TCU.CCVS.WhlVhcSpd";
BA_ "VssSig" SG_ 2566844705 WhlVhcSpd "Mch.MCU.CCVS.WhlVhcSpd";
BA_ "VssSig" SG_ 2566844928 EgThrtVvPos "Mch.ECU.LFE1.EgThrtVvPos";
BA_ "VssSig" SG_ 2566844928 EgFuelRate "Mch.ECU.LFE1.EgFuelRate";
BA_ "VssSig" SG_ 2566845696 EgAirIntTmp "Mch.ECU.AMB.EgAirIntTmp";
BA_ "VssSig" SG_ 2566845696 AmbAirTmp "Mch.ECU.AMB.AmbAirTmp";
BA_ "VssSig" SG_ 2566845696 BaroPrs "Mch.ECU.AMB.BaroPrs";
BA_ "VssSig" SG_ 2566845952 EgAirIntPrs "Mch.ECU.IC1.EgAirIntPrs";
BA_ "VssSig" SG_ 2566845952 EgIntMnfdTmp "Mch.ECU.IC1.EgIntMnfdTmp";
BA_ "VssSig" SG_ 2566845952 EgIntMnfdPrs "Mch.ECU.IC1.EgIntMnfdPrs";
BA_ "VssSig" SG_ 2566846208 KeyswBatPtc "Mch.ECU.VEP1.KeyswBatPtc";
BA_ "VssSig" SG_ 2566846208 BatPtcPowIn "Mch.ECU.VEP1.BatPtcPowIn";
BA_ "VssSig" SG_ 2566847235 TrmOilFiltRstrSw "Mch.TCU.RF.TrmOilFiltRstrSw";
BA_ "VssSig" SG_ 2566852897 MsgCs "Mch.MCU.SMVCU.MsgCs";
BA_ "VssSig" SG_ 2566852897 MsgCnt "Mch.MCU.SMVCU.MsgCnt";
BA_ "VssSig" SG_ 2566852897 PrkBrkSw "Mch.MCU.SMVCU.PrkBrkSw";
BA_ "VssSig" SG_ 2566852897 StartCtrlReq "Mch.MCU.SMVCU.StartCtrlReq";
BA_ "VssSig" SG_ 2566852897 VhcSpd "Mch.MCU.SMVCU.VhcSpd";
BA_ "VssSig" SG_ 2566852897 CCAccSw "Mch.MCU.SMVCU.CCAccSw";
BA_ "VssSig" SG_ 2566852897 CCRsmSw "Mch.MCU.SMVCU.CCRsmSw";
BA_ "VssSig" SG_ 2566852897 CCCoastSw "Mch.MCU.SMVCU.CCCoastSw";
BA_ "VssSig" SG_ 2566852897 CCSetSw "Mch.MCU.SMVCU.CCSetSw";
BA_ "VssSig" SG_ 2566852897 PtoSt "Mch.MCU.SMVCU.PtoSt";
BA_ "VssSig" SG_ 2566852897 RddtBrk "Mch.MCU.SMVCU.RddtBrk";
BA_ "VssSig" SG_ 2566852897 BrkSw "Mch.MCU.SMVCU.BrkSw";
BA_ "VssSig" SG_ 2566852897 LisSw "Mch.MCU.SMVCU.LisSw";
BA_ "VssSig" SG_ 2566852897 FinAccPdlPos "Mch.MCU.SMVCU.FinAccPdlPos";
BA_ "VssSig" SG_ 2365527585 Crc16forDtbytes "Mch.MCU.ASDJPR.Crc16forDtbytes";
BA_ "VssSig" SG_ 2365527585 Errorcode "Mch.MCU.ASDJPR.Errorcode";
BA_ "VssSig" SG_ 2365527585 SequenceNo "Mch.MCU.ASDJPR.SequenceNo";
BA_ "VssSig" SG_ 2365527585 JoyEnbsignal "Mch.MCU.ASDJPR.JoyEnbsignal";
BA_ "VssSig" SG_ 2365527585 JoyNtrlPostrim "Mch.MCU.ASDJPR.JoyNtrlPostrim";
BA_ "VssSig" SG_ 2365527585 JoyPos "Mch.MCU.ASDJPR.JoyPos";
BA_ "VssSig" SG_ 2365527841 Crc16forDtbytes "Mch.MCU.ASDJRD.Crc16forDtbytes";
BA_ "VssSig" SG_ 2365527841 Errorcode "Mch.MCU.ASDJRD.Errorcode";
BA_ "VssSig" SG_ 2365527841 SequenceNo "Mch.MCU.ASDJRD.SequenceNo";
BA_ "VssSig" SG_ 2365527841 JoyEnbsignal "Mch.MCU.ASDJRD.JoyEnbsignal";
BA_ "VssSig" SG_ 2365527841 JoyNtrlPostrim "Mch.MCU.ASDJRD.JoyNtrlPostrim";
BA_ "VssSig" SG_ 2365527841 JoyPos "Mch.MCU.ASDJRD.JoyPos";
BA_ "VssSig" SG_ 2365528097 Crc16forDtbytes "Mch.MCU.VSPR.Crc16forDtbytes";
BA_ "VssSig" SG_ 2365528097 SequenceNo "Mch.MCU.VSPR.SequenceNo";
BA_ "VssSig" SG_ 2365528097 VhcSpd "Mch.MCU.VSPR.VhcSpd";
BA_ "VssSig" SG_ 2365528097 DirIndication "Mch.MCU.VSPR.DirIndication";
BA_ "VssSig" SG_ 2365528353 Crc16forDtbytes "Mch.MCU.VSRD.Crc16forDtbytes";
BA_ "VssSig" SG_ 2365528353 SequenceNo "Mch.MCU.VSRD.SequenceNo";
BA_ "VssSig" SG_ 2365528353 VhcSpd "Mch.MCU.VSRD.VhcSpd";
BA_ "VssSig" SG_ 2365528353 Drtindication "Mch.MCU.VSRD.Drtindication";
BA_ "VssSig" SG_ 2566856960 DpfSootLv "Mch.ECU.EDC2BC.DpfSootLv";
BA_ "VssSig" SG_ 2566856960 EdcOprSt "Mch.ECU.EDC2BC.EdcOprSt";
BA_ "VssSig" SG_ 2566856960 EgDgrdLv "Mch.ECU.EDC2BC.EgDgrdLv";
BA_ "VssSig" SG_ 2566856960 EgOilTmpHh "Mch.ECU.EDC2BC.EgOilTmpHh";
BA_ "VssSig" SG_ 2566856960 FuelFiltHtSt "Mch.ECU.EDC2BC.FuelFiltHtSt";
BA_ "VssSig" SG_ 2566856960 WifWrn "Mch.ECU.EDC2BC.WifWrn";
BA_ "VssSig" SG_ 2566856960 EgOilPrsLw "Mch.ECU.EDC2BC.EgOilPrsLw";
BA_ "VssSig" SG_ 2566856960 BtnStp "Mch.ECU.EDC2BC.BtnStp";
BA_ "VssSig" SG_ 2566856960 RgnLmp "Mch.ECU.EDC2BC.RgnLmp";
BA_ "VssSig" SG_ 2566856960 HydPmpActReq "Mch.ECU.EDC2BC.HydPmpActReq";
BA_ "VssSig" SG_ 2566856960 MIL "Mch.ECU.EDC2BC.MIL";
BA_ "VssSig" SG_ 2566856960 EgOvrSpd "Mch.ECU.EDC2BC.EgOvrSpd";
BA_ "VssSig" SG_ 2566856960 SpdLmtLmp "Mch.ECU.EDC2BC.SpdLmtLmp";
BA_ "VssSig" SG_ 2566856960 DiagLmp "Mch.ECU.EDC2BC.DiagLmp";
BA_ "VssSig" SG_ 2566856960 FuelBlock "Mch.ECU.EDC2BC.FuelBlock";
BA_ "VssSig" SG_ 2566856960 ColdStartHt "Mch.ECU.EDC2BC.ColdStartHt";
BA_ "VssSig" SG_ 2566857219 CnvtTurbTrq "Mch.TCU.TCU4.CnvtTurbTrq";
BA_ "VssSig" SG_ 2566857219 CnvtPmpTrq "Mch.TCU.TCU4.CnvtPmpTrq";
BA_ "VssSig" SG_ 2566857984 PhsDifCrkCam "Mch.ECU.ENGCOND.PhsDifCrkCam";
BA_ "VssSig" SG_ 2566857984 EgOprCmd "Mch.ECU.ENGCOND.EgOprCmd";
BA_ "VssSig" SG_ 2566857984 AirMassPrs "Mch.ECU.ENGCOND.AirMassPrs";
BA_ "VssSig" SG_ 2566858752 RedFanSpd100 "Mch.ECU.FanCtl.RedFanSpd100";
BA_ "VssSig" SG_ 2566858752 RedFanSpd70 "Mch.ECU.FanCtl.RedFanSpd70";
BA_ "VssSig" SG_ 2566858752 RedFanSpd50 "Mch.ECU.FanCtl.RedFanSpd50";
BA_ "VssSig" SG_ 2566858752 RedFanSpd30 "Mch.ECU.FanCtl.RedFanSpd30";
BA_ "VssSig" SG_ 2566858752 RedFanSpd0 "Mch.ECU.FanCtl.RedFanSpd0";
BA_ "VssSig" SG_ 2566859523 IsEngDrvSt "Mch.TCU.TCU1.IsEngDrvSt";
BA_ "VssSig" SG_ 2566859523 InProcShftSt "Mch.TCU.TCU1.InProcShftSt";
BA_ "VssSig" SG_ 2566859523 OpMd "Mch.TCU.TCU1.OpMd";
BA_ "VssSig" SG_ 2566859523 IsActJoyMd "Mch.TCU.TCU1.IsActJoyMd";
BA_ "VssSig" SG_ 2566859523 CurDir "Mch.TCU.TCU1.CurDir";
BA_ "VssSig" SG_ 2566859523 CurGr "Mch.TCU.TCU1.CurGr";
BA_ "VssSig" SG_ 2566859523 DifLck "Mch.TCU.TCU1.DifLck";
BA_ "VssSig" SG_ 2566859523 ShftDir "Mch.TCU.TCU1.ShftDir";
BA_ "VssSig" SG_ 2566859523 ShftRng "Mch.TCU.TCU1.ShftRng";
BA_ "VssSig" SG_ 2566859523 ErrCode "Mch.TCU.TCU1.ErrCode";
BA_ "VssSig" SG_ 2566859523 OutSpd "Mch.TCU.TCU1.OutSpd";
BA_ "VssSig" SG_ 2566859523 EgSpd "Mch.TCU.TCU1.EgSpd";
BA_ "VssSig" SG_ 2566860833 ChgSt "Mch.MCU.VCUHVCI.ChgSt";
BA_ "VssSig" SG_ 2566860833 MchKeyOnSt "Mch.MCU.VCUHVCI.MchKeyOnSt";
BA_ "VssSig" SG_ 2566860833 OnBrdChgCmd "Mch.MCU.VCUHVCI.OnBrdChgCmd";
BA_ "VssSig" SG_ 2566860833 QckChgEnableCmd "Mch.MCU.VCUHVCI.QckChgEnableCmd";
BA_ "VssSig" SG_ 2566860833 PowDnCmd "Mch.MCU.VCUHVCI.PowDnCmd";
BA_ "VssSig" SG_ 2566861056 FiltTm "Mch.ECU.TFI4CMD.FiltTm";
BA_ "VssSig" SG_ 2566861056 Cmd "Mch.ECU.TFI4CMD.Cmd";
BA_ "VssSig" SG_ 2566861119 StMsgCode "Mch.HDOQS.OSM.StMsgCode";
BA_ "VssSig" SG_ 2566861230 StMsgCode "Mch.EGOQS.OSM.StMsgCode";
BA_ "VssSig" SG_ 2566863533 FanSt "Mch.OBC.OBCMI.FanSt";
BA_ "VssSig" SG_ 2566863533 PdVlt "Mch.OBC.OBCMI.PdVlt";
BA_ "VssSig" SG_ 2566863533 CpVlt "Mch.OBC.OBCMI.CpVlt";
BA_ "VssSig" SG_ 2566863533 ObcAtmosphereTemp "Mch.OBC.OBCMI.ObcAtmosphereTemp";
BA_ "VssSig" SG_ 2566863533 ObcMaxTemp "Mch.OBC.OBCMI.ObcMaxTemp";
BA_ "VssSig" SG_ 2566863533 PfcVlt "Mch.OBC.OBCMI.PfcVlt";
BA_ "VssSig" SG_ 2566863533 AcInCur "Mch.OBC.OBCMI.AcInCur";
BA_ "VssSig" SG_ 2566863533 AcInFrequency "Mch.OBC.OBCMI.AcInFrequency";
BA_ "VssSig" SG_ 2566863533 AcInVlt "Mch.OBC.OBCMI.AcInVlt";
BA_ "VssSig" SG_ 2566863533 ChgElapsedTm "Mch.OBC.OBCMI.ChgElapsedTm";
BA_ "VssSig" SG_ 2566864627 EstimatedChgTm "Mch.AGW.BMSSG.EstimatedChgTm";
BA_ "VssSig" SG_ 2566864627 ChgSt "Mch.AGW.BMSSG.ChgSt";
BA_ "VssSig" SG_ 2566864627 HtPadSt "Mch.AGW.BMSSG.HtPadSt";
BA_ "VssSig" SG_ 2566864627 BmsChgSType "Mch.AGW.BMSSG.BmsChgSType";
BA_ "VssSig" SG_ 2566864680 FuelEfficiencybyUser "Mch.GP.USUHDI.FuelEfficiencybyUser";
BA_ "VssSig" SG_ 2566864680 EcnMdFuelUsgbyUser "Mch.GP.USUHDI.EcnMdFuelUsgbyUser";
BA_ "VssSig" SG_ 2566864680 StdMdFuelUsgbyUser "Mch.GP.USUHDI.StdMdFuelUsgbyUser";
BA_ "VssSig" SG_ 2566864680 PwrMdFuelUsgbyUser "Mch.GP.USUHDI.PwrMdFuelUsgbyUser";
BA_ "VssSig" SG_ 2566864680 PwrPlusMdFuelUsgbyUser "Mch.GP.USUHDI.PwrPlusMdFuelUsgbyUser";
BA_ "VssSig" SG_ 2566864680 TotalFuelUsgbyUser "Mch.GP.USUHDI.TotalFuelUsgbyUser";
BA_ "VssSig" SG_ 2566864680 EcnMdOprtgHrbyUser "Mch.GP.USUHDI.EcnMdOprtgHrbyUser";
BA_ "VssSig" SG_ 2566864680 StdMdOprtgHrbyUser "Mch.GP.USUHDI.StdMdOprtgHrbyUser";
BA_ "VssSig" SG_ 2566864680 PwrMdOprtgHrbyUser "Mch.GP.USUHDI.PwrMdOprtgHrbyUser";
BA_ "VssSig" SG_ 2566864680 PwrPlusMdOprtgHrbyUser "Mch.GP.USUHDI.PwrPlusMdOprtgHrbyUser";
BA_ "VssSig" SG_ 2566864680 IdleOprtgHrbyUser "Mch.GP.USUHDI.IdleOprtgHrbyUser";
BA_ "VssSig" SG_ 2566864680 TotalOprtgHrbyUser "Mch.GP.USUHDI.TotalOprtgHrbyUser";
BA_ "VssSig" SG_ 2566864680 UserName "Mch.GP.USUHDI.UserName";
BA_ "VssSig" SG_ 2566864680 UserSeparatorFlag "Mch.GP.USUHDI.UserSeparatorFlag";
BA_ "VssSig" SG_ 2566864680 UserSeparatorSlot "Mch.GP.USUHDI.UserSeparatorSlot";
BA_ "VssSig" SG_ 2566864929 InvOh "Mch.MCU.WSG1.InvOh";
BA_ "VssSig" SG_ 2566864929 MotOh "Mch.MCU.WSG1.MotOh";
BA_ "VssSig" SG_ 2566864929 BatOh "Mch.MCU.WSG1.BatOh";
BA_ "VssSig" SG_ 2566864929 Bms "Mch.MCU.WSG1.Bms";
BA_ "VssSig" SG_ 2566864929 BatHt "Mch.MCU.WSG1.BatHt";
BA_ "VssSig" SG_ 2566864929 TrvlPdlFail "Mch.MCU.WSG1.TrvlPdlFail";
BA_ "VssSig" SG_ 2566864929 RrWhlAlgn "Mch.MCU.WSG1.RrWhlAlgn";
BA_ "VssSig" SG_ 2566864929 PrkBrkPrs "Mch.MCU.WSG1.PrkBrkPrs";
BA_ "VssSig" SG_ 2566864929 TrsmOilFiltClog "Mch.MCU.WSG1.TrsmOilFiltClog";
BA_ "VssSig" SG_ 2566864929 FanMotPrsLw "Mch.MCU.WSG1.FanMotPrsLw";
BA_ "VssSig" SG_ 2566864929 OvSpd "Mch.MCU.WSG1.OvSpd";
BA_ "VssSig" SG_ 2566864929 RBrkPdlNoCalb "Mch.MCU.WSG1.RBrkPdlNoCalb";
BA_ "VssSig" SG_ 2566864929 ElecStr "Mch.MCU.WSG1.ElecStr";
BA_ "VssSig" SG_ 2566864929 EgOvr "Mch.MCU.WSG1.EgOvr";
BA_ "VssSig" SG_ 2566864929 EmgStr "Mch.MCU.WSG1.EmgStr";
BA_ "VssSig" SG_ 2566864929 SeatBelt "Mch.MCU.WSG1.SeatBelt";
BA_ "VssSig" SG_ 2566864929 TrsmOilOh "Mch.MCU.WSG1.TrsmOilOh";
BA_ "VssSig" SG_ 2566864929 Trsm "Mch.MCU.WSG1.Trsm";
BA_ "VssSig" SG_ 2566864929 VboEpprVvOut "Mch.MCU.WSG1.VboEpprVvOut";
BA_ "VssSig" SG_ 2566864929 VboJoySs "Mch.MCU.WSG1.VboJoySs";
BA_ "VssSig" SG_ 2566864929 VboAngSs "Mch.MCU.WSG1.VboAngSs";
BA_ "VssSig" SG_ 2566864929 BatEq "Mch.MCU.WSG1.BatEq";
BA_ "VssSig" SG_ 2566864929 Uss "Mch.MCU.WSG1.Uss";
BA_ "VssSig" SG_ 2566864929 IceptSs "Mch.MCU.WSG1.IceptSs";
BA_ "VssSig" SG_ 2566864929 Str "Mch.MCU.WSG1.Str";
BA_ "VssSig" SG_ 2566864929 BrkOilPrsLw "Mch.MCU.WSG1.BrkOilPrsLw";
BA_ "VssSig" SG_ 2566864929 Ags "Mch.MCU.WSG1.Ags";
BA_ "VssSig" SG_ 2566864929 Owd "Mch.MCU.WSG1.Owd";
BA_ "VssSig" SG_ 2566864929 PilotFilt "Mch.MCU.WSG1.PilotFilt";
BA_ "VssSig" SG_ 2566864929 RetFilt "Mch.MCU.WSG1.RetFilt";
BA_ "VssSig" SG_ 2566864929 HydOilOh "Mch.MCU.WSG1.HydOilOh";
BA_ "VssSig" SG_ 2566864929 BatChg "Mch.MCU.WSG1.BatChg";
BA_ "VssSig" SG_ 2566865185 AcleOilOh "Mch.MCU.WSG2.AcleOilOh";
BA_ "VssSig" SG_ 2566865185 AxleOilOvrHtFr "Mch.MCU.WSG2.AxleOilOvrHtFr";
BA_ "VssSig" SG_ 2566865185 AxleOilOvrHtRr "Mch.MCU.WSG2.AxleOilOvrHtRr";
BA_ "VssSig" SG_ 2566865185 EgOilLv "Mch.MCU.WSG2.EgOilLv";
BA_ "VssSig" SG_ 2566865185 ShtShftShutDown "Mch.MCU.WSG2.ShtShftShutDown";
BA_ "VssSig" SG_ 2566865185 Acmt "Mch.MCU.WSG2.Acmt";
BA_ "VssSig" SG_ 2566865185 TireTemp "Mch.MCU.WSG2.TireTemp";
BA_ "VssSig" SG_ 2566865185 FuelEmptyAddFuelTnk "Mch.MCU.WSG2.FuelEmptyAddFuelTnk";
BA_ "VssSig" SG_ 2566865185 ePowStp "Mch.MCU.WSG2.ePowStp";
BA_ "VssSig" SG_ 2566865185 ePowChk "Mch.MCU.WSG2.ePowChk";
BA_ "VssSig" SG_ 2566865185 CoolLv "Mch.MCU.WSG2.CoolLv";
BA_ "VssSig" SG_ 2566865185 DefPrsLw "Mch.MCU.WSG2.DefPrsLw";
BA_ "VssSig" SG_ 2566865185 WifMainFiltFault "Mch.MCU.WSG2.WifMainFiltFault";
BA_ "VssSig" SG_ 2566865185 WifMainFiltWaterDetectFault "Mch.MCU.WSG2.WifMainFiltWaterDetectFault";
BA_ "VssSig" SG_ 2566865185 WifPrePilotFault "Mch.MCU.WSG2.WifPrePilotFault";
BA_ "VssSig" SG_ 2566865185 WifPrePilot "Mch.MCU.WSG2.WifPrePilot";
BA_ "VssSig" SG_ 2566865185 FuelEmpty "Mch.MCU.WSG2.FuelEmpty";
BA_ "VssSig" SG_ 2566865185 AutoSCrcondPrkns "Mch.MCU.WSG2.AutoSCrcondPrkns";
BA_ "VssSig" SG_ 2566865185 ExHhTempAmb "Mch.MCU.WSG2.ExHhTempAmb";
BA_ "VssSig" SG_ 2566865185 ExHhTempGr "Mch.MCU.WSG2.ExHhTempGr";
BA_ "VssSig" SG_ 2566865185 DpfActRgnInhbtSt "Mch.MCU.WSG2.DpfActRgnInhbtSt";
BA_ "VssSig" SG_ 2566865185 DpfRgnClg "Mch.MCU.WSG2.DpfRgnClg";
BA_ "VssSig" SG_ 2566865185 EgChkSrv "Mch.MCU.WSG2.EgChkSrv";
BA_ "VssSig" SG_ 2566865185 EgChk2 "Mch.MCU.WSG2.EgChk2";
BA_ "VssSig" SG_ 2566865185 EgChk1 "Mch.MCU.WSG2.EgChk1";
BA_ "VssSig" SG_ 2566865185 EgStp "Mch.MCU.WSG2.EgStp";
BA_ "VssSig" SG_ 2566865185 EgWrn "Mch.MCU.WSG2.EgWrn";
BA_ "VssSig" SG_ 2566865185 AirCln "Mch.MCU.WSG2.AirCln";
BA_ "VssSig" SG_ 2566865185 CoolLvSrgTnk "Mch.MCU.WSG2.CoolLvSrgTnk";
BA_ "VssSig" SG_ 2566865185 CoolTmpOv "Mch.MCU.WSG2.CoolTmpOv";
BA_ "VssSig" SG_ 2566865185 EgOilPrs "Mch.MCU.WSG2.EgOilPrs";
BA_ "VssSig" SG_ 2566865441 RefPrs "Mch.MCU.WSG3.RefPrs";
BA_ "VssSig" SG_ 2566865441 TrmsSumpOilOvrHt "Mch.MCU.WSG3.TrmsSumpOilOvrHt";
BA_ "VssSig" SG_ 2566865441 TrmsRtdOilOvrHt "Mch.MCU.WSG3.TrmsRtdOilOvrHt";
BA_ "VssSig" SG_ 2566865441 TirePrs "Mch.MCU.WSG3.TirePrs";
BA_ "VssSig" SG_ 2566865441 HydOilWarmUp "Mch.MCU.WSG3.HydOilWarmUp";
BA_ "VssSig" SG_ 2566865441 GndSawRdy "Mch.MCU.WSG3.GndSawRdy";
BA_ "VssSig" SG_ 2566865441 TrvMotTempOh "Mch.MCU.WSG3.TrvMotTempOh";
BA_ "VssSig" SG_ 2566865441 QckCouplerLck "Mch.MCU.WSG3.QckCouplerLck";
BA_ "VssSig" SG_ 2566865441 BrkPdlSs "Mch.MCU.WSG3.BrkPdlSs";
BA_ "VssSig" SG_ 2566865441 AtsRgnReq "Mch.MCU.WSG3.AtsRgnReq";
BA_ "VssSig" SG_ 2566865441 TmsConSt "Mch.MCU.WSG3.TmsConSt";
BA_ "VssSig" SG_ 2566865441 QckCouplerUnlock "Mch.MCU.WSG3.QckCouplerUnlock";
BA_ "VssSig" SG_ 2566865441 RmvCntwt "Mch.MCU.WSG3.RmvCntwt";
BA_ "VssSig" SG_ 2566865441 FuelFilt "Mch.MCU.WSG3.FuelFilt";
BA_ "VssSig" SG_ 2566865441 UreaQualScr "Mch.MCU.WSG3.UreaQualScr";
BA_ "VssSig" SG_ 2566865441 UreaLv "Mch.MCU.WSG3.UreaLv";
BA_ "VssSig" SG_ 2566865697 BzzCtrlCmd "Mch.MCU.SIG1.BzzCtrlCmd";
BA_ "VssSig" SG_ 2566865697 CurGr "Mch.MCU.SIG1.CurGr";
BA_ "VssSig" SG_ 2566865697 SelGr "Mch.MCU.SIG1.SelGr";
BA_ "VssSig" SG_ 2566865697 BoomFltBiDir "Mch.MCU.SIG1.BoomFltBiDir";
BA_ "VssSig" SG_ 2566865697 Is3RdFNRElecStr "Mch.MCU.SIG1.Is3RdFNRElecStr";
BA_ "VssSig" SG_ 2566865697 IsFR "Mch.MCU.SIG1.IsFR";
BA_ "VssSig" SG_ 2566865697 IsElecStr "Mch.MCU.SIG1.IsElecStr";
BA_ "VssSig" SG_ 2566865697 IsOprRdy "Mch.MCU.SIG1.IsOprRdy";
BA_ "VssSig" SG_ 2566865697 PreHt "Mch.MCU.SIG1.PreHt";
BA_ "VssSig" SG_ 2566865697 FaultCntAvm "Mch.MCU.SIG1.FaultCntAvm";
BA_ "VssSig" SG_ 2566865697 FaultCntMch "Mch.MCU.SIG1.FaultCntMch";
BA_ "VssSig" SG_ 2566865697 CtrWrnLed "Mch.MCU.SIG1.CtrWrnLed";
BA_ "VssSig" SG_ 2566865697 ExBzz "Mch.MCU.SIG1.ExBzz";
BA_ "VssSig" SG_ 2566865697 AutoShdnAval "Mch.MCU.SIG1.AutoShdnAval";
BA_ "VssSig" SG_ 2566865697 AutoShdnSt "Mch.MCU.SIG1.AutoShdnSt";
BA_ "VssSig" SG_ 2566865697 BrkrAct "Mch.MCU.SIG1.BrkrAct";
BA_ "VssSig" SG_ 2566865697 ThwLvErr "Mch.MCU.SIG1.ThwLvErr";
BA_ "VssSig" SG_ 2566865697 AutoIdle "Mch.MCU.SIG1.AutoIdle";
BA_ "VssSig" SG_ 2566865697 RgnPrkns "Mch.MCU.SIG1.RgnPrkns";
BA_ "VssSig" SG_ 2566865697 RpmCtrlRstrt "Mch.MCU.SIG1.RpmCtrlRstrt";
BA_ "VssSig" SG_ 2566865697 IgnRstrtPilotCutOff "Mch.MCU.SIG1.IgnRstrtPilotCutOff";
BA_ "VssSig" SG_ 2566865697 IgnRstrtFRP "Mch.MCU.SIG1.IgnRstrtFRP";
BA_ "VssSig" SG_ 2566865697 OhPrv "Mch.MCU.SIG1.OhPrv";
BA_ "VssSig" SG_ 2566865697 HhMntLgc "Mch.MCU.SIG1.HhMntLgc";
BA_ "VssSig" SG_ 2566865697 AutoShdn "Mch.MCU.SIG1.AutoShdn";
BA_ "VssSig" SG_ 2566865697 FuelHt "Mch.MCU.SIG1.FuelHt";
BA_ "VssSig" SG_ 2566865697 AutoWarmUpGr "Mch.MCU.SIG1.AutoWarmUpGr";
BA_ "VssSig" SG_ 2566865697 AutoWarmUpAmb "Mch.MCU.SIG1.AutoWarmUpAmb";
BA_ "VssSig" SG_ 2566865697 HhBeam "Mch.MCU.SIG1.HhBeam";
BA_ "VssSig" SG_ 2566865697 RamLck "Mch.MCU.SIG1.RamLck";
BA_ "VssSig" SG_ 2566865697 PrkBrk "Mch.MCU.SIG1.PrkBrk";
BA_ "VssSig" SG_ 2566865697 Trv "Mch.MCU.SIG1.Trv";
BA_ "VssSig" SG_ 2566865697 FNR "Mch.MCU.SIG1.FNR";
BA_ "VssSig" SG_ 2566865697 TrvMdWhl "Mch.MCU.SIG1.TrvMdWhl";
BA_ "VssSig" SG_ 2566865697 IsoBhl "Mch.MCU.SIG1.IsoBhl";
BA_ "VssSig" SG_ 2566865697 TwOpt "Mch.MCU.SIG1.TwOpt";
BA_ "VssSig" SG_ 2566865697 WrkMd "Mch.MCU.SIG1.WrkMd";
BA_ "VssSig" SG_ 2566865697 TrvMdCrw "Mch.MCU.SIG1.TrvMdCrw";
BA_ "VssSig" SG_ 2566865697 MrrHt "Mch.MCU.SIG1.MrrHt";
BA_ "VssSig" SG_ 2566865697 AuxMdSt "Mch.MCU.SIG1.AuxMdSt";
BA_ "VssSig" SG_ 2566865697 RvsFanSt "Mch.MCU.SIG1.RvsFanSt";
BA_ "VssSig" SG_ 2566865697 SwPriSt "Mch.MCU.SIG1.SwPriSt";
BA_ "VssSig" SG_ 2566865697 BoomSwAct "Mch.MCU.SIG1.BoomSwAct";
BA_ "VssSig" SG_ 2566865697 BoomFltSngDir "Mch.MCU.SIG1.BoomFltSngDir";
BA_ "VssSig" SG_ 2566865697 PowMax "Mch.MCU.SIG1.PowMax";
BA_ "VssSig" SG_ 2566865697 WrkLmp "Mch.MCU.SIG1.WrkLmp";
BA_ "VssSig" SG_ 2566866209 WeighingMeasureWgh "Mch.MCU.GPG.WeighingMeasureWgh";
BA_ "VssSig" SG_ 2566866209 TrmsOilTmp "Mch.MCU.GPG.TrmsOilTmp";
BA_ "VssSig" SG_ 2566866209 VhcSpd "Mch.MCU.GPG.VhcSpd";
BA_ "VssSig" SG_ 2566866209 UreaLv "Mch.MCU.GPG.UreaLv";
BA_ "VssSig" SG_ 2566866209 FuelLv "Mch.MCU.GPG.FuelLv";
BA_ "VssSig" SG_ 2566866209 HydOilTmp "Mch.MCU.GPG.HydOilTmp";
BA_ "VssSig" SG_ 2566866209 CoolTmp "Mch.MCU.GPG.CoolTmp";
BA_ "VssSig" SG_ 2566866465 ArmAngInfo "Mch.MCU.UPD.ArmAngInfo";
BA_ "VssSig" SG_ 2566866465 McTprRlsSig "Mch.MCU.UPD.McTprRlsSig";
BA_ "VssSig" SG_ 2566866465 SetSwgBenchSig "Mch.MCU.UPD.SetSwgBenchSig";
BA_ "VssSig" SG_ 2566866465 BckRefPtSig "Mch.MCU.UPD.BckRefPtSig";
BA_ "VssSig" SG_ 2566866465 GrdAstMdSet "Mch.MCU.UPD.GrdAstMdSet";
BA_ "VssSig" SG_ 2566866465 DsnDepthCtrlMinusSig "Mch.MCU.UPD.DsnDepthCtrlMinusSig";
BA_ "VssSig" SG_ 2566866465 DsnDepthCtrlPlusSig "Mch.MCU.UPD.DsnDepthCtrlPlusSig";
BA_ "VssSig" SG_ 2566866465 DoubleGrdntCtrlMinusSig "Mch.MCU.UPD.DoubleGrdntCtrlMinusSig";
BA_ "VssSig" SG_ 2566866465 DoubleGrdntCtrlPlusSig "Mch.MCU.UPD.DoubleGrdntCtrlPlusSig";
BA_ "VssSig" SG_ 2566866465 DsnLoadMinusSig "Mch.MCU.UPD.DsnLoadMinusSig";
BA_ "VssSig" SG_ 2566866465 DsnLoadPlusSig "Mch.MCU.UPD.DsnLoadPlusSig";
BA_ "VssSig" SG_ 2566866465 UserDrawSetMinusSig "Mch.MCU.UPD.UserDrawSetMinusSig";
BA_ "VssSig" SG_ 2566866465 UserDrawSetPlusSig "Mch.MCU.UPD.UserDrawSetPlusSig";
BA_ "VssSig" SG_ 2566866465 GrdntCtrlMinusSig "Mch.MCU.UPD.GrdntCtrlMinusSig";
BA_ "VssSig" SG_ 2566866465 GrdntCtrlPlusSig "Mch.MCU.UPD.GrdntCtrlPlusSig";
BA_ "VssSig" SG_ 2566866465 BckAstSig "Mch.MCU.UPD.BckAstSig";
BA_ "VssSig" SG_ 2566866465 SwgAstRSig "Mch.MCU.UPD.SwgAstRSig";
BA_ "VssSig" SG_ 2566866465 SwgAstLSig "Mch.MCU.UPD.SwgAstLSig";
BA_ "VssSig" SG_ 2566866465 GrdAstPrecisionSelSig "Mch.MCU.UPD.GrdAstPrecisionSelSig";
BA_ "VssSig" SG_ 2566866465 GrdAstSig "Mch.MCU.UPD.GrdAstSig";
BA_ "VssSig" SG_ 2566866465 TruckCancelSig "Mch.MCU.UPD.TruckCancelSig";
BA_ "VssSig" SG_ 2566866465 TruckStoreSig "Mch.MCU.UPD.TruckStoreSig";
BA_ "VssSig" SG_ 2566866465 BckRecallSig "Mch.MCU.UPD.BckRecallSig";
BA_ "VssSig" SG_ 2566866465 BckCancelSig "Mch.MCU.UPD.BckCancelSig";
BA_ "VssSig" SG_ 2566866465 ReweighSig "Mch.MCU.UPD.ReweighSig";
BA_ "VssSig" SG_ 2566866465 WeighingSig "Mch.MCU.UPD.WeighingSig";
BA_ "VssSig" SG_ 2566866465 ReferencePtRlsSig "Mch.MCU.UPD.ReferencePtRlsSig";
BA_ "VssSig" SG_ 2566866465 LaserandTouchpointSig "Mch.MCU.UPD.LaserandTouchpointSig";
BA_ "VssSig" SG_ 2566866465 BmSig "Mch.MCU.UPD.BmSig";
BA_ "VssSig" SG_ 2566866465 CamSig "Mch.MCU.UPD.CamSig";
BA_ "VssSig" SG_ 2566866465 AdoMuteSig "Mch.MCU.UPD.AdoMuteSig";
BA_ "VssSig" SG_ 2566866465 MultifuncJoyBtnSig "Mch.MCU.UPD.MultifuncJoyBtnSig";
VAL_ 2348810243 OvrCtrlMdPri 0 "HIGHEST" 1 "HIGH" 2 "MEDIUM" 3 "LOW" ;
VAL_ 2348810243 EgOvrCtrlMd 0 "OVERRIDE_DISABLED" 1 "SPEED_CONTROL" 2 "TORQUE_CONTROL" 3 "SPEED_TORQUE_LIMIT_CONTROL" ;
VAL_ 2348810251 OvrCtrlMdPri 0 "HIGHEST" 1 "HIGH" 2 "MEDIUM" 3 "LOW" ;
VAL_ 2348810251 EgOvrCtrlMd 0 "OVERRIDE_DISABLED" 1 "SPEED_CONTROL" 2 "TORQUE_CONTROL" 3 "SPEED_TORQUE_LIMIT_CONTROL" ;
VAL_ 2348810259 OvrCtrlMdPri 0 "HIGHEST" 1 "HIGH" 2 "MEDIUM" 3 "LOW" ;
VAL_ 2348810259 EgOvrCtrlMd 0 "OVERRIDE_DISABLED" 1 "SPEED_CONTROL" 2 "TORQUE_CONTROL" 3 "SPEED_TORQUE_LIMIT_CONTROL" ;
VAL_ 2348810273 OvrCtrlMdPri 0 "HIGHEST" 1 "HIGH" 2 "MEDIUM" 3 "LOW" ;
VAL_ 2348810273 EgOvrCtrlMd 0 "OVERRIDE_DISABLED" 1 "SPEED_CONTROL" 2 "TORQUE_CONTROL" 3 "SPEED_TORQUE_LIMIT_CONTROL" ;
VAL_ 2564816912 AtRgnFrcSw 0 "OFF" 1 "ON" 2 "ERROR" 3 "NOT_AVAILABLE" ;
VAL_ 2564816912 AtRgnInhbSw 0 "OFF" 1 "ON" 2 "ERROR" 3 "NOT_AVAILABLE" ;
VAL_ 2564816929 AtRgnFrcSw 0 "OFF" 1 "ON" 2 "ERROR" 3 "NOT_AVAILABLE" ;
VAL_ 2564816929 AtRgnInhbSw 0 "OFF" 1 "ON" 2 "ERROR" 3 "NOT_AVAILABLE" ;
VAL_ 2565865733 EgAuxShdnSw 0 "OFF" 1 "ON" 2 "ERROR" 3 "NOT_AVAILABLE" ;
VAL_ 2565865739 EgAuxShdnSw 0 "OFF" 1 "ON" 2 "ERROR" 3 "NOT_AVAILABLE" ;
VAL_ 2364539395 InProTrmShft 0 "NOT_IN_PROCESS" 1 "PROCESS" ;
VAL_ 2364539395 TrqCvtLckEng 0 "TRQ_CVT_LOCKUP_DISENGAGED" 1 "TRQ_CVT_LOCKUP_ENGAGED" ;
VAL_ 2364539395 TrmDrvEng 0 "DRIVE_LINE_DISENGAGED" 1 "DRIVE_LINE_ENGAGED" 2 "ERROR" 3 "NOT AVAILABLE" ;
VAL_ 2565867011 DifLckStCtrEng 0 "FALSE" 1 "TRUE" 2 "ERROR" 3 "NOT_AVAILABLE" ;
VAL_ 2364542241 BladeAutoMdCmd 0 "AUTO_ALLOWED" 2 "SUSPEND_AUTO" 3 "SERVICE_MODE" 4 "AUTO_NOT_ALLOWED" 14 "ERROR" 15 "NOT_AVAILABLE" ;
VAL_ 2364542241 DsrGrdOfsSw 0 "NO_BUTTON_PRESSED" 1 "INCREMENT_BUTTON_PRESSED" 2 "DECREMENT_BUTTON_PRESSED" 14 "ERROR" 15 "NOT_AVAILABLE" ;
VAL_ 2364542241 BladeCtrlMdSw 0 "MANUAL" 1 "AUTO" 2 "ERROR" 3 "NOT_AVAILABLE" ;
VAL_ 2565869137 AtIntGasSsHtCtrl 0 "AUTOMATIC" 1 "PREHEAT_2" 2 "PREHEAT_1" 3 "HEATER_OFF" ;
VAL_ 2565869137 InRngAtIntGasSsTmp 0 "FALSE" 1 "TRUE" 2 "ERROR" 3 "NOT_AVAILABLE" ;
VAL_ 2565869394 AtOutGasSsHtCtrl 0 "AUTOMATIC" 1 "PREHEAT_2" 2 "PREHEAT_1" 3 "HEATER_OFF" ;
VAL_ 2565869394 InRngAtOutGasSsTmp 0 "FALSE" 1 "TRUE" 2 "ERROR" 3 "NOT_AVAILABLE" ;
VAL_ 2566757120 AtDefPpt 0 "UREA_CONCENTRATION_TOO_HIGH" 1 "UREA_CONCENTRATION_TOO_LOW" 2 "FLUID_IS_DIESEL" 3 "DEF_IS_PROPER_MIXTURE" 13 "NOT_ABLE_TO_DETERMINE" 14 "ERROR" 15 "NOT_AVAILABLE" ;
VAL_ 2566758656 AtIgn 0 "OFF" 1 "ON" 2 "ERROR" 3 "NOT_AVAILABLE" ;
VAL_ 2365468962 FailSafeMd 0 "BLOCK" 1 "EXTEND" 2 "RESERVED" 3 "DONT_CARE" ;
VAL_ 2365468962 VvSt 0 "BLOCK" 1 "EXTEND" 2 "RETRACT" 3 "FLOAT" 15 "NOT_AVAILABLE" ;
VAL_ 2365468962 ResolutionMd 0 "STANDARD_RESOLUTION" 1 "HIGH_RESOLUTION" 2 "RESERVED" 3 "DONT_CARE" ;
VAL_ 2365469218 FailSafeMd 0 "BLOCK" 1 "EXTEND" 2 "RESERVED" 3 "DONT_CARE" ;
VAL_ 2365469218 VvSt 0 "BLOCK" 1 "EXTEND" 2 "RETRACT" 3 "FLOAT" 15 "NOT_AVAILABLE" ;
VAL_ 2365469218 ResolutionMd 0 "STANDARD_RESOLUTION" 1 "HIGH_RESOLUTION" 2 "RESERVED" 3 "DONT_CARE" ;
VAL_ 2566852897 PrkBrkSw 0 "OFF" 1 "ON" 2 "ERROR" 3 "NOT_AVAILABLE" ;
VAL_ 2566852897 StartCtrlReq 0 "OFF" 1 "ON" 2 "ERROR" 3 "NOT_AVAILABLE" ;
VAL_ 2566852897 CCAccSw 0 "OFF" 1 "ON" 2 "ERROR" 3 "NOT_AVAILABLE" ;
VAL_ 2566852897 CCRsmSw 0 "OFF" 1 "ON" 2 "ERROR" 3 "NOT_AVAILABLE" ;
VAL_ 2566852897 CCCoastSw 0 "OFF" 1 "ON" 2 "ERROR" 3 "NOT_AVAILABLE" ;
VAL_ 2566852897 CCSetSw 0 "OFF" 1 "ON" 2 "ERROR" 3 "NOT_AVAILABLE" ;
VAL_ 2566852897 PtoSt 0 "OFF_DISABLED" 1 "HOLD" 2 "REMOTE_HOLD" 3 "STANDBY" 4 "REMOTE_STANDBY" 5 "SET" 6 "DECELERATE_COAST" 7 "RESUME" 8 "ACCELERATE" 9 "ACCELERATOR_OVERRIDE" 10 "PREPROGRAMMED_SET_SPEED_1" 11 "PREPROGRAMMED_SET_SPEED_2" 12 "PREPROGRAMMED_SET_SPEED_3" 13 "PREPROGRAMMED_SET_SPEED_4" 14 "PREPROGRAMMED_SET_SPEED_5" 15 "PREPROGRAMMED_SET_SPEED_6" 16 "PREPROGRAMMED_SET_SPEED_7" 17 "PREPROGRAMMED_SET_SPEED_8" 18 "PTO_SET_SPEED_MEMORY_1" 19 "PTO_SET_SPEED_MEMORY_2" 31 "NOT_AVAILABLE" ;
VAL_ 2566852897 RddtBrk 0 "OFF" 1 "ON" 2 "ERROR" 3 "NOT_AVAILABLE" ;
VAL_ 2566852897 BrkSw 0 "OFF" 1 "ON" 2 "ERROR" 3 "NOT_AVAILABLE" ;
VAL_ 2566852897 LisSw 0 "OFF" 1 "ON" 2 "ERROR" 3 "NOT_AVAILABLE" ;
VAL_ 2365527585 JoyEnbsignal 0 "INACTIVE" 1 "ACTIVE" 2 "RESERVED" 3 "NOT_AVAILABLE" ;
VAL_ 2365527841 JoyEnbsignal 0 "INACTIVE" 1 "ACTIVE" 2 "RESERVED" 3 "NOT_AVAILABLE" ;
VAL_ 2365528097 DirIndication 0 "FORWARD" 1 "REVERSE" 2 "ERROR" 3 "NOT_AVAILABLE" ;
VAL_ 2365528353 Drtindication 0 "FORWARD" 1 "REVERSE" 2 "ERROR" 3 "NOT_AVAILABLE" ;
VAL_ 2566856960 EdcOprSt 0 "NORMAL_OPERATION" 1 "AFTERRUN_DRIVE" 2 "DIAGNOSTIC_TEST" ;
VAL_ 2566856960 EgOilTmpHh 0 "NORMAL" 1 "ABOVE_OPERATION_RANGE" 2 "RESERVED" 3 "NOT_AVAILABLE" ;
VAL_ 2566856960 FuelFiltHtSt 0 "OFF" 1 "ON" 2 "ERROR" 3 "NOT_AVAILABLE" ;
VAL_ 2566856960 WifWrn 0 "NORMAL" 1 "WARNING" 2 "RESERVED" 3 "NOT_AVAILABLE" ;
VAL_ 2566856960 EgOilPrsLw 0 "NORMAL" 1 "BELOW_OPERATION_RANGE" 2 "RESERVED" 3 "NOT_AVAILABLE" ;
VAL_ 2566856960 BtnStp 0 "OFF" 1 "ON" 2 "ERROR" 3 "NOT_AVAILABLE" ;
VAL_ 2566856960 RgnLmp 0 "OFF" 1 "ON" 4 "BLINKING" ;
VAL_ 2566856960 HydPmpActReq 0 "OFF" 1 "ON" 2 "ERROR" 3 "NOT_AVAILABLE" ;
VAL_ 2566856960 MIL 0 "OFF" 1 "ON" 2 "BLINKING" 3 "NOT_AVAILABLE" ;
VAL_ 2566856960 EgOvrSpd 0 "NORMAL" 1 "ABOVE_OPERATION_RANGE" 2 "RESERVED" 3 "NOT_AVAILABLE" ;
VAL_ 2566856960 SpdLmtLmp 0 "OFF" 1 "ON" 2 "BLINKING" 3 "NOT_AVAILABLE" ;
VAL_ 2566856960 DiagLmp 0 "OFF" 1 "ON" 2 "BLINKING" 3 "NOT_AVAILABLE" ;
VAL_ 2566856960 FuelBlock 0 "FUEL_RELEASED" 1 "FUEL_BLOCKED" ;
VAL_ 2566856960 ColdStartHt 0 "OFF_PHASE_HEAT_OFF_AND_LAMP_OFF" 1 "PRE_HEATING_PHASE" 2 "STAND_BY_PHASE_WITH_HEATING" 3 "STAND_BY_PHASE_WITHOUT_HEATING" 4 "CRANK_PHASE" 5 "CRANK_WITH_EXTRA_HEATING_PHASE" 6 "POST_HEATING_PHASE" 7 "INITIALIZATION_PHASE" 8 "TEST_OF_GRID_HEATER_VOLTAGE" ;
VAL_ 2566859523 IsEngDrvSt 0 "FALSE" 1 "TRUE" 2 "ERROR" 3 "NOT_AVAILABLE" ;
VAL_ 2566859523 InProcShftSt 0 "FALSE" 1 "TRUE" 2 "ERROR" 3 "NOT_AVAILABLE" ;
VAL_ 2566859523 OpMd 0 "NORMAL" 1 "SUBSTITUTE_CLUTCH_CONTROL" 2 "LIMP_HOME" 3 "TRANSMISSION_SHUTDOWN" 4 "TCU_SHUTDOWN" 5 "TCU_KEY_OFF" 6 "TCU_IDLE" ;
VAL_ 2566859523 IsActJoyMd 0 "FALSE" 1 "TRUE" 2 "ERROR" 3 "NOT_AVAILABLE" ;
VAL_ 2566859523 CurDir 0 "N" 1 "F" 2 "R" 3 "TCU_REQUIRES_N_POSITION" ;
VAL_ 2566859523 CurGr 0 "NEUTRAL" 1 "GEAR_1" 2 "GEAR_2" 3 "GEAR_3" 4 "GEAR_4" 5 "GEAR_5" 6 "GEAR_6" 7 "LIMP_HOME" ;
VAL_ 2566859523 DifLck 0 "OFF" 1 "ON" 2 "ERROR" 3 "NOT_AVAILABLE" ;
VAL_ 2566859523 ShftDir 0 "N" 1 "F" 2 "R" 3 "TCU_REQUIRES_N_POSITION" ;
VAL_ 2566860833 ChgSt 0 "CHARGING" 1 "CHARGING_PORT_WARNING" 2 "CHARGING_GUN_WARNING" 3 "AC_VOLTAGE_ABOVE_NORMAL" 4 "AC_VOLTAGE_BELOW_NORMAL" 5 "EVSE_SIGNOT_AVAILABLEL_WARNING" ;
VAL_ 2566860833 MchKeyOnSt 0 "KEY_OFF" 1 "KEY_ON" 2 "KEY_OFF_CHARGING" 3 "NOT_DEFINED" ;
VAL_ 2566860833 OnBrdChgCmd 0 "DISABLE" 1 "ENABLE" ;
VAL_ 2566860833 QckChgEnableCmd 0 "DISABLE" 1 "ENABLE" ;
VAL_ 2566860833 PowDnCmd 0 "NOT_REQUEST" 1 "NORMAL_POWER_DOWN" 2 "EMERGENCY_POWER_DOWN" 3 "NOT_AVAILABLE" ;
VAL_ 2566863533 FanSt 0 "NOT_WORKING" 1 "WORKING" ;
VAL_ 2566864627 ChgSt 0 "STANDBY" 1 "CHARGING" 2 "FAILURE" 3 "COMPLETE" 4 "PAUSE" 5 "RESERVED" 6 "CHARGER_ERROR" 7 "NOT_AVAILABLE" ;
VAL_ 2566864627 HtPadSt 0 "OFF" 1 "ON_BOARD_CHARGER" ;
VAL_ 2566864627 BmsChgSType 0 "NONE" 1 "ON_BOARD_CHARGER" 2 "QUICK_CHARGER" 3 "NOT_AVAILABLE" ;
VAL_ 2566864929 InvOh 0 "OFF" 1 "ON" 2 "BLINKING" 3 "SLOW_BLINKING" ;
VAL_ 2566864929 MotOh 0 "OFF" 1 "ON" 2 "BLINKING" 3 "SLOW_BLINKING" ;
VAL_ 2566864929 BatOh 0 "OFF" 1 "ON" 2 "BLINKING" 3 "SLOW_BLINKING" ;
VAL_ 2566864929 Bms 0 "OFF" 1 "ON" 2 "BLINKING" 3 "SLOW_BLINKING" ;
VAL_ 2566864929 BatHt 0 "OFF" 1 "ON" 2 "BLINKING" 3 "SLOW_BLINKING" ;
VAL_ 2566864929 TrvlPdlFail 0 "OFF" 1 "ON" 2 "BLINKING" 3 "SLOW_BLINKING" ;
VAL_ 2566864929 RrWhlAlgn 0 "OFF" 1 "ON" 2 "BLINKING" 3 "SLOW_BLINKING" ;
VAL_ 2566864929 PrkBrkPrs 0 "OFF" 1 "ON" 2 "BLINKING" 3 "SLOW_BLINKING" ;
VAL_ 2566864929 TrsmOilFiltClog 0 "OFF" 1 "ON" 2 "BLINKING" 3 "SLOW_BLINKING" ;
VAL_ 2566864929 FanMotPrsLw 0 "OFF" 1 "ON" 2 "BLINKING" 3 "SLOW_BLINKING" ;
VAL_ 2566864929 OvSpd 0 "OFF" 1 "ON" 2 "BLINKING" 3 "SLOW_BLINKING" ;
VAL_ 2566864929 RBrkPdlNoCalb 0 "OFF" 1 "ON" 2 "BLINKING" 3 "SLOW_BLINKING" ;
VAL_ 2566864929 ElecStr 0 "OFF" 1 "ON" 2 "BLINKING" 3 "SLOW_BLINKING" ;
VAL_ 2566864929 EgOvr 0 "OFF" 1 "ON" 2 "BLINKING" 3 "SLOW_BLINKING" ;
VAL_ 2566864929 EmgStr 0 "OFF" 1 "ON" 2 "BLINKING" 3 "SLOW_BLINKING" ;
VAL_ 2566864929 SeatBelt 0 "OFF" 1 "ON" 2 "BLINKING" 3 "SLOW_BLINKING" ;
VAL_ 2566864929 TrsmOilOh 0 "OFF" 1 "ON" 2 "BLINKING" 3 "SLOW_BLINKING" ;
VAL_ 2566864929 Trsm 0 "OFF" 1 "ON" 2 "BLINKING" 3 "SLOW_BLINKING" ;
VAL_ 2566864929 VboEpprVvOut 0 "OFF" 1 "ON" 2 "BLINKING" 3 "SLOW_BLINKING" ;
VAL_ 2566864929 VboJoySs 0 "OFF" 1 "ON" 2 "BLINKING" 3 "SLOW_BLINKING" ;
VAL_ 2566864929 VboAngSs 0 "OFF" 1 "ON" 2 "BLINKING" 3 "SLOW_BLINKING" ;
VAL_ 2566864929 BatEq 0 "OFF" 1 "ON" 2 "BLINKING" 3 "SLOW_BLINKING" ;
VAL_ 2566864929 Uss 0 "OFF" 1 "ON" 2 "BLINKING" 3 "SLOW_BLINKING" ;
VAL_ 2566864929 IceptSs 0 "OFF" 1 "ON" 2 "BLINKING" 3 "SLOW_BLINKING" ;
VAL_ 2566864929 Str 0 "OFF" 1 "ON" 2 "BLINKING" 3 "SLOW_BLINKING" ;
VAL_ 2566864929 BrkOilPrsLw 0 "OFF" 1 "ON" 2 "BLINKING" 3 "SLOW_BLINKING" ;
VAL_ 2566864929 Ags 0 "OFF" 1 "ON" 2 "BLINKING" 3 "SLOW_BLINKING" ;
VAL_ 2566864929 Owd 0 "OFF" 1 "ON" 2 "BLINKING" 3 "SLOW_BLINKING" ;
VAL_ 2566864929 PilotFilt 0 "OFF" 1 "ON" 2 "BLINKING" 3 "SLOW_BLINKING" ;
VAL_ 2566864929 RetFilt 0 "OFF" 1 "ON" 2 "BLINKING" 3 "SLOW_BLINKING" ;
VAL_ 2566864929 HydOilOh 0 "OFF" 1 "ON" 2 "BLINKING" 3 "SLOW_BLINKING" ;
VAL_ 2566864929 BatChg 0 "OFF" 1 "ON" 2 "BLINKING" 3 "SLOW_BLINKING" ;
VAL_ 2566865185 AcleOilOh 0 "OFF" 1 "ON" 2 "BLINKING" 3 "SLOW_BLINKING" ;
VAL_ 2566865185 AxleOilOvrHtFr 0 "OFF" 1 "ON" 2 "BLINKING" 3 "SLOW_BLINKING" ;
VAL_ 2566865185 AxleOilOvrHtRr 0 "OFF" 1 "ON" 2 "BLINKING" 3 "SLOW_BLINKING" ;
VAL_ 2566865185 EgOilLv 0 "OFF" 1 "ON" 2 "BLINKING" 3 "SLOW_BLINKING" ;
VAL_ 2566865185 ShtShftShutDown 0 "OFF" 1 "ON" 2 "BLINKING" 3 "SLOW_BLINKING" ;
VAL_ 2566865185 Acmt 0 "OFF" 1 "ON" 2 "BLINKING" 3 "SLOW_BLINKING" ;
VAL_ 2566865185 TireTemp 0 "OFF" 1 "ON" 2 "BLINKING" 3 "SLOW_BLINKING" ;
VAL_ 2566865185 FuelEmptyAddFuelTnk 0 "OFF" 1 "ON" 2 "BLINKING" 3 "SLOW_BLINKING" ;
VAL_ 2566865185 ePowStp 0 "OFF" 1 "ON" 2 "BLINKING" 3 "SLOW_BLINKING" ;
VAL_ 2566865185 ePowChk 0 "OFF" 1 "ON" 2 "BLINKING" 3 "SLOW_BLINKING" ;
VAL_ 2566865185 CoolLv 0 "OFF" 1 "ON" 2 "BLINKING" 3 "SLOW_BLINKING" ;
VAL_ 2566865185 DefPrsLw 0 "OFF" 1 "ON" 2 "BLINKING" 3 "SLOW_BLINKING" ;
VAL_ 2566865185 WifMainFiltFault 0 "OFF" 1 "ON" 2 "BLINKING" 3 "SLOW_BLINKING" ;
VAL_ 2566865185 WifMainFiltWaterDetectFault 0 "OFF" 1 "ON" 2 "BLINKING" 3 "SLOW_BLINKING" ;
VAL_ 2566865185 WifPrePilotFault 0 "OFF" 1 "ON" 2 "BLINKING" 3 "SLOW_BLINKING" ;
VAL_ 2566865185 WifPrePilot 0 "OFF" 1 "ON" 2 "BLINKING" 3 "SLOW_BLINKING" ;
VAL_ 2566865185 FuelEmpty 0 "OFF" 1 "ON" 2 "BLINKING" 3 "SLOW_BLINKING" ;
VAL_ 2566865185 AutoSCrcondPrkns 0 "OFF" 1 "ON" 2 "BLINKING" 3 "SLOW_BLINKING" ;
VAL_ 2566865185 ExHhTempAmb 0 "OFF" 1 "ON" 2 "BLINKING" 3 "SLOW_BLINKING" ;
VAL_ 2566865185 ExHhTempGr 0 "OFF" 1 "ON" 2 "BLINKING" 3 "SLOW_BLINKING" ;
VAL_ 2566865185 DpfActRgnInhbtSt 0 "OFF" 1 "ON" 2 "BLINKING" 3 "SLOW_BLINKING" ;
VAL_ 2566865185 DpfRgnClg 0 "OFF" 1 "ON" 2 "BLINKING" 3 "SLOW_BLINKING" ;
VAL_ 2566865185 EgChkSrv 0 "OFF" 1 "ON" 2 "BLINKING" 3 "SLOW_BLINKING" ;
VAL_ 2566865185 EgChk2 0 "OFF" 1 "ON" 2 "BLINKING" 3 "SLOW_BLINKING" ;
VAL_ 2566865185 EgChk1 0 "OFF" 1 "ON" 2 "BLINKING" 3 "SLOW_BLINKING" ;
VAL_ 2566865185 EgStp 0 "OFF" 1 "ON" 2 "BLINKING" 3 "SLOW_BLINKING" ;
VAL_ 2566865185 EgWrn 0 "OFF" 1 "ON" 2 "BLINKING" 3 "SLOW_BLINKING" ;
VAL_ 2566865185 AirCln 0 "OFF" 1 "ON" 2 "BLINKING" 3 "SLOW_BLINKING" ;
VAL_ 2566865185 CoolLvSrgTnk 0 "OFF" 1 "ON" 2 "BLINKING" 3 "SLOW_BLINKING" ;
VAL_ 2566865185 CoolTmpOv 0 "OFF" 1 "ON" 2 "BLINKING" 3 "SLOW_BLINKING" ;
VAL_ 2566865185 EgOilPrs 0 "OFF" 1 "ON" 2 "BLINKING" 3 "SLOW_BLINKING" ;
VAL_ 2566865441 RefPrs 0 "OFF" 1 "ON_TEXT1" 2 "BLINKING_TEXT1" 3 "SLOW_BLINKING_TEXT1" 4 "NOT_DEFINED1" 5 "ON_TEXT3" 6 "BLINKING_TEXT3" 7 "SLOW_BLINKING_TEXT3" 8 "NOT_DEFINED2" 9 "ON_TEXT2" 10 "BLINKING_TEXT2" 11 "SLOW_BLINKING_TEXT2" 12 "NOT_DEFINED3" 13 "ON_TEXT4" 14 "BLINKING_TEXT4" 15 "SLOW_BLINKING_TEXT4" ;
VAL_ 2566865441 TrmsSumpOilOvrHt 0 "OFF" 1 "ON_TEXT1" 2 "BLINKING_TEXT1" 3 "SLOW_BLINKING_TEXT1" 4 "NOT_DEFINED1" 5 "ON_TEXT3" 6 "BLINKING_TEXT3" 7 "SLOW_BLINKING_TEXT3" 8 "NOT_DEFINED2" 9 "ON_TEXT2" 10 "BLINKING_TEXT2" 11 "SLOW_BLINKING_TEXT2" 12 "NOT_DEFINED3" 13 "ON_TEXT4" 14 "BLINKING_TEXT4" 15 "SLOW_BLINKING_TEXT4" ;
VAL_ 2566865441 TrmsRtdOilOvrHt 0 "OFF" 1 "ON_TEXT1" 2 "BLINKING_TEXT1" 3 "SLOW_BLINKING_TEXT1" 4 "NOT_DEFINED1" 5 "ON_TEXT3" 6 "BLINKING_TEXT3" 7 "SLOW_BLINKING_TEXT3" 8 "NOT_DEFINED2" 9 "ON_TEXT2" 10 "BLINKING_TEXT2" 11 "SLOW_BLINKING_TEXT2" 12 "NOT_DEFINED3" 13 "ON_TEXT4" 14 "BLINKING_TEXT4" 15 "SLOW_BLINKING_TEXT4" ;
VAL_ 2566865441 TirePrs 0 "OFF" 1 "ON_TEXT1" 2 "BLINKING_TEXT1" 3 "SLOW_BLINKING_TEXT1" 4 "NOT_DEFINED1" 5 "ON_TEXT3" 6 "BLINKING_TEXT3" 7 "SLOW_BLINKING_TEXT3" 8 "NOT_DEFINED2" 9 "ON_TEXT2" 10 "BLINKING_TEXT2" 11 "SLOW_BLINKING_TEXT2" 12 "NOT_DEFINED3" 13 "ON_TEXT4" 14 "BLINKING_TEXT4" 15 "SLOW_BLINKING_TEXT4" ;
VAL_ 2566865441 HydOilWarmUp 0 "OFF" 1 "ON_TEXT1" 2 "BLINKING_TEXT1" 3 "SLOW_BLINKING_TEXT1" 4 "NOT_DEFINED1" 5 "ON_TEXT3" 6 "BLINKING_TEXT3" 7 "SLOW_BLINKING_TEXT3" 8 "NOT_DEFINED2" 9 "ON_TEXT2" 10 "BLINKING_TEXT2" 11 "SLOW_BLINKING_TEXT2" 12 "NOT_DEFINED3" 13 "ON_TEXT4" 14 "BLINKING_TEXT4" 15 "SLOW_BLINKING_TEXT4" ;
VAL_ 2566865441 GndSawRdy 0 "OFF" 1 "ON_TEXT1" 2 "BLINKING_TEXT1" 3 "SLOW_BLINKING_TEXT1" 4 "NOT_DEFINED1" 5 "ON_TEXT3" 6 "BLINKING_TEXT3" 7 "SLOW_BLINKING_TEXT3" 8 "NOT_DEFINED2" 9 "ON_TEXT2" 10 "BLINKING_TEXT2" 11 "SLOW_BLINKING_TEXT2" 12 "NOT_DEFINED3" 13 "ON_TEXT4" 14 "BLINKING_TEXT4" 15 "SLOW_BLINKING_TEXT4" ;
VAL_ 2566865441 TrvMotTempOh 0 "OFF" 1 "ON_TEXT1" 2 "BLINKING_TEXT1" 3 "SLOW_BLINKING_TEXT1" 4 "NOT_DEFINED1" 5 "ON_TEXT3" 6 "BLINKING_TEXT3" 7 "SLOW_BLINKING_TEXT3" 8 "NOT_DEFINED2" 9 "ON_TEXT2" 10 "BLINKING_TEXT2" 11 "SLOW_BLINKING_TEXT2" 12 "NOT_DEFINED3" 13 "ON_TEXT4" 14 "BLINKING_TEXT4" 15 "SLOW_BLINKING_TEXT4" ;
VAL_ 2566865441 QckCouplerLck 0 "OFF" 1 "ON_TEXT1" 2 "BLINKING_TEXT1" 3 "SLOW_BLINKING_TEXT1" 4 "NOT_DEFINED1" 5 "ON_TEXT3" 6 "BLINKING_TEXT3" 7 "SLOW_BLINKING_TEXT3" 8 "NOT_DEFINED2" 9 "ON_TEXT2" 10 "BLINKING_TEXT2" 11 "SLOW_BLINKING_TEXT2" 12 "NOT_DEFINED3" 13 "ON_TEXT4" 14 "BLINKING_TEXT4" 15 "SLOW_BLINKING_TEXT4" ;
VAL_ 2566865441 BrkPdlSs 0 "OFF" 1 "ON_TEXT1" 2 "BLINKING_TEXT1" 3 "SLOW_BLINKING_TEXT1" 4 "NOT_DEFINED1" 5 "ON_TEXT3" 6 "BLINKING_TEXT3" 7 "SLOW_BLINKING_TEXT3" 8 "NOT_DEFINED2" 9 "ON_TEXT2" 10 "BLINKING_TEXT2" 11 "SLOW_BLINKING_TEXT2" 12 "NOT_DEFINED3" 13 "ON_TEXT4" 14 "BLINKING_TEXT4" 15 "SLOW_BLINKING_TEXT4" ;
VAL_ 2566865441 AtsRgnReq 0 "OFF" 1 "ON_TEXT1" 2 "BLINKING_TEXT1" 3 "SLOW_BLINKING_TEXT1" 4 "NOT_DEFINED1" 5 "ON_TEXT3" 6 "BLINKING_TEXT3" 7 "SLOW_BLINKING_TEXT3" 8 "NOT_DEFINED2" 9 "ON_TEXT2" 10 "BLINKING_TEXT2" 11 "SLOW_BLINKING_TEXT2" 12 "NOT_DEFINED3" 13 "ON_TEXT4" 14 "BLINKING_TEXT4" 15 "SLOW_BLINKING_TEXT4" ;
VAL_ 2566865441 TmsConSt 0 "OFF" 1 "ON_TEXT1" 2 "BLINKING_TEXT1" 3 "SLOW_BLINKING_TEXT1" 4 "NOT_DEFINED1" 5 "ON_TEXT3" 6 "BLINKING_TEXT3" 7 "SLOW_BLINKING_TEXT3" 8 "NOT_DEFINED2" 9 "ON_TEXT2" 10 "BLINKING_TEXT2" 11 "SLOW_BLINKING_TEXT2" 12 "NOT_DEFINED3" 13 "ON_TEXT4" 14 "BLINKING_TEXT4" 15 "SLOW_BLINKING_TEXT4" ;
VAL_ 2566865441 QckCouplerUnlock 0 "OFF" 1 "ON_TEXT1" 2 "BLINKING_TEXT1" 3 "SLOW_BLINKING_TEXT1" 4 "NOT_DEFINED1" 5 "ON_TEXT3" 6 "BLINKING_TEXT3" 7 "SLOW_BLINKING_TEXT3" 8 "NOT_DEFINED2" 9 "ON_TEXT2" 10 "BLINKING_TEXT2" 11 "SLOW_BLINKING_TEXT2" 12 "NOT_DEFINED3" 13 "ON_TEXT4" 14 "BLINKING_TEXT4" 15 "SLOW_BLINKING_TEXT4" ;
VAL_ 2566865441 RmvCntwt 0 "OFF" 1 "ON_TEXT1" 2 "BLINKING_TEXT1" 3 "SLOW_BLINKING_TEXT1" 4 "NOT_DEFINED1" 5 "ON_TEXT3" 6 "BLINKING_TEXT3" 7 "SLOW_BLINKING_TEXT3" 8 "NOT_DEFINED2" 9 "ON_TEXT2" 10 "BLINKING_TEXT2" 11 "SLOW_BLINKING_TEXT2" 12 "NOT_DEFINED3" 13 "ON_TEXT4" 14 "BLINKING_TEXT4" 15 "SLOW_BLINKING_TEXT4" ;
VAL_ 2566865441 FuelFilt 0 "OFF" 1 "ON_TEXT1" 2 "BLINKING_TEXT1" 3 "SLOW_BLINKING_TEXT1" 4 "NOT_DEFINED1" 5 "ON_TEXT3" 6 "BLINKING_TEXT3" 7 "SLOW_BLINKING_TEXT3" 8 "NOT_DEFINED2" 9 "ON_TEXT2" 10 "BLINKING_TEXT2" 11 "SLOW_BLINKING_TEXT2" 12 "NOT_DEFINED3" 13 "ON_TEXT4" 14 "BLINKING_TEXT4" 15 "SLOW_BLINKING_TEXT4" ;
VAL_ 2566865441 UreaQualScr 0 "OFF" 1 "ON_TEXT1" 2 "BLINKING_TEXT1" 3 "SLOW_BLINKING_TEXT1" 4 "NOT_DEFINED1" 5 "ON_TEXT3" 6 "BLINKING_TEXT3" 7 "SLOW_BLINKING_TEXT3" 8 "NOT_DEFINED2" 9 "ON_TEXT2" 10 "BLINKING_TEXT2" 11 "SLOW_BLINKING_TEXT2" 12 "NOT_DEFINED3" 13 "ON_TEXT4" 14 "BLINKING_TEXT4" 15 "SLOW_BLINKING_TEXT4" ;
VAL_ 2566865441 UreaLv 0 "OFF" 1 "ON_TEXT1" 2 "BLINKING_TEXT1" 3 "SLOW_BLINKING_TEXT1" 4 "NOT_DEFINED1" 5 "ON_TEXT3" 6 "BLINKING_TEXT3" 7 "SLOW_BLINKING_TEXT3" 8 "NOT_DEFINED2" 9 "ON_TEXT2" 10 "BLINKING_TEXT2" 11 "SLOW_BLINKING_TEXT2" 12 "NOT_DEFINED3" 13 "ON_TEXT4" 14 "BLINKING_TEXT4" 15 "SLOW_BLINKING_TEXT4" ;
VAL_ 2566865697 BzzCtrlCmd 0 "BUZZER_OFF" 1 "BUZZER_ON_STATE1" 2 "BUZZER_ON_STATE2" 3 "BUZZER_ON_STATE3" ;
VAL_ 2566865697 CurGr 0 "NEUTRAL" 1 "GEAR_1" 2 "GEAR_2" 3 "GEAR_3" 4 "GEAR_4" 5 "GEAR_5" 6 "GEAR_6" 7 "LIMP_HOME" ;
VAL_ 2566865697 SelGr 0 "NEUTRAL" 1 "GEAR_1" 2 "GEAR_2" 3 "GEAR_3" 4 "GEAR_4" 5 "GEAR_5" 6 "GEAR_6" 7 "LIMP_HOME" ;
VAL_ 2566865697 BoomFltBiDir 0 "DISABLE" 1 "ENABLE" ;
VAL_ 2566865697 Is3RdFNRElecStr 0 "DISABLE" 1 "ENABLE" ;
VAL_ 2566865697 IsFR 0 "DISABLE" 1 "ENABLE" ;
VAL_ 2566865697 IsElecStr 0 "DISABLE" 1 "ENABLE" ;
VAL_ 2566865697 IsOprRdy 0 "DISABLE" 1 "ENABLE" ;
VAL_ 2566865697 PreHt 0 "OFF" 1 "ON" 2 "ERROR" 3 "NOT_AVAILABLE" ;
VAL_ 2566865697 CtrWrnLed 0 "OFF" 1 "ON" 2 "ERROR" 3 "NOT_AVAILABLE" ;
VAL_ 2566865697 ExBzz 0 "OFF" 1 "ON" 2 "ERROR" 3 "NOT_AVAILABLE" ;
VAL_ 2566865697 AutoShdnAval 0 "DISABLE" 1 "ENABLE" ;
VAL_ 2566865697 AutoShdnSt 0 "DISABLE" 1 "ENABLE" ;
VAL_ 2566865697 BrkrAct 0 "STOP" 1 "RUNNING" 2 "FORCED_STOP" 3 "NOT_AVAILABLE" ;
VAL_ 2566865697 ThwLvErr 0 "OFF" 1 "ON" 2 "ERROR" 3 "NOT_AVAILABLE" ;
VAL_ 2566865697 AutoIdle 0 "OFF" 1 "ON" 2 "ERROR" 3 "NOT_AVAILABLE" ;
VAL_ 2566865697 RgnPrkns 0 "OFF" 1 "ON" 2 "ERROR" 3 "NOT_AVAILABLE" ;
VAL_ 2566865697 RpmCtrlRstrt 0 "OFF" 1 "ON" 2 "ERROR" 3 "NOT_AVAILABLE" ;
VAL_ 2566865697 IgnRstrtPilotCutOff 0 "OFF" 1 "ON" 2 "ERROR" 3 "NOT_AVAILABLE" ;
VAL_ 2566865697 IgnRstrtFRP 0 "OFF" 1 "ON" 2 "ERROR" 3 "NOT_AVAILABLE" ;
VAL_ 2566865697 OhPrv 0 "OFF" 1 "ON" 2 "ERROR" 3 "NOT_AVAILABLE" ;
VAL_ 2566865697 HhMntLgc 0 "OFF" 1 "3000M_OR_LESS" 2 "4000M_OR_LESS" 3 "4000M_EXCEED" ;
VAL_ 2566865697 AutoShdn 0 "OFF" 1 "ON" 2 "ERROR" 3 "NOT_AVAILABLE" ;
VAL_ 2566865697 FuelHt 0 "OFF" 1 "ON" 2 "ERROR" 3 "NOT_AVAILABLE" ;
VAL_ 2566865697 AutoWarmUpGr 0 "OFF" 1 "ON" 2 "ERROR" 3 "NOT_AVAILABLE" ;
VAL_ 2566865697 AutoWarmUpAmb 0 "OFF" 1 "ON" 2 "ERROR" 3 "NOT_AVAILABLE" ;
VAL_ 2566865697 HhBeam 0 "OFF" 1 "ON" 2 "ERROR" 3 "NOT_AVAILABLE" ;
VAL_ 2566865697 RamLck 0 "OFF" 1 "ON" 2 "ERROR" 3 "NOT_AVAILABLE" ;
VAL_ 2566865697 PrkBrk 0 "OFF" 1 "ON" 2 "ERROR" 3 "NOT_AVAILABLE" ;
VAL_ 2566865697 Trv 0 "OFF" 1 "ON" 2 "ERROR" 3 "NOT_AVAILABLE" ;
VAL_ 2566865697 FNR 0 "F" 1 "N" 2 "R" ;
VAL_ 2566865697 TrvMdWhl 0 "1" 1 "2" 2 "3" 3 "NOT_DEFINED" ;
VAL_ 2566865697 IsoBhl 0 "OFF" 1 "ISO" 2 "BHL" ;
VAL_ 2566865697 TwOpt 0 "NOT_DEFINED" 1 "JOYSTICK_THUMB_WHEEL" 2 "OPTION_PEDAL" ;
VAL_ 2566865697 WrkMd 0 "NOT_DEFINED" 1 "BREAKER" 2 "TWO_WAY" 3 "RESERVED" ;
VAL_ 2566865697 TrvMdCrw 0 "LOW_SPEED" 1 "HIGH_SPEED" 2 "AUTO_SPEED" 3 "NOT_AVAILABLE" ;
VAL_ 2566865697 MrrHt 0 "OFF" 1 "ON" 2 "ERROR" 3 "NOT_AVAILABLE" ;
VAL_ 2566865697 AuxMdSt 0 "OFF" 1 "ON" 2 "ERROR" 3 "NOT_AVAILABLE" ;
VAL_ 2566865697 RvsFanSt 0 "OFF" 1 "ON" 2 "ERROR" 3 "NOT_AVAILABLE" ;
VAL_ 2566865697 SwPriSt 0 "OFF" 1 "ON" 2 "ERROR" 3 "NOT_AVAILABLE" ;
VAL_ 2566865697 BoomSwAct 0 "OFF" 1 "ON" 2 "ERROR" 3 "NOT_AVAILABLE" ;
VAL_ 2566865697 BoomFltSngDir 0 "OFF" 1 "ON" 2 "ERROR" 3 "NOT_AVAILABLE" ;
VAL_ 2566865697 PowMax 0 "OFF" 1 "ON" 2 "ERROR" 3 "NOT_AVAILABLE" ;
VAL_ 2566865697 WrkLmp 0 "OFF" 1 "ON" 2 "ERROR" 3 "NOT_AVAILABLE" ;
